VERSION ""

NS_ :

BS_:

BU_: FR_CMR FD_E CLU DATC RR_C_RDR CGW

BO_ 298 ADAS_CMD_30_10ms: 16 FR_CMR
 SG_ LKA_OptUsmSta : 24|3@1+ (1,0) [0|0] ""  CLU,CGW
 SG_ LKA_RcgSta : 27|3@1+ (1,0) [0|0] ""  CLU,CGW
 SG_ LKA_LHLnWrnSta : 30|2@1+ (1,0) [0|0] ""  CLU,CGW
 SG_ LKA_RHLnWrnSta : 32|2@1+ (1,0) [0|0] ""  CLU,CGW
 SG_ LKA_HndsoffSnd : 34|2@1+ (1,0) [0|0] ""  CLU,CGW
 SG_ LKA_StrSnd : 36|2@1+ (1,0) [0|0] ""  CLU,CGW
 SG_ LKA_SysIndReq : 38|3@1+ (1,0) [0|0] ""  CLU,RR_C_RDR,CGW
 SG_ ADAS_ActToiSta : 52|2@1+ (1,0) [0|0] ""  CLU,CGW
 SG_ LKA_SysWrn : 60|4@1+ (1,0) [0|0] ""  CLU,CGW
 SG_ LKA_UsmMod : 80|2@1+ (1,0) [0|0] ""  CLU,CGW

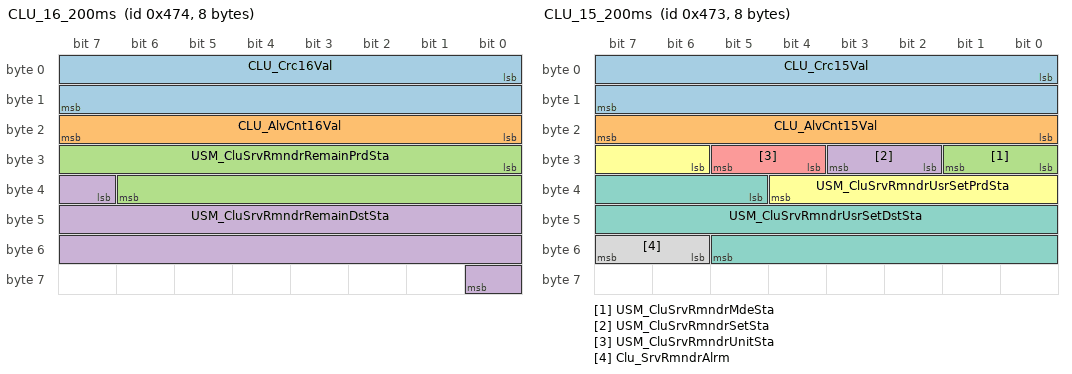
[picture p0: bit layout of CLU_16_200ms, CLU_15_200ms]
BO_ 1140 CLU_16_200ms: 8 CLU
 SG_ CLU_Crc16Val : 0|16@1+ (1,0) [0|0] ""  Vector__XXX
 SG_ CLU_AlvCnt16Val : 16|8@1+ (1,0) [0|0] ""  Vector__XXX
 SG_ USM_CluSrvRmndrRemainPrdSta : 24|15@1+ (1,0) [0|0] ""  CGW
 SG_ USM_CluSrvRmndrRemainDstSta : 39|18@1+ (1,0) [0|0] ""  CGW

BO_ 421 AWD_01_20ms: 32 CGW
 SG_ AWD_FrTqDistRto : 224|8@1+ (1,0) [0|0] "%"  CLU
 SG_ AWD_RrTqDistRto : 232|8@1+ (1,0) [0|0] "%"  CLU
 SG_ AWD_ErrCodeVal : 32|8@1+ (1,0) [0|0] ""  CLU
 SG_ AWD_OpModLkSta : 72|2@1+ (1,0) [0|0] ""  CLU

BO_ 1139 CLU_15_200ms: 8 CLU
 SG_ CLU_Crc15Val : 0|16@1+ (1,0) [0|0] ""  Vector__XXX
 SG_ CLU_AlvCnt15Val : 16|8@1+ (1,0) [0|0] ""  Vector__XXX
 SG_ USM_CluSrvRmndrMdeSta : 24|2@1+ (1,0) [0|0] ""  CGW
 SG_ USM_CluSrvRmndrSetSta : 26|2@1+ (1,0) [0|0] ""  CGW
 SG_ USM_CluSrvRmndrUnitSta : 28|2@1+ (1,0) [0|0] ""  CGW
 SG_ USM_CluSrvRmndrUsrSetPrdSta : 30|7@1+ (1,0) [0|0] ""  CGW
 SG_ USM_CluSrvRmndrUsrSetDstSta : 37|17@1+ (1,0) [0|0] ""  CGW
 SG_ Clu_SrvRmndrAlrm : 54|2@1+ (1,0) [0|0] ""  CGW

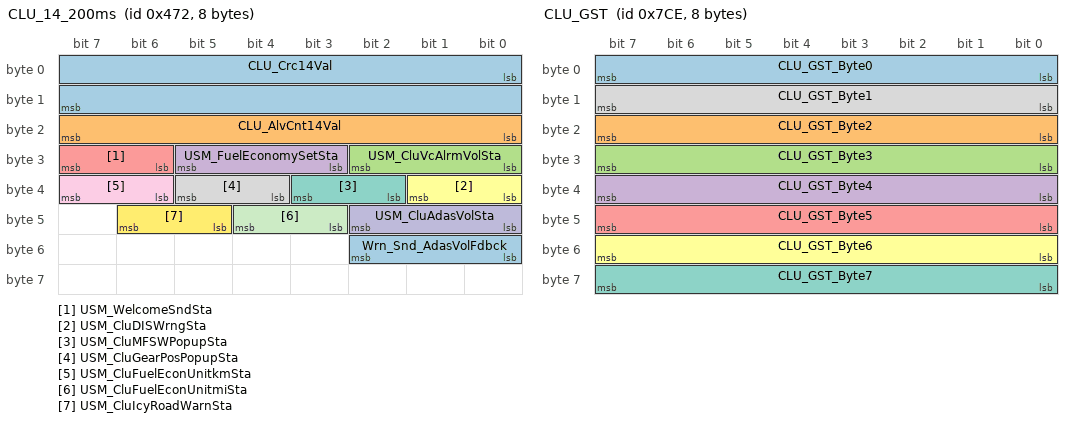
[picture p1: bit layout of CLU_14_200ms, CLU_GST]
BO_ 1138 CLU_14_200ms: 8 CLU
 SG_ CLU_Crc14Val : 0|16@1+ (1,0) [0|0] ""  Vector__XXX
 SG_ CLU_AlvCnt14Val : 16|8@1+ (1,0) [0|0] ""  Vector__XXX
 SG_ USM_CluVcAlrmVolSta : 24|3@1+ (1,0) [0|0] ""  CGW
 SG_ USM_FuelEconomySetSta : 27|3@1+ (1,0) [0|0] ""  CGW
 SG_ USM_WelcomeSndSta : 30|2@1+ (1,0) [0|0] ""  CGW
 SG_ USM_CluDISWrngSta : 32|2@1+ (1,0) [0|0] ""  CGW
 SG_ USM_CluMFSWPopupSta : 34|2@1+ (1,0) [0|0] ""  CGW
 SG_ USM_CluGearPosPopupSta : 36|2@1+ (1,0) [0|0] ""  CGW
 SG_ USM_CluFuelEconUnitkmSta : 38|2@1+ (1,0) [0|0] ""  CGW
 SG_ USM_CluAdasVolSta : 40|3@1+ (1,0) [0|0] ""  CGW
 SG_ USM_CluFuelEconUnitmiSta : 43|2@1+ (1,0) [0|0] ""  CGW
 SG_ USM_CluIcyRoadWarnSta : 45|2@1+ (1,0) [0|0] ""  CGW
 SG_ Wrn_Snd_AdasVolFdbck : 48|3@1+ (1,0) [0|0] ""  CGW

BO_ 1998 CLU_GST: 8 CLU
 SG_ CLU_GST_Byte0 : 0|8@1+ (1,0) [0|0] ""  CGW
 SG_ CLU_GST_Byte2 : 16|8@1+ (1,0) [0|0] ""  CGW
 SG_ CLU_GST_Byte3 : 24|8@1+ (1,0) [0|0] ""  CGW
 SG_ CLU_GST_Byte4 : 32|8@1+ (1,0) [0|0] ""  CGW
 SG_ CLU_GST_Byte5 : 40|8@1+ (1,0) [0|0] ""  CGW
 SG_ CLU_GST_Byte6 : 48|8@1+ (1,0) [0|0] ""  CGW
 SG_ CLU_GST_Byte7 : 56|8@1+ (1,0) [0|0] ""  CGW
 SG_ CLU_GST_Byte1 : 8|8@1+ (1,0) [0|0] ""  CGW

BO_ 898 DATC_05_200ms: 8 DATC
 SG_ DATC_TempDispUnitSta : 40|2@1+ (1,0) [0|0] ""  CLU,CGW

BO_ 181 EMS_01_10ms: 32 CGW
 SG_ ENG_IsgSta : 123|3@1+ (1,0) [0|0] ""  CLU,FR_CMR,DATC
 SG_ ENG_GearShftUpDis : 136|2@1+ (1,0) [0|0] ""  CLU
 SG_ ENG_GearShftDnDis : 138|2@1+ (1,0) [0|0] ""  CLU
 SG_ ENG_DsrGearPosDis : 140|4@1+ (1,0) [0|0] ""  CLU
 SG_ ENG_IsgBzrReq : 150|2@1+ (1,0) [0|0] ""  CLU
 SG_ ENG_Isg2Sta : 160|2@1+ (2,0) [0|0] ""  CLU
 SG_ ENG_EngSpdVal : 176|16@1+ (0.25,0) [0|0] "rpm"  CLU,FR_CMR
 SG_ ENG_FuelCnsmptVal : 200|16@1+ (0.128,0) [0|0] "ul"  CLU
 SG_ ENG_VehSpdLimVal : 247|9@1+ (1,0) [0|0] "km/h"  CLU
 SG_ ENG_EngSpdErrSta : 96|2@1+ (1,0) [0|0] ""  CLU,FR_CMR

BO_ 608 EMS_05_100ms: 32 CGW
 SG_ ENG_KNK_Warning : 228|1@1+ (1,0) [0|0] ""  CLU
 SG_ ENG_ImmoLmpSta : 24|2@1+ (1,0) [0|0] ""  CLU
 SG_ ENG_MilSta : 26|2@1+ (1,0) [0|0] ""  CLU

BO_ 64 TCU_01_10ms: 32 CGW
 SG_ TCU_EngRpmDisSta : 120|2@1+ (1,0) [0|0] ""  CLU
 SG_ TCU_EngRpmDis : 128|16@1+ (0.25,0) [0|0] "rpm"  CLU
 SG_ TCU_SprtyIndxSta : 155|5@1+ (1,0) [0|0] ""  CLU
 SG_ TCU_DrvngModDis : 160|3@1+ (1,0) [0|0] ""  CLU
 SG_ TCU_SmrtShftSta : 166|2@1+ (1,0) [0|0] ""  CLU
 SG_ TCU_ShftPtrnSta : 194|4@1+ (1,0) [0|0] ""  CLU
 SG_ TCU_GearSlctDis : 32|4@1+ (1,0) [0|0] ""  CLU,FR_CMR,RR_C_RDR
 SG_ TCU_Typ : 36|4@1+ (1,0) [0|0] ""  CLU
 SG_ TCU_TqRdctnVal : 40|12@1- (1,0) [0|0] "Nm"  CLU
 SG_ TCU_GearStepTyp : 56|4@1+ (1,0) [0|0] ""  CLU
 SG_ TCU_GearShftSta : 60|2@1+ (1,0) [0|0] ""  CLU
 SG_ TCU_CurrGearSta : 64|4@1+ (1,0) [0|0] ""  CLU
 SG_ TCU_TrgtGearSta : 68|4@1+ (1,0) [0|0] ""  CLU
 SG_ TCU_CluTrgtGearSta : 72|4@1+ (1,0) [0|0] ""  CLU
 SG_ TCU_CluTrgtGearConfg : 92|2@1+ (1,0) [0|0] ""  CLU

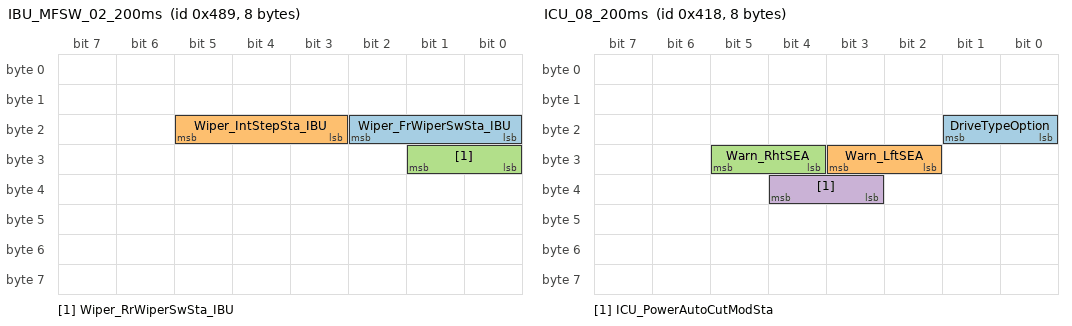
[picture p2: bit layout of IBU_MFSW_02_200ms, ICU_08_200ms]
BO_ 1161 IBU_MFSW_02_200ms: 8 CGW
 SG_ Wiper_FrWiperSwSta_IBU : 16|3@1+ (1,0) [0|0] ""  CLU
 SG_ Wiper_IntStepSta_IBU : 19|3@1+ (1,0) [0|0] ""  CLU
 SG_ Wiper_RrWiperSwSta_IBU : 24|2@1+ (1,0) [0|0] ""  CLU

BO_ 1160 IBU_MFSW_01_200ms: 8 CGW
 SG_ Lamp_LtSwSta_IBU : 20|2@1+ (1,0) [0|0] ""  CLU

BO_ 346 SCU_FF_01_10ms: 8 CGW
 SG_ SCU_FF_PosActSta : 24|4@1+ (1,0) [0|0] ""  CLU

BO_ 1167 ICU_11_1000ms: 8 CGW
 SG_ Bat_dischrg : 10|2@1+ (1,0) [0|0] ""  CLU

BO_ 1048 ICU_08_200ms: 8 CGW
 SG_ DriveTypeOption : 16|2@1+ (1,0) [0|0] ""  CLU
 SG_ Warn_LftSEA : 26|2@1+ (1,0) [0|0] ""  CLU
 SG_ Warn_RhtSEA : 28|2@1+ (1,0) [0|0] ""  CLU
 SG_ ICU_PowerAutoCutModSta : 35|2@1+ (1,0) [0|0] ""  CLU

BO_ 1050 BCM_07_200ms: 8 CGW
 SG_ Lamp_ExtrnlTailLmpOnReq : 38|2@1+ (1,0) [0|0] ""  CLU
 SG_ Lamp_AvTailLmpSta : 46|2@1+ (1,0) [0|0] ""  CLU

BO_ 325 DATC_01_20ms: 32 DATC
 SG_ DATC_OutTempSnsrVal : 168|8@1+ (0.5,-40) [0|0] "℃"  CLU,CGW

BO_ 1052 BCM_09_200ms: 8 CGW
 SG_ Lamp_AutoLtSnsrNightSta : 19|2@1+ (1,0) [0|0] ""  CLU,RR_C_RDR

BO_ 993 BCM_03_200ms: 8 CGW
 SG_ SBR_StBltWrngBzrSta : 16|3@1+ (1,0) [0|0] ""  CLU
 SG_ SBR_DrvStBltIndSta : 20|2@1+ (1,0) [0|0] ""  CLU

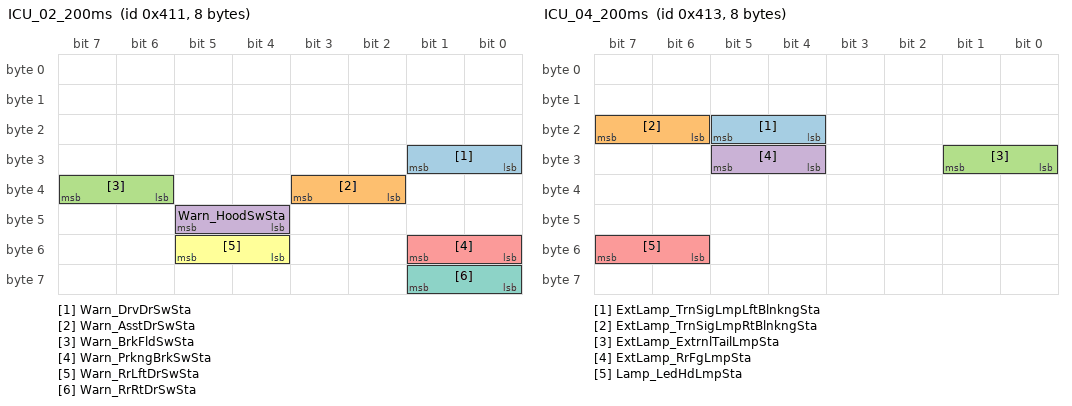
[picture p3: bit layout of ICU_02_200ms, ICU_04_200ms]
BO_ 1041 ICU_02_200ms: 8 CGW
 SG_ Warn_DrvDrSwSta : 24|2@1+ (1,0) [0|0] ""  CLU,FR_CMR
 SG_ Warn_AsstDrSwSta : 34|2@1+ (1,0) [0|0] ""  CLU,FR_CMR
 SG_ Warn_BrkFldSwSta : 38|2@1+ (1,0) [0|0] ""  CLU
 SG_ Warn_HoodSwSta : 44|2@1+ (1,0) [0|0] ""  CLU
 SG_ Warn_PrkngBrkSwSta : 48|2@1+ (1,0) [0|0] ""  CLU
 SG_ Warn_RrLftDrSwSta : 52|2@1+ (1,0) [0|0] ""  CLU,FR_CMR
 SG_ Warn_RrRtDrSwSta : 56|2@1+ (1,0) [0|0] ""  CLU,FR_CMR

BO_ 1040 ICU_10_200ms: 8 CGW
 SG_ ICU_BS2SoC : 16|8@1+ (1,0) [0|0] ""  CLU

BO_ 1043 ICU_04_200ms: 8 CGW
 SG_ ExtLamp_TrnSigLmpLftBlnkngSta : 20|2@1+ (1,0) [0|0] ""  CLU,FR_CMR,RR_C_RDR
 SG_ ExtLamp_TrnSigLmpRtBlnkngSta : 22|2@1+ (1,0) [0|0] ""  CLU,FR_CMR,RR_C_RDR
 SG_ ExtLamp_ExtrnlTailLmpSta : 24|2@1+ (1,0) [0|0] ""  CLU
 SG_ ExtLamp_RrFgLmpSta : 28|2@1+ (1,0) [0|0] ""  CLU
 SG_ Lamp_LedHdLmpSta : 54|2@1+ (1,0) [0|0] ""  CLU

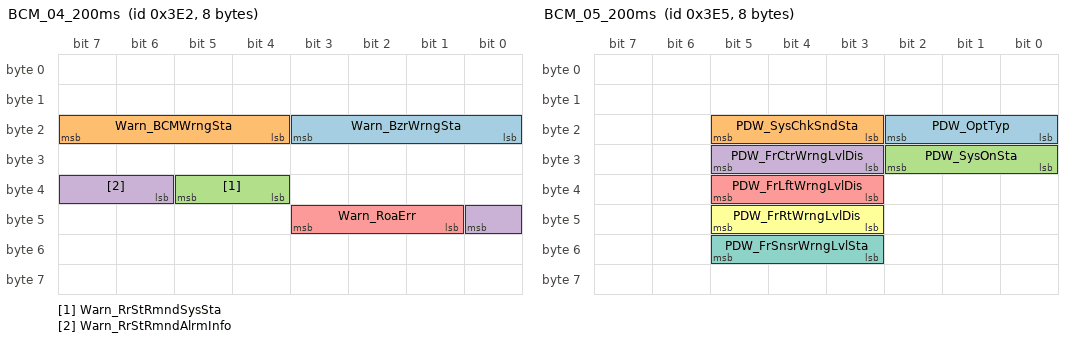
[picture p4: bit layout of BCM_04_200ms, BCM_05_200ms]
BO_ 994 BCM_04_200ms: 8 CGW
 SG_ Warn_BzrWrngSta : 16|4@1+ (1,0) [0|0] ""  CLU
 SG_ Warn_BCMWrngSta : 20|4@1+ (1,0) [0|0] ""  CLU
 SG_ Warn_RrStRmndSysSta : 36|2@1+ (1,0) [0|0] ""  CLU
 SG_ Warn_RrStRmndAlrmInfo : 38|3@1+ (1,0) [0|0] ""  CLU
 SG_ Warn_RoaErr : 41|3@1+ (1,0) [0|0] ""  CLU

BO_ 1042 ICU_03_200ms: 8 CGW
 SG_ ExtLamp_StpLmpLftOpnSta : 40|2@1+ (1,0) [0|0] ""  CLU
 SG_ ExtLamp_StpLmpRtOpnSta : 42|2@1+ (1,0) [0|0] ""  CLU

BO_ 997 BCM_05_200ms: 8 CGW
 SG_ PDW_OptTyp : 16|3@1+ (1,0) [0|0] ""  CLU
 SG_ PDW_SysChkSndSta : 19|3@1+ (1,0) [0|0] ""  CLU
 SG_ PDW_SysOnSta : 24|3@1+ (1,0) [0|0] ""  CLU
 SG_ PDW_FrCtrWrngLvlDis : 27|3@1+ (1,0) [0|0] ""  CLU
 SG_ PDW_FrLftWrngLvlDis : 35|3@1+ (1,0) [0|0] ""  CLU
 SG_ PDW_FrRtWrngLvlDis : 43|3@1+ (1,0) [0|0] ""  CLU
 SG_ PDW_FrSnsrWrngLvlSta : 51|3@1+ (1,0) [0|0] ""  CLU

BO_ 1044 ICU_05_200ms: 8 CGW
 SG_ Trunk_TrnkTlgtSwSta : 20|2@1+ (1,0) [0|0] ""  CLU
 SG_ USM_OneTouchTrnSigFuncSta : 34|3@1+ (1,0) [0|0] ""  CLU

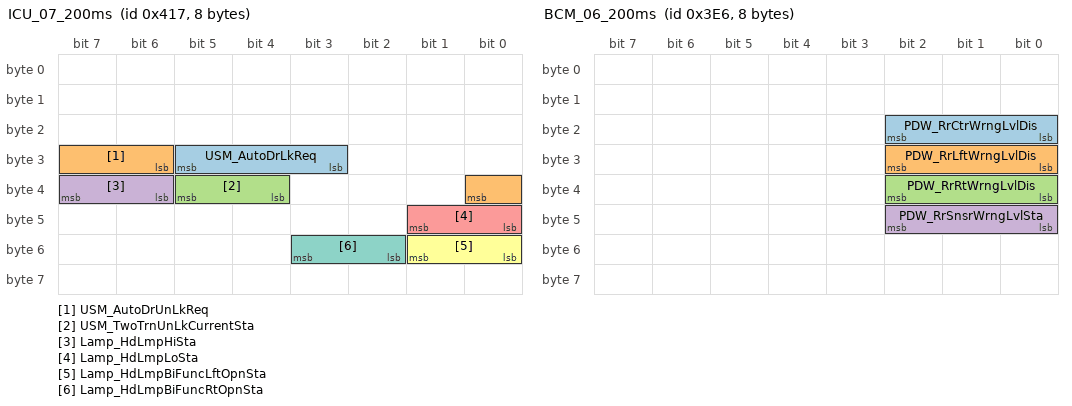
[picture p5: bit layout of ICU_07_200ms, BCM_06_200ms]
BO_ 1047 ICU_07_200ms: 8 CGW
 SG_ USM_AutoDrLkReq : 27|3@1+ (1,0) [0|0] ""  CLU
 SG_ USM_AutoDrUnLkReq : 30|3@1+ (1,0) [0|0] ""  CLU
 SG_ USM_TwoTrnUnLkCurrentSta : 36|2@1+ (1,0) [0|0] ""  CLU
 SG_ Lamp_HdLmpHiSta : 38|2@1+ (1,0) [0|0] ""  CLU,FR_CMR
 SG_ Lamp_HdLmpLoSta : 40|2@1+ (1,0) [0|0] ""  CLU
 SG_ Lamp_HdLmpBiFuncLftOpnSta : 48|2@1+ (1,0) [0|0] ""  CLU
 SG_ Lamp_HdLmpBiFuncRtOpnSta : 50|2@1+ (1,0) [0|0] ""  CLU

BO_ 998 BCM_06_200ms: 8 CGW
 SG_ PDW_RrCtrWrngLvlDis : 16|3@1+ (1,0) [0|0] ""  CLU
 SG_ PDW_RrLftWrngLvlDis : 24|3@1+ (1,0) [0|0] ""  CLU
 SG_ PDW_RrRtWrngLvlDis : 32|3@1+ (1,0) [0|0] ""  CLU
 SG_ PDW_RrSnsrWrngLvlSta : 40|3@1+ (1,0) [0|0] ""  CLU

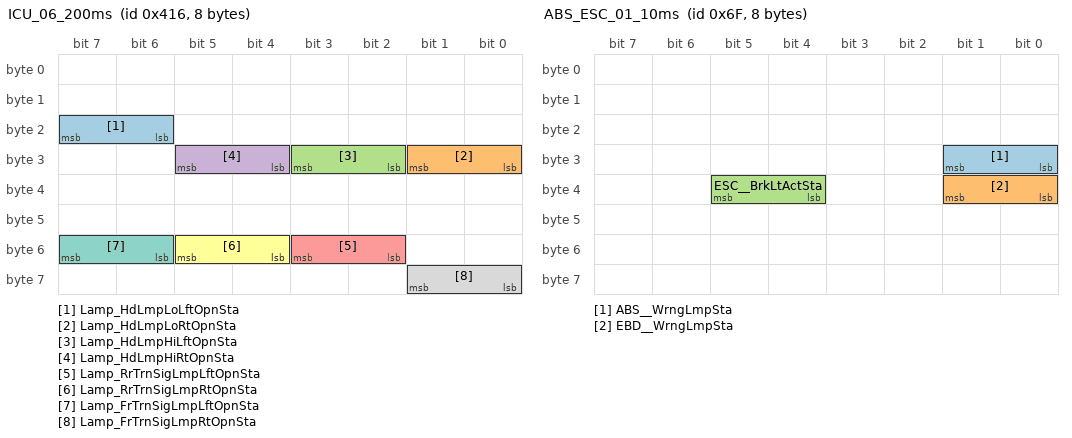
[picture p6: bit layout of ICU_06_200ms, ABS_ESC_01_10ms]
BO_ 1046 ICU_06_200ms: 8 CGW
 SG_ Lamp_HdLmpLoLftOpnSta : 22|2@1+ (1,0) [0|0] ""  CLU
 SG_ Lamp_HdLmpLoRtOpnSta : 24|2@1+ (1,0) [0|0] ""  CLU
 SG_ Lamp_HdLmpHiLftOpnSta : 26|2@1+ (1,0) [0|0] ""  CLU
 SG_ Lamp_HdLmpHiRtOpnSta : 28|2@1+ (1,0) [0|0] ""  CLU
 SG_ Lamp_RrTrnSigLmpLftOpnSta : 50|2@1+ (1,0) [0|0] ""  CLU
 SG_ Lamp_RrTrnSigLmpRtOpnSta : 52|2@1+ (1,0) [0|0] ""  CLU
 SG_ Lamp_FrTrnSigLmpLftOpnSta : 54|2@1+ (1,0) [0|0] ""  CLU
 SG_ Lamp_FrTrnSigLmpRtOpnSta : 56|2@1+ (1,0) [0|0] ""  CLU

BO_ 234 MDPS_01_10ms: 24 CGW
 SG_ MDPS_LoamModSta : 112|2@1+ (1,0) [0|0] ""  CLU
 SG_ MDPS_WrngLmpSta : 24|3@1+ (1,0) [0|0] ""  CLU

BO_ 96 ESC_01_10ms: 32 CGW
 SG_ AVH_CluDis : 208|8@1+ (1,0) [0|0] ""  CLU
 SG_ AVH_AlrmReq : 216|2@1+ (1,0) [0|0] ""  CLU
 SG_ AVH_LmpDis : 220|3@1+ (1,0) [0|0] ""  CLU
 SG_ TCS_LmpSta : 40|2@1+ (1,0) [0|0] ""  CLU
 SG_ TCS_OffLmpSta : 42|2@1+ (1,0) [0|0] ""  CLU
 SG_ ESC_OffTempSta : 44|2@1+ (1,0) [0|0] ""  CLU
 SG_ DBC_WrngLmpSta : 48|2@1+ (1,0) [0|0] ""  CLU
 SG_ DBC_FuncLmpSta : 50|2@1+ (1,0) [0|0] ""  CLU
 SG_ DBC_ClusterDis : 52|2@1+ (1,0) [0|0] ""  CLU
 SG_ DBC_Sta : 80|4@1+ (1,0) [0|0] ""  CLU

BO_ 1058 BCM_10_200ms: 8 CGW
 SG_ BCM_SunRoofOpnSta : 52|2@1+ (1,0) [0|0] ""  CLU,DATC

BO_ 111 ABS_ESC_01_10ms: 8 CGW
 SG_ ABS__WrngLmpSta : 24|2@1+ (1,0) [0|0] ""  CLU
 SG_ EBD__WrngLmpSta : 32|2@1+ (1,0) [0|0] ""  CLU
 SG_ ESC__BrkLtActSta : 36|2@1+ (1,0) [0|0] ""  CLU

BO_ 106 TCU_02_10ms: 32 CGW
 SG_ TCU_ActvEcoRdySta : 68|2@1+ (1,0) [0|0] ""  CLU

BO_ 496 EPB_01_50ms: 16 CGW
 SG_ EPB_LmpStaDis : 24|4@1+ (1,0) [0|0] ""  CLU
 SG_ EPB_FlrLmpStaDis : 28|4@1+ (1,0) [0|0] ""  CLU
 SG_ EPB_OutDataDis : 32|8@1+ (1,0) [0|0] ""  CLU
 SG_ EPB_AlrmReq : 40|2@1+ (1,0) [0|0] ""  CLU

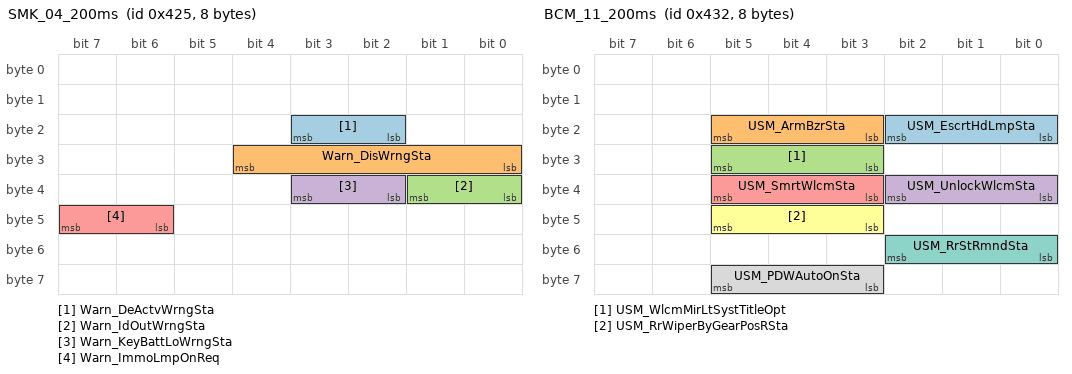
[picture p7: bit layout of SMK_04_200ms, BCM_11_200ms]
BO_ 1061 SMK_04_200ms: 8 CGW
 SG_ Warn_DeActvWrngSta : 18|2@1+ (1,0) [0|0] ""  CLU
 SG_ Warn_DisWrngSta : 24|5@1+ (1,0) [0|0] ""  CLU
 SG_ Warn_IdOutWrngSta : 32|2@1+ (1,0) [0|0] ""  CLU
 SG_ Warn_KeyBattLoWrngSta : 34|2@1+ (1,0) [0|0] ""  CLU
 SG_ Warn_ImmoLmpOnReq : 46|2@1+ (1,0) [0|0] ""  CLU

BO_ 352 ADAS_CMD_10_20ms: 16 FR_CMR
 SG_ FCA_OnOffEquipSta : 24|3@1+ (1,0) [0|0] ""  CLU,CGW
 SG_ FCA_SysFlrSta : 27|3@1+ (1,0) [0|0] ""  CLU,CGW
 SG_ FCA_WrngLvlSta : 30|2@1+ (1,0) [0|0] ""  CLU,CGW
 SG_ FCA_VehStpReq : 32|2@1+ (1,0) [0|0] ""  CLU,CGW
 SG_ FCA_SnstvtyModRetVal : 56|3@1+ (1,0) [0|0] ""  CLU,CGW
 SG_ FCA_WrngTrgtDis : 88|5@1+ (1,0) [0|0] ""  CLU,CGW

BO_ 720 TCU_03_100ms: 32 CGW
 SG_ TCU_WrngMsgSta : 24|8@1+ (1,0) [0|0] ""  CLU
 SG_ TCU_VehStpTimeDis : 32|5@1+ (1,0) [0|0] ""  CLU
 SG_ TCU_CurCltTemp : 64|2@1+ (1,0) [0|0] ""  CLU
 SG_ TCU_AvgCltTemp : 66|4@1+ (1,0) [0|0] ""  CLU
 SG_ DCT_HillHldWrng : 80|2@1+ (1,0) [0|0] ""  CLU
 SG_ DCT_CltchBrstWrng : 82|2@1+ (1,0) [0|0] ""  CLU
 SG_ DCT_WrngSndSta : 84|4@1+ (1,0) [0|0] ""  CLU

BO_ 485 RR_C_RDR_01_50ms: 16 RR_C_RDR
 SG_ RCCW_Sta : 24|4@1+ (1,0) [0|0] ""  CLU,CGW
 SG_ RCCW_OnOffEquipSt : 28|2@1+ (1,0) [0|0] ""  CLU,CGW
 SG_ RCCW_LftIndSta : 30|2@1+ (1,0) [0|0] ""  CLU,CGW
 SG_ RCCW_RtIndSta : 32|2@1+ (1,0) [0|0] ""  CLU,CGW
 SG_ RCCW_LftSndWrngSta : 34|2@1+ (1,0) [0|0] ""  CLU,CGW
 SG_ RCCW_RtSndWrngSta : 36|2@1+ (1,0) [0|0] ""  CLU,CGW
 SG_ RCCW_LftWrngIndBriLvlVal : 40|8@1+ (1,0) [0|0] ""  CLU,CGW
 SG_ RCCW_RtWrngIndBriLvlVal : 48|8@1+ (1,0) [0|0] ""  CLU,CGW
 SG_ RCCA_LftWrngSta : 70|2@1+ (1,0) [0|0] ""  CLU,CGW
 SG_ RCCA_RtWrngSta : 72|2@1+ (1,0) [0|0] ""  CLU,CGW
 SG_ RCCA_FuncStat : 77|2@1+ (1,0) [0|0] ""  CLU,CGW
 SG_ RCCA_Sta : 80|4@1+ (1,0) [0|0] ""  CLU,CGW
 SG_ RCCA_OnOffEquipSt : 84|2@1+ (1,0) [0|0] ""  CLU,CGW
 SG_ SEA_Sta : 88|4@1+ (1,0) [0|0] ""  CLU,CGW
 SG_ SEA_OnOffEquipSta : 92|2@1+ (1,0) [0|0] ""  CLU,CGW
 SG_ SEA_LftWrngSta : 94|2@1+ (1,0) [0|0] ""  CLU,CGW
 SG_ SEA_RtWrngSta : 96|2@1+ (1,0) [0|0] ""  CLU,CGW

BO_ 1074 BCM_11_200ms: 8 CGW
 SG_ USM_EscrtHdLmpSta : 16|3@1+ (1,0) [0|0] ""  CLU
 SG_ USM_ArmBzrSta : 19|3@1+ (1,0) [0|0] ""  CLU
 SG_ USM_WlcmMirLtSystTitleOpt : 27|3@1+ (1,0) [0|0] ""  CLU
 SG_ USM_UnlockWlcmSta : 32|3@1+ (1,0) [0|0] ""  CLU
 SG_ USM_SmrtWlcmSta : 35|3@1+ (1,0) [0|0] ""  CLU
 SG_ USM_RrWiperByGearPosRSta : 43|3@1+ (1,0) [0|0] ""  CLU
 SG_ USM_RrStRmndSta : 48|3@1+ (1,0) [0|0] ""  CLU
 SG_ USM_PDWAutoOnSta : 59|3@1+ (1,0) [0|0] ""  CLU

BO_ 480 ADAS_CMD_31_50ms: 16 FR_CMR
 SG_ HDA_OptUsmSta : 24|3@1+ (1,0) [0|0] ""  CLU,CGW
 SG_ HDA_CntrlModSta : 30|2@1+ (1,0) [0|0] ""  CLU,CGW
 SG_ HDA_InfoPUDis : 32|3@1+ (1,0) [0|0] ""  CLU,CGW
 SG_ HDA_LFA_SymSta : 47|2@1+ (1,0) [0|0] ""  CLU,CGW
 SG_ HDA_LFA_WrnSnd : 49|2@1+ (1,0) [0|0] ""  CLU,CGW
 SG_ HDA_InfoPUDis1 : 51|3@1+ (1,0) [0|0] ""  CLU,CGW

CM_ BO_ 111 "[P] Periodic";
CM_ SG_ 111 ABS__WrngLmpSta "ABS_WarningLampStatus ##2G##ESC - TCS15 - ABS_W_LAMP";
CM_ SG_ 111 EBD__WrngLmpSta "EBD_WarningLampStatus ##2G##ESC - TCS15 - EBD_W_LAMP";
CM_ SG_ 111 ESC__BrkLtActSta "ESC_BrakeLightActiveStatus ##2G##ESC - TCS11 - BLA_CTL";
CM_ BO_ 352 "[P] Periodic";
CM_ SG_ 352 FCA_OnOffEquipSta "FCA_OnOffEquipmentStatus ##2G##FCA - FCA12 - FCA_USM";
CM_ SG_ 352 FCA_SysFlrSta "FCA_SystemFailureStatus ##2G##FCA - FCA11 - FCA_Failinfo";
CM_ SG_ 352 FCA_WrngLvlSta "FCA_WarningLevelStatus ##2G##FCA - FCA11 - CF_VSM_Warn";
CM_ SG_ 352 FCA_VehStpReq "FCA_VehicleStopRequest ##2G##FCA - FCA11 - FCA_StopReq";
CM_ SG_ 352 FCA_SnstvtyModRetVal "FCA_SensitivityModeReturnValue ##2G##FCA - FCA12 - FCA_DrvSetState";
CM_ SG_ 352 FCA_WrngTrgtDis "FCA_WarningTargetDisplay";
CM_ BO_ 298 "[P] Periodic";
CM_ SG_ 298 LKA_OptUsmSta "LKA_OptionUsmStatus ##2G##LDW_LKA - LKA11 - CF_LKA_Opt_USM";
CM_ SG_ 298 LKA_RcgSta "LKA_RecognitionStatus ##2G##LDW_LKA - LKA11 - CF_LKA_LaneRecogState";
CM_ SG_ 298 LKA_LHLnWrnSta "LKA_LHLaneWarningStatus ##2G##LDW_LKA - LKA11 - CF_LKA_LHWarning";
CM_ SG_ 298 LKA_RHLnWrnSta "LKA_RHLaneWarningStatus ##2G##LDW_LKA - LKA11 - CF_LKA_RHWarning";
CM_ SG_ 298 LKA_HndsoffSnd "LKA_HandsoffSound ##2G##LDW_LKA - LKA11 - CF_LKA_HandsOff_Snd";
CM_ SG_ 298 LKA_StrSnd "LKA_SteeringSound ##2G##LDW_LKA - LKA11 - CF_LKA_Steer_Snd";
CM_ SG_ 298 LKA_SysIndReq "LKA_SystemIndicatorRequest ##2G##LDW_LKA - LKA11 - CF_LKA_SymbolState";
CM_ SG_ 298 ADAS_ActToiSta "ADAS_ActiveTorqueOverlayInterfaceStatus ##2G##LDW_LKA - LKA11 - CF_LKA_ActToi";
CM_ SG_ 298 LKA_SysWrn "LKA_Additional_Info";
CM_ SG_ 298 LKA_UsmMod "LKA_USM Mode ##2G##LDW_LKA-LKA11-CF_LKA_USM_Mode";
CM_ BO_ 480 "[P] Periodic";
CM_ SG_ 480 HDA_OptUsmSta "HDA_OptionUSMStatus ##2G##LDW_LKA - HDA11 - CF_HDA_Opt_USM";
CM_ SG_ 480 HDA_CntrlModSta "HDA_ControlModeStatus ##2G##LDW_LKA - HDA11 - CF_HDA_Mode";
CM_ SG_ 480 HDA_InfoPUDis "HDA_InformationPopUpDisplay ##2G##LDW_LKA - HDA11 - CF_HDA_InfoDisplay";
CM_ SG_ 480 HDA_LFA_SymSta "HDA_LFA_SymbolStatus ##2G##LDW_LKA - HDA11 - CF_HDA_LFA_SymbolState";
CM_ SG_ 480 HDA_LFA_WrnSnd "HDA/LFA Additional Warning Sound";
CM_ SG_ 480 HDA_InfoPUDis1 "HDA_InfomationPopupDisplay";
CM_ BO_ 421 "[P] Periodic";
CM_ SG_ 421 AWD_FrTqDistRto "Torque Distribution ratio to Front Wheel";
CM_ SG_ 421 AWD_RrTqDistRto "Torque Distribution ratio to Rear Wheel";
CM_ SG_ 421 AWD_ErrCodeVal "AWD_ErrorCodeValue";
CM_ SG_ 421 AWD_OpModLkSta "AWD_OperationModeLockStatus";
CM_ BO_ 993 "[PE] Periodic and On Event";
CM_ SG_ 993 SBR_StBltWrngBzrSta "SBR_SeatBeltWarningBuzzerStatus ##2G##BCM - BCMmsg32 - C_SeatBeltWngBuz";
CM_ SG_ 993 SBR_DrvStBltIndSta "SBR_DriverSeatBeltIndicatorStatus ##2G##BCM - BCMmsg32 - C_DrvSeatBeltInd";
CM_ BO_ 994 "[PE] Periodic and On Event";
CM_ SG_ 994 Warn_BzrWrngSta "Warn_BuzzerWarningStatus ##2G##BCM - BCMmsg18 - C_WngBuz";
CM_ SG_ 994 Warn_BCMWrngSta "Warn_BCMWarningStatus ##2G##BCM - BCMmsg19 - C_BCMWarning";
CM_ SG_ 994 Warn_RrStRmndSysSta "Warn_RearSeatReminderSystemStatus ##2G##BCM - BCMmsg22 - C_RrSeatRemindState";
CM_ SG_ 994 Warn_RrStRmndAlrmInfo "Warn_RearSeatReminderAlarmInformaion ##2G##BCM - BCMmsg22 - C_RrSeatRemindInfo";
CM_ SG_ 994 Warn_RoaErr "Warn_RoaError##2G##BCM - BCMmsg22 - C_RoaError";
CM_ BO_ 997 "[PE] Periodic and On Event";
CM_ SG_ 997 PDW_OptTyp "PDW_OptionType ##2G##BCM - BCMmsg18 - C_PASOption";
CM_ SG_ 997 PDW_SysChkSndSta "PDW_SystemCheckSoundStatus ##2G##BCM - BCMmsg18 - C_PASCheckSound";
CM_ SG_ 997 PDW_SysOnSta "PDW_SystemOnStatus ##2G##BCM - BCMmsg18 - C_PASSystemOn";
CM_ SG_ 997 PDW_FrCtrWrngLvlDis "PDW_FrontCenterWarningLevelDisplay ##2G##BCM - BCMmsg18 - C_PASDisplayFCTR";
CM_ SG_ 997 PDW_FrLftWrngLvlDis "PDW_FrontLeftWarningLevelDisplay ##2G##BCM - BCMmsg18 - C_PASDisplayFLH";
CM_ SG_ 997 PDW_FrRtWrngLvlDis "PDW_FrontRightWarningLevelDisplay ##2G##BCM - BCMmsg18 - C_PASDisplayFRH";
CM_ SG_ 997 PDW_FrSnsrWrngLvlSta "PDW_FrontSensorWarningLevelStatus ##2G##BCM - BCMmsg18 - C_PASFsound";
CM_ BO_ 998 "[PE] Periodic and On Event";
CM_ SG_ 998 PDW_RrCtrWrngLvlDis "PDW_RearCenterWarningLevelDisplay ##2G##BCM - BCMmsg18 - C_PASDisplayRCTR";
CM_ SG_ 998 PDW_RrLftWrngLvlDis "PDW_RearLeftWarningLevelDisplay ##2G##BCM - BCMmsg18 - C_PASDisplayRLH";
CM_ SG_ 998 PDW_RrRtWrngLvlDis "PDW_RearRightWarningLevelDisplay ##2G##BCM - BCMmsg18 - C_PASDisplayRRH";
CM_ SG_ 998 PDW_RrSnsrWrngLvlSta "PDW_RearSensorWarningLevelStatus ##2G##BCM - BCMmsg18 - C_PASRsound";
CM_ BO_ 1050 "[PE] Periodic and On Event";
CM_ SG_ 1050 Lamp_ExtrnlTailLmpOnReq "Lamp_ExternalTailLampOnRequest ##2G##BCM - BCMmsg19 - C_ExtTailOn";
CM_ SG_ 1050 Lamp_AvTailLmpSta "Lamp_AvTailLampStatus ##2G##BCM - BCMmsg18 - C_AvTail";
CM_ BO_ 1052 "[PE] Periodic and On Event";
CM_ SG_ 1052 Lamp_AutoLtSnsrNightSta "Lamp_AutoLightSensorNightStatus ##2G##BCM - BCMmsg24 - C_AutolightValue";
CM_ BO_ 1058 "[PE] Periodic and On Event";
CM_ SG_ 1058 BCM_SunRoofOpnSta "BCM_SunRoofOpenStatus ##2G##BCM - BCMmsg20 - C_SunRoofOpenState";
CM_ BO_ 1074 "[PE] Periodic and On Event";
CM_ SG_ 1074 USM_EscrtHdLmpSta "USM_EscortHeadLampStatus ##2G##BCM - BCMmsg21 - C_EscortHLRValue";
CM_ SG_ 1074 USM_ArmBzrSta "USM_ArmBuzzerStatus ##2G##BCM - BCMmsg21 - C_HAnBRValue";
CM_ SG_ 1074 USM_WlcmMirLtSystTitleOpt "USM_WelcomeMirrLightSystemTitleOption ##2G##BCM - BCMmsg21 - C_WelcomeSysTitleOption";
CM_ SG_ 1074 USM_UnlockWlcmSta "USM_UnlockWelcomeStatus ##2G##BCM - BCMmsg21 - C_UnlockWelcomeRValue";
CM_ SG_ 1074 USM_SmrtWlcmSta "USM_SmartWelcomeStatus ##2G##BCM - BCMmsg21 - C_SmartWelcomeRValue";
CM_ SG_ 1074 USM_RrWiperByGearPosRSta "USM_RearWiperByGearPositionReverseStatus ##2G##BCM - BCMmsg21 - C_RearWiperRValue";
CM_ SG_ 1074 USM_RrStRmndSta "USM_RearSeatReminderStatus ##2G##BCM - BCMmsg21 - C_RrSeatRemindRValue";
CM_ SG_ 1074 USM_PDWAutoOnSta "USM_PDW system automatically setteing ##2G##BCM - BCMmsg21 - C_PDWAutoOnRValue";
CM_ BO_ 1138 "[PE] Periodic and On Event";
CM_ SG_ 1138 CLU_Crc14Val "CLU_CyclicRedundancyCheck14Value";
CM_ SG_ 1138 CLU_AlvCnt14Val "CLU_AliveCounter14Value";
CM_ SG_ 1138 USM_CluVcAlrmVolSta "USM_ClusterVoiceAlarmVolumeStatus";
CM_ SG_ 1138 USM_FuelEconomySetSta "USM_FuelEconomySetStatus";
CM_ SG_ 1138 USM_WelcomeSndSta "USM_WelcomeSoundStatus";
CM_ SG_ 1138 USM_CluDISWrngSta "USM_CLUDISWarningStatus";
CM_ SG_ 1138 USM_CluMFSWPopupSta "USM_ClusterMFSWPopupStatus";
CM_ SG_ 1138 USM_CluGearPosPopupSta "USM_CluGearPositionPopupStatus";
CM_ SG_ 1138 USM_CluFuelEconUnitkmSta "USM_CluFuelEconomyUnitkmStatus";
CM_ SG_ 1138 USM_CluAdasVolSta "USM_CluAdasVolumeStatus";
CM_ SG_ 1138 USM_CluFuelEconUnitmiSta "USM_CluFuelEconomyUnitmileStatus";
CM_ SG_ 1138 USM_CluIcyRoadWarnSta "USM_CluIcyRoadWarningStatus";
CM_ SG_ 1138 Wrn_Snd_AdasVolFdbck "2nd general signal : Warn_AdasVolumeFeedback";
CM_ BO_ 1139 "[PE] Periodic and On Event";
CM_ SG_ 1139 CLU_Crc15Val "CLU_CyclicRedundancyCheck15Value";
CM_ SG_ 1139 CLU_AlvCnt15Val "CLU_AliveCounter15Value";
CM_ SG_ 1139 USM_CluSrvRmndrMdeSta "USM_CluServiceReminderModeStatus";
CM_ SG_ 1139 USM_CluSrvRmndrSetSta "USM_CluServiceReminderSetStatus";
CM_ SG_ 1139 USM_CluSrvRmndrUnitSta "USM_CluServiceReminderUnitStatus";
CM_ SG_ 1139 USM_CluSrvRmndrUsrSetPrdSta "USM_CluServiceReminderUserSetPeriodStatus";
CM_ SG_ 1139 USM_CluSrvRmndrUsrSetDstSta "USM_CluServiceReminderUserSetDistanceStatus";
CM_ SG_ 1139 Clu_SrvRmndrAlrm "Service Reminder Alarm Display for AVN";
CM_ BO_ 1140 "[PE] Periodic and On Event";
CM_ SG_ 1140 CLU_Crc16Val "CLU_CyclicRedundancyCheck16Value";
CM_ SG_ 1140 CLU_AlvCnt16Val "CLU_AliveCounter16Value";
CM_ SG_ 1140 USM_CluSrvRmndrRemainPrdSta "USM_CluServiceReminderRemainPeriodStatus";
CM_ SG_ 1140 USM_CluSrvRmndrRemainDstSta "USM_CluServiceReminderRemainDistanceStatus";
CM_ BO_ 1998 "[EW] On Event and On Write";
CM_ BO_ 325 "[P] Periodic";
CM_ SG_ 325 DATC_OutTempSnsrVal "DATC_OutsideTemperatureSensorValue";
CM_ BO_ 898 "[PE] Periodic and On Event";
CM_ SG_ 898 DATC_TempDispUnitSta "DATC_TemperatureDiplayUnitStatus";
CM_ BO_ 181 "[P] Periodic";
CM_ SG_ 181 ENG_IsgSta "ENG_IsgStatus ##2G##EMS - EMS_H12 - CF_Ems_IsgStat";
CM_ SG_ 181 ENG_GearShftUpDis "ENG_GearShiftUpDisplay ##2G##EMS - EMS_H12 - CF_Ems_UpTarGr";
CM_ SG_ 181 ENG_GearShftDnDis "ENG_GearShiftDownDisplay ##2G##EMS - EMS_H12 - CF_Ems_DownTarGr";
CM_ SG_ 181 ENG_DsrGearPosDis "ENG_DesirableGearPositionDisplay ##2G##EMS - EMS_H12 - CF_Ems_DesCurGr";
CM_ SG_ 181 ENG_IsgBzrReq "ENG_IsgBuzzerRequest ##2G##EMS - EMS_H12 - CF_Ems_IsgBuz";
CM_ SG_ 181 ENG_Isg2Sta "ENG_Isg2Status ##2G##EMS - EMS_H12 - CF_Ems_IsgStat2";
CM_ SG_ 181 ENG_EngSpdVal "ENG_EngineSpeedValue ##2G##EMS - EMS11 - N";
CM_ SG_ 181 ENG_FuelCnsmptVal "ENG_FuelConsumptionValue ##2G##EMS - EMS20 - FCO";
CM_ SG_ 181 ENG_VehSpdLimVal "ENG_VehicleSpeedLimitValue ##2G##EMS - EMS_H12 - SLD_VS, EMS20-SLD_VS_EXT";
CM_ SG_ 181 ENG_EngSpdErrSta "ENG_EngineSpeedErrorStatus ##2G##EMS - EMS11 - F_N_ENG";
CM_ BO_ 608 "[P] Periodic";
CM_ SG_ 608 ENG_KNK_Warning "This signal indicates the result of KNK diagnosis. (KSDS)";
CM_ SG_ 608 ENG_ImmoLmpSta "ENG_ImmobilizerLampStatus ##2G##EMS - EMS14 - IMMO_LAMP_STAT";
CM_ SG_ 608 ENG_MilSta "ENG_MalfunctionIndicationLampStatus ##2G##EMS - EMS14 - L_MIL";
CM_ BO_ 496 "[P] Periodic";
CM_ SG_ 496 EPB_LmpStaDis "EPB_LampStateDisplay ##2G##EPB - EPB11 - EPB_I_LAMP";
CM_ SG_ 496 EPB_FlrLmpStaDis "EPB_FailureLampStateDisplay ##2G##EPB - EPB11 - EPB_F_LAMP";
CM_ SG_ 496 EPB_OutDataDis "EPB_OutputDataDisplay ##2G##EPB - EPB11 - EPB_CLU";
CM_ SG_ 496 EPB_AlrmReq "EPB_AlarmRequest ##2G##EPB - EPB11 - EPB_ALARM";
CM_ BO_ 96 "[P] Periodic";
CM_ SG_ 96 AVH_CluDis "AVH_ClusterDisplay ##2G##ESC - TCS15 - AVH_CLU";
CM_ SG_ 96 AVH_AlrmReq "AVH_AlarmRequest ##2G##ESC - TCS15 - AVH_ALARM";
CM_ SG_ 96 AVH_LmpDis "AVH_LampDisplay ##2G##ESC - TCS15 - AVH_LAMP";
CM_ SG_ 96 TCS_LmpSta "TCS_LampStatus ##2G##ESC - TCS15 - TCS_LAMP";
CM_ SG_ 96 TCS_OffLmpSta "TCS_OffLampStatus ##2G##ESC - TCS15 - TCS_OFF_LAMP";
CM_ SG_ 96 ESC_OffTempSta "ESC_OffStepStatus ##2G##ESC - TCS15 - ESC_Off_Step";
CM_ SG_ 96 DBC_WrngLmpSta "DBC_WarningLampStatus ##2G##ESC - TCS15 - DBC_W_LAMP";
CM_ SG_ 96 DBC_FuncLmpSta "DBC_FuncitonLampStatus ##2G##ESC - TCS15 - DBC_F_LAMP";
CM_ SG_ 96 DBC_ClusterDis "DBC Pop-up Signal for Deactivation";
CM_ SG_ 96 DBC_Sta "Status of DBC Function";
CM_ BO_ 1160 "[PE] Periodic and On Event";
CM_ SG_ 1160 Lamp_LtSwSta_IBU "Lamp_LightSwitchStatus";
CM_ BO_ 1161 "[PE] Periodic and On Event";
CM_ SG_ 1161 Wiper_FrWiperSwSta_IBU "Wiper_FrontWiperSwitchStatus";
CM_ SG_ 1161 Wiper_IntStepSta_IBU "Wiper_IntermittentStepStatus";
CM_ SG_ 1161 Wiper_RrWiperSwSta_IBU "Wiper_RearWiperSwitchStatus";
CM_ BO_ 1041 "[PE] Periodic and On Event";
CM_ SG_ 1041 Warn_DrvDrSwSta "DoorLock_DriverDoorSwitchStatus ##2G## -  - C_DrvDrSw,CF_Gway_DrvDrSw,Warn_DrvDrSwSta";
CM_ SG_ 1041 Warn_AsstDrSwSta "Warn_AssistDoorSwitchStatus ##2G## -  - C_AstDrSw,CF_Gway_AstDrSw,Warn_AsstDrSwSta";
CM_ SG_ 1041 Warn_BrkFldSwSta "Warn_BrakeFluidSwitchStatus ##2G## -  - C_BrakeFluidSw,CF_Gway_BrakeFluidSw";
CM_ SG_ 1041 Warn_HoodSwSta "Warn_HoodSwitchStatus ##2G## -  - C_HoodSw,CF_Gway_HoodSw";
CM_ SG_ 1041 Warn_PrkngBrkSwSta "Warn_ParkingBrakeSwitchStatus ##2G## -  - C_ParkBrakeSw";
CM_ SG_ 1041 Warn_RrLftDrSwSta "Warn_RearLeftDoorSwitchStatus ##2G## -  - C_RLDrSw,CF_Gway_RLDrSw,Warn_RrLftDrSwSta";
CM_ SG_ 1041 Warn_RrRtDrSwSta "Warn_RearRightDoorSwitchStatus ##2G## -  - C_RRDrSw,CF_Gway_RRDrSw,Warn_RrRtDrSwSta";
CM_ BO_ 1042 "[PE] Periodic and On Event";
CM_ SG_ 1042 ExtLamp_StpLmpLftOpnSta "ExtLamp_StopLampLeftOpenStatus ##2G## -  - C_StopLampLhOpenState";
CM_ SG_ 1042 ExtLamp_StpLmpRtOpnSta "ExtLamp_StopLampRightOpenStatus ##2G## -  - C_StopLampRhOpenState";
CM_ BO_ 1043 "[PE] Periodic and On Event";
CM_ SG_ 1043 ExtLamp_TrnSigLmpLftBlnkngSta "ExtLamp_TurnSignalLampLeftBlinkingStatus ##2G## -  - CF_Gway_TurnSigLh,C_TSigLhAct";
CM_ SG_ 1043 ExtLamp_TrnSigLmpRtBlnkngSta "ExtLamp_TurnSignalLampRightBlinkingStatus ##2G## -  - CF_Gway_TurnSigRh,C_TSigRhAct";
CM_ SG_ 1043 ExtLamp_ExtrnlTailLmpSta "ExtLamp_ExternalTailLampStatus ##2G## -  - C_ExtTailAct,CF_Gway_ExtTailAct";
CM_ SG_ 1043 ExtLamp_RrFgLmpSta "ExtLamp_RearFogLampStatus ##2G## -  - C_RearFogAct,CF_Gway_RearFogAct";
CM_ SG_ 1043 Lamp_LedHdLmpSta "Lamp_LedHeadLampStatus ##2G## -  - CF_Afs_LedHLStat";
CM_ BO_ 1044 "[PE] Periodic and On Event";
CM_ SG_ 1044 Trunk_TrnkTlgtSwSta "Trunk_TrunkTailgateSwitchStatus ##2G## -  - C_TrunkTgSw,CF_Gway_TrunkTgSw,Trunk_TrnkTlgtSwSta";
CM_ SG_ 1044 USM_OneTouchTrnSigFuncSta "USM_OneTouchTurnSignalFunctionStatus ##2G## -  - CF_Gway_OTTurnRValue,C_OTTurnRValue";
CM_ BO_ 1046 "[PE] Periodic and On Event";
CM_ SG_ 1046 Lamp_HdLmpLoLftOpnSta "Lamp_HeadLampLowLeftOpenStatus ##2G## -  - C_HLampLowLhOpenSts";
CM_ SG_ 1046 Lamp_HdLmpLoRtOpnSta "Lamp_HeadLampLowRightOpenStatus ##2G## -  - C_HLampLowRhOpenSts";
CM_ SG_ 1046 Lamp_HdLmpHiLftOpnSta "Lamp_HeadLampHighLeftOpenStatus ##2G## -  - C_HLampHighLhOpenSts";
CM_ SG_ 1046 Lamp_HdLmpHiRtOpnSta "Lamp_HeadLampHighRightOpenStatus ##2G## -  - C_HLampHighRhOpenSts";
CM_ SG_ 1046 Lamp_RrTrnSigLmpLftOpnSta "Lamp_RearTurnSignalLampLeftOpenStatus ##2G## -  - C_RearTSIGLhOpenSts";
CM_ SG_ 1046 Lamp_RrTrnSigLmpRtOpnSta "Lamp_RearTurnSignalLampRightOpenStatus ##2G## -  - C_RearTSIGRhOpenSts";
CM_ SG_ 1046 Lamp_FrTrnSigLmpLftOpnSta "Lamp_FrontTurnSignalLampLeftOpenStatus ##2G## -  - C_FrontTSIGLhOpenSts";
CM_ SG_ 1046 Lamp_FrTrnSigLmpRtOpnSta "Lamp_FrontTurnSignalLampRightOpenStatus ##2G## -  - C_FrontTSIGRhOpenSts";
CM_ BO_ 1047 "[PE] Periodic and On Event";
CM_ SG_ 1047 USM_AutoDrLkReq "USM_AutoDoorLockRequest ##2G## -  - CF_Gway_ADrLRValue";
CM_ SG_ 1047 USM_AutoDrUnLkReq "USM_AutoDoorUnLockRequest ##2G## -  - CF_Gway_ADrURValue";
CM_ SG_ 1047 USM_TwoTrnUnLkCurrentSta "USM_TwoTurnUnlockCurrentStatus ##2G## -  - CF_Gway_TTUnlockRValue";
CM_ SG_ 1047 Lamp_HdLmpHiSta "Lamp_HeadLampHighStatus ##2G##BCM - BCMmsg20 - C_HLpHighAct";
CM_ SG_ 1047 Lamp_HdLmpLoSta "Lamp_HeadLampLowStatus ##2G##BCM - BCMmsg20 - C_HLpLowAct";
CM_ SG_ 1047 Lamp_HdLmpBiFuncLftOpnSta "Lamp_HeadLampBiFunctionLeftOpenStatus ##2G## -  - C_HLampBifuncLhOpenSts";
CM_ SG_ 1047 Lamp_HdLmpBiFuncRtOpnSta "Lamp_HeadLampBiFunctionRightOpenStatus ##2G## -  - C_HLampBifuncRhOpenSts";
CM_ BO_ 1048 "[PE] Periodic and On Event";
CM_ SG_ 1048 DriveTypeOption "##2G## -  - C_DriveTypeOption,CF_Gway_DriveTypeOption";
CM_ SG_ 1048 Warn_LftSEA "##2G## -  - CF_ICU_SeaWarn_Lh";
CM_ SG_ 1048 Warn_RhtSEA "##2G## -  - CF_ICU_SeaWarn_Rh";
CM_ SG_ 1048 ICU_PowerAutoCutModSta "##2G## -  - CF_Gway_ICUPowerAutoCutMode";
CM_ BO_ 1040 "[PE] Periodic and On Event";
CM_ SG_ 1040 ICU_BS2SoC "This signal is battery State of Charge as calculated by battery sensor. ##2G## -  - BS2_SOC,Batt_SoC";
CM_ BO_ 1167 "[PE] Periodic and On Event";
CM_ SG_ 1167 Bat_dischrg "Battery discharge notification flag #2G# Bat_dischrg";
CM_ BO_ 234 "[P] Periodic";
CM_ SG_ 234 MDPS_LoamModSta "MDPS_LoamModeStatus ##2G##MDPS - MDPS11 - CF_Mdps_Loam_Flag";
CM_ SG_ 234 MDPS_WrngLmpSta "MDPS_WarningLampStatus ##2G##MDPS - MDPS11 - CF_Mdps_WLmp";
CM_ BO_ 485 "[P] Periodic";
CM_ SG_ 485 RCCW_Sta "RCCW_Status ##2G##BCW - BCW11 - CF_RCCW_Stat";
CM_ SG_ 485 RCCW_OnOffEquipSt "RCCW_OnOffEquipmentStatus ##2G##BCW - BCW12 - CF_RCCW_USM";
CM_ SG_ 485 RCCW_LftIndSta "RCCW_LeftIndicatorStatus ##2G##BCW - BCW11 - CF_RCCW_IndLeft";
CM_ SG_ 485 RCCW_RtIndSta "RCCW_RightIndicatorStatus ##2G##BCW - BCW11 - CF_RCCW_IndRight";
CM_ SG_ 485 RCCW_LftSndWrngSta "RCCW_LeftSoundWarningStatus ##2G##BCW - BCW11 - CF_RL_SndWan";
CM_ SG_ 485 RCCW_RtSndWrngSta "RCCW_RightSoundWarningStatus ##2G##BCW - BCW11 - CF_RR_SndWan";
CM_ SG_ 485 RCCW_LftWrngIndBriLvlVal "RCCW_LeftWarningIndicatorBrightnessLevelValue ##2G##BCW - BCW11 - CF_RCCW_IndBriLeft";
CM_ SG_ 485 RCCW_RtWrngIndBriLvlVal "RCCW_RightWarningIndicatorBrightnessLevelValue ##2G##BCW - BCW11 - CF_RCCW_IndBriRight";
CM_ SG_ 485 RCCA_LftWrngSta "RCCA_LeftWarningStatus ##2G##BCW - BCA11 - CF_RCCA_WarnLh";
CM_ SG_ 485 RCCA_RtWrngSta "RCCA_RightWarningStatus ##2G##BCW - BCA11 - CF_RCCA_WarnRh";
CM_ SG_ 485 RCCA_FuncStat "RCCA_FunctionStatus ##2G##BCW - BCA11 - CF_RCCA_FuncState";
CM_ SG_ 485 RCCA_Sta "RCCA_Status";
CM_ SG_ 485 RCCA_OnOffEquipSt "RCCA_OnOffEquipmentStatus ##2G##BCW - BCW12 - CF_RCCA_USM";
CM_ SG_ 485 SEA_Sta "SEA_Status";
CM_ SG_ 485 SEA_OnOffEquipSta "SEA_OnOffEquipmentStatus ##2G##BCW - BCW12 - CF_SEA_USM";
CM_ SG_ 485 SEA_LftWrngSta "SEA_LeftWarningStatus ##2G##BCW - BCA11 - CF_SEA_Warn_Lh";
CM_ SG_ 485 SEA_RtWrngSta "SEA_RightWarningStatus ##2G##BCW - BCA11 - CF_SEA_Warn_Rh";
CM_ BO_ 346 "[P] Periodic";
CM_ SG_ 346 SCU_FF_PosActSta "SCU_FF_PositionActualState";
CM_ BO_ 1061 "[PE] Periodic and On Event";
CM_ SG_ 1061 Warn_DeActvWrngSta "Warn_DeActivationWarningStatus ##2G##SMK - SMKmsg17 - C_DeactivationWarn";
CM_ SG_ 1061 Warn_DisWrngSta "Warn_DisplayWarningStatus ##2G##SMK - SMKmsg17 - C_SMKDispWarn";
CM_ SG_ 1061 Warn_IdOutWrngSta "Warn_IdOutWarningStatus ##2G##SMK - SMKmsg17 - C_IDoutWarn";
CM_ SG_ 1061 Warn_KeyBattLoWrngSta "Warn_KeyBatteryLowWarningStatus ##2G##SMK - SMKmsg17 - C_KeyBATDischargeWarn";
CM_ SG_ 1061 Warn_ImmoLmpOnReq "Warn_ImmobilizerLampOnRequest ##2G##SMK - SMKmsg17 - C_ImmoLp";
CM_ BO_ 64 "[P] Periodic";
CM_ SG_ 64 TCU_EngRpmDisSta "TCU_EngineRpmDisplayStatus";
CM_ SG_ 64 TCU_EngRpmDis "TCU_EngineRpmDisplay";
CM_ SG_ 64 TCU_SprtyIndxSta "TCU_SportyIndexStatus";
CM_ SG_ 64 TCU_DrvngModDis "TCU_DrivingModeDisplay";
CM_ SG_ 64 TCU_SmrtShftSta "TCU_SmartShiftStatus";
CM_ SG_ 64 TCU_ShftPtrnSta "TCU_ShiftPatternStatus";
CM_ SG_ 64 TCU_GearSlctDis "TCU_GearSelectDisplay";
CM_ SG_ 64 TCU_Typ "TCU_Type";
CM_ SG_ 64 TCU_TqRdctnVal "TCU_TorqueReductionValue";
CM_ SG_ 64 TCU_GearStepTyp "TCU_GearStepType";
CM_ SG_ 64 TCU_GearShftSta "TCU_GearShiftStatus";
CM_ SG_ 64 TCU_CurrGearSta "TCU_CurrentGearStatus";
CM_ SG_ 64 TCU_TrgtGearSta "TCU_TargetGearStatus";
CM_ SG_ 64 TCU_CluTrgtGearSta "TCU_ClusterTargetGear";
CM_ SG_ 64 TCU_CluTrgtGearConfg "Signal source Configuration of  Target gear for CLU";
CM_ BO_ 106 "[P] Periodic";
CM_ SG_ 106 TCU_ActvEcoRdySta "TCU_ActiveEcoReadyStatus";
CM_ BO_ 720 "[P] Periodic";
CM_ SG_ 720 TCU_WrngMsgSta "TCU_WarningMessageStatus";
CM_ SG_ 720 TCU_VehStpTimeDis "TCU_VehicleStopTimeDisplay";
CM_ SG_ 720 TCU_CurCltTemp "TCU_CurrentClutchTemperature";
CM_ SG_ 720 TCU_AvgCltTemp "TCU_AverageClutchTemperature";
CM_ SG_ 720 DCT_HillHldWrng "DCT_HillHoldWarning";
CM_ SG_ 720 DCT_CltchBrstWrng "DCT_ClutchBurstWarning";
CM_ SG_ 720 DCT_WrngSndSta "DCT_WarningSoundStatus";
BA_DEF_ BO_ "TpMessage" ENUM "No","Yes" ;
BA_DEF_ BO_ "UsrMsgIDSforwardDeviation" INT 0 100 ;
BA_DEF_ BO_ "UsrMsgIDSbackwardDeviation" INT 50 1000 ;
BA_DEF_ BO_ "GenMsgCycleTime" INT 0 2000 ;
BA_DEF_ BO_ "GenMsgStartDelayTime" INT 0 2000 ;
BA_DEF_ BO_ "GenMsgSendType" ENUM "Cyclic","NoMsgSendType" ;
BA_DEF_ BO_ "GenMsgCycleTimeFast" INT 0 500 ;
BA_DEF_ BO_ "GenMsgDelayTime" INT 0 20 ;
BA_DEF_ BO_ "GenMsgILSupport" ENUM "No","Yes" ;
BA_DEF_ BO_ "GenMsgNrOfRepetition" INT 0 3 ;
BA_DEF_ BO_ "VFrameFormat" ENUM "StandardCAN","ExtendedCAN","reserved","reserved","reserved","reserved","reserved","reserved","reserved","reserved","reserved","reserved","reserved","reserved","StandardCAN_FD","ExtendedCAN_FD" ;
BA_DEF_ SG_ "UserSigValidity" ENUM "B+","ACC","IG","IG1","IG2","IG3","IG1 or IG2","IG1 or IG3","Undef" ;
BA_DEF_ SG_ "GenSigTimeoutTime" INT 0 7000 ;
BA_DEF_ SG_ "UsrSigTimeoutValue" STRING ;
BA_DEF_ SG_ "UsrSigPurpose" ENUM "Undef","FN","DIAG","DEV","NM" ;
BA_DEF_ SG_ "GenSigStartValue" INT 0 0 ;
BA_DEF_ SG_ "NetworkRequest" ENUM "Yes","No" ;
BA_DEF_ SG_ "NetworkRequestHoldingTime" INT 0 65535 ;
BA_DEF_ SG_ "Description" STRING ;
BA_DEF_ SG_ "Version" STRING ;
BA_DEF_ SG_ "GenSigEnvVarType" ENUM "Int","Float","Undef" ;
BA_DEF_ SG_ "GenSigSendType" ENUM "Cyclic","OnWrite","OnWriteWithRepetition","OnChange","OnChangeWithRepetition","IfActive","IfActiveWithRepetition","NoSigSendType","OnChangeAndIfActive","OnChangeAndIfActiveWithRepetition" ;
BA_DEF_ SG_ "GwSigLatencyTime" INT 0 65536 ;
BA_DEF_ SG_ "GwSigMissingSourceType" ENUM "Undef","OldValue","DefaultValue","InitialValue" ;
BA_DEF_ SG_ "NWM-WakeupAllowed" ENUM "<n.a.>" ;
BA_DEF_ SG_ "RoutingFactor" INT 1 1215752192 ;
BA_DEF_DEF_ "TpMessage" "No" ;
BA_DEF_DEF_ "UsrMsgIDSforwardDeviation" 10 ;
BA_DEF_DEF_ "UsrMsgIDSbackwardDeviation" 100 ;
BA_DEF_DEF_ "GenMsgCycleTime" 200 ;
BA_DEF_DEF_ "GenMsgStartDelayTime" 0 ;
BA_DEF_DEF_ "GenMsgSendType" "NoMsgSendType" ;
BA_DEF_DEF_ "GenMsgCycleTimeFast" 40 ;
BA_DEF_DEF_ "GenMsgDelayTime" 20 ;
BA_DEF_DEF_ "GenMsgILSupport" "Yes" ;
BA_DEF_DEF_ "GenMsgNrOfRepetition" 3 ;
BA_DEF_DEF_ "VFrameFormat" "StandardCAN" ;
BA_DEF_DEF_ "UserSigValidity" "IG" ;
BA_DEF_DEF_ "GenSigTimeoutTime" 500 ;
BA_DEF_DEF_ "UsrSigTimeoutValue" "Undef" ;
BA_DEF_DEF_ "UsrSigPurpose" "FN" ;
BA_DEF_DEF_ "GenSigStartValue" 0 ;
BA_DEF_DEF_ "NetworkRequest" "No" ;
BA_DEF_DEF_ "NetworkRequestHoldingTime" 0 ;
BA_DEF_DEF_ "Description" "" ;
BA_DEF_DEF_ "Version" "" ;
BA_DEF_DEF_ "GenSigEnvVarType" "Undef" ;
BA_DEF_DEF_ "GenSigSendType" "NoSigSendType" ;
BA_DEF_DEF_ "GwSigLatencyTime" 40 ;
BA_DEF_DEF_ "GwSigMissingSourceType" "Undef" ;
BA_DEF_DEF_ "NWM-WakeupAllowed" "<n.a.>" ;
BA_DEF_DEF_ "RoutingFactor" 1 ;
BA_ "GenMsgSendType" BO_ 111 0;
BA_ "GenMsgCycleTime" BO_ 111 10;
BA_ "GenMsgCycleTimeFast" BO_ 111 0;
BA_ "GenMsgNrOfRepetition" BO_ 111 0;
BA_ "GenMsgDelayTime" BO_ 111 0;
BA_ "VFrameFormat" BO_ 111 14;
BA_ "Description" SG_ 111 ABS__WrngLmpSta "The signal indicates the status of the “ABS Warning lamp”";
BA_ "UserSigValidity" SG_ 111 ABS__WrngLmpSta 3;
BA_ "RoutingFactor" SG_ 111 ABS__WrngLmpSta 5;
BA_ "Version" SG_ 111 ABS__WrngLmpSta "18.12.05";
BA_ "Description" SG_ 111 EBD__WrngLmpSta "The signal indicates the status of the “EBD Warning lamp”";
BA_ "UserSigValidity" SG_ 111 EBD__WrngLmpSta 3;
BA_ "RoutingFactor" SG_ 111 EBD__WrngLmpSta 5;
BA_ "Version" SG_ 111 EBD__WrngLmpSta "18.12.05";
BA_ "Description" SG_ 111 ESC__BrkLtActSta "Flag from TCS which activates the illumination of the brake lights during automatic braking";
BA_ "UserSigValidity" SG_ 111 ESC__BrkLtActSta 0;
BA_ "RoutingFactor" SG_ 111 ESC__BrkLtActSta 5;
BA_ "Version" SG_ 111 ESC__BrkLtActSta "18.12.05";
BA_ "GenMsgSendType" BO_ 352 0;
BA_ "GenMsgCycleTime" BO_ 352 20;
BA_ "GenMsgCycleTimeFast" BO_ 352 0;
BA_ "GenMsgNrOfRepetition" BO_ 352 0;
BA_ "GenMsgDelayTime" BO_ 352 0;
BA_ "VFrameFormat" BO_ 352 14;
BA_ "Description" SG_ 352 FCA_OnOffEquipSta "This signal describes the FCA Function.
- 시스템 장착 여부 및 시스템 on/off 정보";
BA_ "UserSigValidity" SG_ 352 FCA_OnOffEquipSta 3;
BA_ "RoutingFactor" SG_ 352 FCA_OnOffEquipSta 5;
BA_ "Version" SG_ 352 FCA_OnOffEquipSta "17.12.00";
BA_ "Description" SG_ 352 FCA_SysFlrSta "This signal describes the failure information of FCA Function.

- 시스템 정상 또는 카메라/레이더/시스템 고장상태 정보";
BA_ "UserSigValidity" SG_ 352 FCA_SysFlrSta 3;
BA_ "RoutingFactor" SG_ 352 FCA_SysFlrSta 5;
BA_ "Version" SG_ 352 FCA_SysFlrSta "17.12.00";
BA_ "Description" SG_ 352 FCA_WrngLvlSta "Request CLU to activate the corresponding warning device(s) according to the FCA warning level.
- FCA 1차/2차/3차 작동 상태 표시용 정보신호";
BA_ "UserSigValidity" SG_ 352 FCA_WrngLvlSta 3;
BA_ "RoutingFactor" SG_ 352 FCA_WrngLvlSta 5;
BA_ "Version" SG_ 352 FCA_WrngLvlSta "17.12.00";
BA_ "Description" SG_ 352 FCA_VehStpReq "A control request flag for vehicle stop. FCA expects vehicle to be controlled to a complete stop and hold its state by ESC.

- FCA 제동상황 종료후 정차 상태 유지를 위한 신호";
BA_ "UserSigValidity" SG_ 352 FCA_VehStpReq 3;
BA_ "RoutingFactor" SG_ 352 FCA_VehStpReq 5;
BA_ "Version" SG_ 352 FCA_VehStpReq "17.12.00";
BA_ "Description" SG_ 352 FCA_SnstvtyModRetVal "This signal is FCA sensitive set mode switch(USM) info return value to cluster.
- FCA 민감도 설정 관련 USM 설정 스위치 정보의 리턴 값";
BA_ "UserSigValidity" SG_ 352 FCA_SnstvtyModRetVal 3;
BA_ "RoutingFactor" SG_ 352 FCA_SnstvtyModRetVal 5;
BA_ "Version" SG_ 352 FCA_SnstvtyModRetVal "17.12.00";
BA_ "Description" SG_ 352 FCA_WrngTrgtDis "Request CLU to activate the corresponding warning device(s) according to the type of FCA warning target.
- FCA 경고 대상 종류별 표시 정보신호";
BA_ "UserSigValidity" SG_ 352 FCA_WrngTrgtDis 3;
BA_ "RoutingFactor" SG_ 352 FCA_WrngTrgtDis 5;
BA_ "Version" SG_ 352 FCA_WrngTrgtDis "17.12.03";
BA_ "GenMsgSendType" BO_ 298 0;
BA_ "GenMsgCycleTime" BO_ 298 10;
BA_ "GenMsgCycleTimeFast" BO_ 298 0;
BA_ "GenMsgNrOfRepetition" BO_ 298 0;
BA_ "GenMsgDelayTime" BO_ 298 0;
BA_ "VFrameFormat" BO_ 298 14;
BA_ "UserSigValidity" SG_ 298 LKA_OptUsmSta 3;
BA_ "RoutingFactor" SG_ 298 LKA_OptUsmSta 5;
BA_ "Version" SG_ 298 LKA_OptUsmSta "17.12.02";
BA_ "UserSigValidity" SG_ 298 LKA_RcgSta 3;
BA_ "RoutingFactor" SG_ 298 LKA_RcgSta 5;
BA_ "Version" SG_ 298 LKA_RcgSta "18.10.12";
BA_ "UserSigValidity" SG_ 298 LKA_LHLnWrnSta 3;
BA_ "RoutingFactor" SG_ 298 LKA_LHLnWrnSta 5;
BA_ "Version" SG_ 298 LKA_LHLnWrnSta "18.11.02";
BA_ "UserSigValidity" SG_ 298 LKA_RHLnWrnSta 3;
BA_ "RoutingFactor" SG_ 298 LKA_RHLnWrnSta 5;
BA_ "Version" SG_ 298 LKA_RHLnWrnSta "18.11.02";
BA_ "UserSigValidity" SG_ 298 LKA_HndsoffSnd 3;
BA_ "RoutingFactor" SG_ 298 LKA_HndsoffSnd 5;
BA_ "Version" SG_ 298 LKA_HndsoffSnd "17.12.02";
BA_ "UserSigValidity" SG_ 298 LKA_StrSnd 3;
BA_ "RoutingFactor" SG_ 298 LKA_StrSnd 5;
BA_ "Version" SG_ 298 LKA_StrSnd "17.12.02";
BA_ "UserSigValidity" SG_ 298 LKA_SysIndReq 3;
BA_ "RoutingFactor" SG_ 298 LKA_SysIndReq 5;
BA_ "Version" SG_ 298 LKA_SysIndReq "17.12.02";
BA_ "Description" SG_ 298 ADAS_ActToiSta "This is a flag that is set to 1 when requesting the steering to activate the torque overlay interface (TOI).  This must be done before an attempt is made to request non-zero steering torque overlay.";
BA_ "UserSigValidity" SG_ 298 ADAS_ActToiSta 3;
BA_ "RoutingFactor" SG_ 298 ADAS_ActToiSta 5;
BA_ "Version" SG_ 298 ADAS_ActToiSta "18.12.07";
BA_ "Description" SG_ 298 LKA_SysWrn "A signal that provides additional information on the operation of the LKA system for the HMI to display to the driver. This includes additional fault information, reasons for unavailability of the system and additional warnings like the hands-off warning. Some of the information may be displayed for short periods, whilst others like the hands-off warning may be displayed for longer periods.";
BA_ "UserSigValidity" SG_ 298 LKA_SysWrn 3;
BA_ "RoutingFactor" SG_ 298 LKA_SysWrn 5;
BA_ "Version" SG_ 298 LKA_SysWrn "18.10.09";
BA_ "Description" SG_ 298 LKA_UsmMod "This signal indicates LKA USM Mode";
BA_ "UserSigValidity" SG_ 298 LKA_UsmMod 3;
BA_ "RoutingFactor" SG_ 298 LKA_UsmMod 5;
BA_ "Version" SG_ 298 LKA_UsmMod "18.01.08";
BA_ "GenMsgSendType" BO_ 480 0;
BA_ "GenMsgCycleTime" BO_ 480 50;
BA_ "GenMsgCycleTimeFast" BO_ 480 0;
BA_ "GenMsgNrOfRepetition" BO_ 480 0;
BA_ "VFrameFormat" BO_ 480 14;
BA_ "Description" SG_ 480 HDA_OptUsmSta "This is HDA system status needed for the cluster USM display.";
BA_ "UserSigValidity" SG_ 480 HDA_OptUsmSta 3;
BA_ "RoutingFactor" SG_ 480 HDA_OptUsmSta 3;
BA_ "Version" SG_ 480 HDA_OptUsmSta "17.12.02";
BA_ "Description" SG_ 480 HDA_CntrlModSta "This is HDA Control Mode needed for longitudinal/lateral control and cluster display.";
BA_ "UserSigValidity" SG_ 480 HDA_CntrlModSta 3;
BA_ "RoutingFactor" SG_ 480 HDA_CntrlModSta 3;
BA_ "Version" SG_ 480 HDA_CntrlModSta "17.12.02";
BA_ "Description" SG_ 480 HDA_InfoPUDis "This is HDA information display needed for the cluster pop-up display.";
BA_ "UserSigValidity" SG_ 480 HDA_InfoPUDis 3;
BA_ "RoutingFactor" SG_ 480 HDA_InfoPUDis 3;
BA_ "Version" SG_ 480 HDA_InfoPUDis "18.10.09";
BA_ "Description" SG_ 480 HDA_LFA_SymSta "This signal shows the state of steering assist.";
BA_ "UserSigValidity" SG_ 480 HDA_LFA_SymSta 3;
BA_ "RoutingFactor" SG_ 480 HDA_LFA_SymSta 3;
BA_ "Version" SG_ 480 HDA_LFA_SymSta "17.12.02";
BA_ "Description" SG_ 480 HDA_LFA_WrnSnd "HDA/LFA Additional Warning Sound";
BA_ "UserSigValidity" SG_ 480 HDA_LFA_WrnSnd 3;
BA_ "RoutingFactor" SG_ 480 HDA_LFA_WrnSnd 3;
BA_ "Version" SG_ 480 HDA_LFA_WrnSnd "18.02.03";
BA_ "Description" SG_ 480 HDA_InfoPUDis1 "This is HDA/LFA information display needed for the cluster pop-up display.";
BA_ "UserSigValidity" SG_ 480 HDA_InfoPUDis1 3;
BA_ "RoutingFactor" SG_ 480 HDA_InfoPUDis1 3;
BA_ "Version" SG_ 480 HDA_InfoPUDis1 "18.10.00";
BA_ "GenMsgSendType" BO_ 421 0;
BA_ "GenMsgCycleTime" BO_ 421 20;
BA_ "GenMsgCycleTimeFast" BO_ 421 0;
BA_ "GenMsgNrOfRepetition" BO_ 421 0;
BA_ "GenMsgDelayTime" BO_ 421 0;
BA_ "VFrameFormat" BO_ 421 14;
BA_ "Description" SG_ 421 AWD_FrTqDistRto "Signal for display on cluster.(Torque Distribution ratio to Front Wheel)";
BA_ "UserSigValidity" SG_ 421 AWD_FrTqDistRto 3;
BA_ "RoutingFactor" SG_ 421 AWD_FrTqDistRto 5;
BA_ "Version" SG_ 421 AWD_FrTqDistRto "18.08.02";
BA_ "Description" SG_ 421 AWD_RrTqDistRto "Signal for display on cluster (Torque Distribution ratio to Rear Wheel)";
BA_ "UserSigValidity" SG_ 421 AWD_RrTqDistRto 3;
BA_ "RoutingFactor" SG_ 421 AWD_RrTqDistRto 5;
BA_ "Version" SG_ 421 AWD_RrTqDistRto "18.08.02";
BA_ "Description" SG_ 421 AWD_ErrCodeVal "This is for the “AWD ECU, MAGNA & WIA JV社” system applied vehicles only.";
BA_ "UserSigValidity" SG_ 421 AWD_ErrCodeVal 3;
BA_ "RoutingFactor" SG_ 421 AWD_ErrCodeVal 5;
BA_ "Version" SG_ 421 AWD_ErrCodeVal "17.11.00";
BA_ "UserSigValidity" SG_ 421 AWD_OpModLkSta 3;
BA_ "RoutingFactor" SG_ 421 AWD_OpModLkSta 5;
BA_ "Version" SG_ 421 AWD_OpModLkSta "17.11.00";
BA_ "GenMsgSendType" BO_ 993 0;
BA_ "VFrameFormat" BO_ 993 14;
BA_ "Description" SG_ 993 SBR_StBltWrngBzrSta "-Seat belt Warning (Reminder) buzzer";
BA_ "GenSigSendType" SG_ 993 SBR_StBltWrngBzrSta 4;
BA_ "UserSigValidity" SG_ 993 SBR_StBltWrngBzrSta 0;
BA_ "GenSigTimeoutTime" SG_ 993 SBR_StBltWrngBzrSta 1500;
BA_ "NetworkRequest" SG_ 993 SBR_StBltWrngBzrSta 0;
BA_ "NetworkRequestHoldingTime" SG_ 993 SBR_StBltWrngBzrSta 5000;
BA_ "Version" SG_ 993 SBR_StBltWrngBzrSta "17.12.00";
BA_ "GenSigSendType" SG_ 993 SBR_DrvStBltIndSta 4;
BA_ "UserSigValidity" SG_ 993 SBR_DrvStBltIndSta 0;
BA_ "GenSigTimeoutTime" SG_ 993 SBR_DrvStBltIndSta 1500;
BA_ "NetworkRequest" SG_ 993 SBR_DrvStBltIndSta 0;
BA_ "NetworkRequestHoldingTime" SG_ 993 SBR_DrvStBltIndSta 5000;
BA_ "Version" SG_ 993 SBR_DrvStBltIndSta "17.12.00";
BA_ "GenMsgSendType" BO_ 994 0;
BA_ "VFrameFormat" BO_ 994 14;
BA_ "Description" SG_ 994 Warn_BzrWrngSta "-(Old)C_WngBuzzer";
BA_ "GenSigSendType" SG_ 994 Warn_BzrWrngSta 4;
BA_ "UserSigValidity" SG_ 994 Warn_BzrWrngSta 0;
BA_ "GenSigTimeoutTime" SG_ 994 Warn_BzrWrngSta 1500;
BA_ "NetworkRequest" SG_ 994 Warn_BzrWrngSta 0;
BA_ "NetworkRequestHoldingTime" SG_ 994 Warn_BzrWrngSta 5000;
BA_ "Version" SG_ 994 Warn_BzrWrngSta "17.12.00";
BA_ "Description" SG_ 994 Warn_BCMWrngSta "Warning command og BCM";
BA_ "GenSigSendType" SG_ 994 Warn_BCMWrngSta 4;
BA_ "UserSigValidity" SG_ 994 Warn_BCMWrngSta 0;
BA_ "GenSigTimeoutTime" SG_ 994 Warn_BCMWrngSta 1500;
BA_ "NetworkRequest" SG_ 994 Warn_BCMWrngSta 0;
BA_ "NetworkRequestHoldingTime" SG_ 994 Warn_BCMWrngSta 5000;
BA_ "Version" SG_ 994 Warn_BCMWrngSta "17.12.00";
BA_ "Description" SG_ 994 Warn_RrStRmndSysSta "Rear Seat Reminder Alarm System Enable(On)/Disable(Off) state";
BA_ "GenSigSendType" SG_ 994 Warn_RrStRmndSysSta 4;
BA_ "UserSigValidity" SG_ 994 Warn_RrStRmndSysSta 0;
BA_ "GenSigTimeoutTime" SG_ 994 Warn_RrStRmndSysSta 1500;
BA_ "NetworkRequest" SG_ 994 Warn_RrStRmndSysSta 0;
BA_ "NetworkRequestHoldingTime" SG_ 994 Warn_RrStRmndSysSta 5000;
BA_ "Version" SG_ 994 Warn_RrStRmndSysSta "17.12.00";
BA_ "Description" SG_ 994 Warn_RrStRmndAlrmInfo "Rear Seat Reminder Warning request signal";
BA_ "GenSigSendType" SG_ 994 Warn_RrStRmndAlrmInfo 4;
BA_ "UserSigValidity" SG_ 994 Warn_RrStRmndAlrmInfo 0;
BA_ "GenSigTimeoutTime" SG_ 994 Warn_RrStRmndAlrmInfo 1500;
BA_ "NetworkRequest" SG_ 994 Warn_RrStRmndAlrmInfo 0;
BA_ "NetworkRequestHoldingTime" SG_ 994 Warn_RrStRmndAlrmInfo 5000;
BA_ "Version" SG_ 994 Warn_RrStRmndAlrmInfo "18.11.02";
BA_ "Description" SG_ 994 Warn_RoaErr "ROA SENSOR Error(Malfunction)  signal";
BA_ "GenSigSendType" SG_ 994 Warn_RoaErr 4;
BA_ "UserSigValidity" SG_ 994 Warn_RoaErr 0;
BA_ "GenSigTimeoutTime" SG_ 994 Warn_RoaErr 1500;
BA_ "NetworkRequest" SG_ 994 Warn_RoaErr 0;
BA_ "NetworkRequestHoldingTime" SG_ 994 Warn_RoaErr 5000;
BA_ "Version" SG_ 994 Warn_RoaErr "18.07.01";
BA_ "GenMsgSendType" BO_ 997 0;
BA_ "VFrameFormat" BO_ 997 14;
BA_ "Description" SG_ 997 PDW_OptTyp "this signal means PDW Option (Non, PDW-R, PDW-FR)";
BA_ "GenSigSendType" SG_ 997 PDW_OptTyp 4;
BA_ "UserSigValidity" SG_ 997 PDW_OptTyp 3;
BA_ "GenSigTimeoutTime" SG_ 997 PDW_OptTyp 1500;
BA_ "NetworkRequest" SG_ 997 PDW_OptTyp 0;
BA_ "NetworkRequestHoldingTime" SG_ 997 PDW_OptTyp 5000;
BA_ "Version" SG_ 997 PDW_OptTyp "17.12.00";
BA_ "Description" SG_ 997 PDW_SysChkSndSta "-PDW System state check sound";
BA_ "GenSigSendType" SG_ 997 PDW_SysChkSndSta 4;
BA_ "UserSigValidity" SG_ 997 PDW_SysChkSndSta 0;
BA_ "GenSigTimeoutTime" SG_ 997 PDW_SysChkSndSta 1500;
BA_ "NetworkRequest" SG_ 997 PDW_SysChkSndSta 0;
BA_ "NetworkRequestHoldingTime" SG_ 997 PDW_SysChkSndSta 5000;
BA_ "Version" SG_ 997 PDW_SysChkSndSta "17.12.00";
BA_ "Description" SG_ 997 PDW_SysOnSta "-PDW System operating status";
BA_ "GenSigSendType" SG_ 997 PDW_SysOnSta 4;
BA_ "UserSigValidity" SG_ 997 PDW_SysOnSta 0;
BA_ "GenSigTimeoutTime" SG_ 997 PDW_SysOnSta 1500;
BA_ "NetworkRequest" SG_ 997 PDW_SysOnSta 0;
BA_ "NetworkRequestHoldingTime" SG_ 997 PDW_SysOnSta 5000;
BA_ "Version" SG_ 997 PDW_SysOnSta "17.12.00";
BA_ "Description" SG_ 997 PDW_FrCtrWrngLvlDis "-Front center display";
BA_ "GenSigSendType" SG_ 997 PDW_FrCtrWrngLvlDis 4;
BA_ "UserSigValidity" SG_ 997 PDW_FrCtrWrngLvlDis 0;
BA_ "GenSigTimeoutTime" SG_ 997 PDW_FrCtrWrngLvlDis 1500;
BA_ "NetworkRequest" SG_ 997 PDW_FrCtrWrngLvlDis 0;
BA_ "NetworkRequestHoldingTime" SG_ 997 PDW_FrCtrWrngLvlDis 5000;
BA_ "Version" SG_ 997 PDW_FrCtrWrngLvlDis "17.12.00";
BA_ "Description" SG_ 997 PDW_FrLftWrngLvlDis "-Front Left display";
BA_ "GenSigSendType" SG_ 997 PDW_FrLftWrngLvlDis 4;
BA_ "UserSigValidity" SG_ 997 PDW_FrLftWrngLvlDis 0;
BA_ "GenSigTimeoutTime" SG_ 997 PDW_FrLftWrngLvlDis 1500;
BA_ "NetworkRequest" SG_ 997 PDW_FrLftWrngLvlDis 0;
BA_ "NetworkRequestHoldingTime" SG_ 997 PDW_FrLftWrngLvlDis 5000;
BA_ "Version" SG_ 997 PDW_FrLftWrngLvlDis "17.12.00";
BA_ "Description" SG_ 997 PDW_FrRtWrngLvlDis "-Front Right display";
BA_ "GenSigSendType" SG_ 997 PDW_FrRtWrngLvlDis 4;
BA_ "UserSigValidity" SG_ 997 PDW_FrRtWrngLvlDis 0;
BA_ "GenSigTimeoutTime" SG_ 997 PDW_FrRtWrngLvlDis 1500;
BA_ "NetworkRequest" SG_ 997 PDW_FrRtWrngLvlDis 0;
BA_ "NetworkRequestHoldingTime" SG_ 997 PDW_FrRtWrngLvlDis 5000;
BA_ "Version" SG_ 997 PDW_FrRtWrngLvlDis "17.12.00";
BA_ "Description" SG_ 997 PDW_FrSnsrWrngLvlSta "-Front Sensor warning";
BA_ "GenSigSendType" SG_ 997 PDW_FrSnsrWrngLvlSta 4;
BA_ "UserSigValidity" SG_ 997 PDW_FrSnsrWrngLvlSta 0;
BA_ "GenSigTimeoutTime" SG_ 997 PDW_FrSnsrWrngLvlSta 1500;
BA_ "NetworkRequest" SG_ 997 PDW_FrSnsrWrngLvlSta 0;
BA_ "NetworkRequestHoldingTime" SG_ 997 PDW_FrSnsrWrngLvlSta 5000;
BA_ "Version" SG_ 997 PDW_FrSnsrWrngLvlSta "17.12.00";
BA_ "GenMsgSendType" BO_ 998 0;
BA_ "VFrameFormat" BO_ 998 14;
BA_ "Description" SG_ 998 PDW_RrCtrWrngLvlDis "-Rear center display";
BA_ "GenSigSendType" SG_ 998 PDW_RrCtrWrngLvlDis 4;
BA_ "UserSigValidity" SG_ 998 PDW_RrCtrWrngLvlDis 0;
BA_ "GenSigTimeoutTime" SG_ 998 PDW_RrCtrWrngLvlDis 1500;
BA_ "NetworkRequest" SG_ 998 PDW_RrCtrWrngLvlDis 0;
BA_ "NetworkRequestHoldingTime" SG_ 998 PDW_RrCtrWrngLvlDis 5000;
BA_ "Version" SG_ 998 PDW_RrCtrWrngLvlDis "17.12.00";
BA_ "Description" SG_ 998 PDW_RrLftWrngLvlDis "-Rear Left display";
BA_ "GenSigSendType" SG_ 998 PDW_RrLftWrngLvlDis 4;
BA_ "UserSigValidity" SG_ 998 PDW_RrLftWrngLvlDis 0;
BA_ "GenSigTimeoutTime" SG_ 998 PDW_RrLftWrngLvlDis 1500;
BA_ "NetworkRequest" SG_ 998 PDW_RrLftWrngLvlDis 0;
BA_ "NetworkRequestHoldingTime" SG_ 998 PDW_RrLftWrngLvlDis 5000;
BA_ "Version" SG_ 998 PDW_RrLftWrngLvlDis "17.12.00";
BA_ "Description" SG_ 998 PDW_RrRtWrngLvlDis "-Rear Right display";
BA_ "GenSigSendType" SG_ 998 PDW_RrRtWrngLvlDis 4;
BA_ "UserSigValidity" SG_ 998 PDW_RrRtWrngLvlDis 0;
BA_ "GenSigTimeoutTime" SG_ 998 PDW_RrRtWrngLvlDis 1500;
BA_ "NetworkRequest" SG_ 998 PDW_RrRtWrngLvlDis 0;
BA_ "NetworkRequestHoldingTime" SG_ 998 PDW_RrRtWrngLvlDis 5000;
BA_ "Version" SG_ 998 PDW_RrRtWrngLvlDis "17.12.00";
BA_ "Description" SG_ 998 PDW_RrSnsrWrngLvlSta "-Rear Sensor warning";
BA_ "GenSigSendType" SG_ 998 PDW_RrSnsrWrngLvlSta 4;
BA_ "UserSigValidity" SG_ 998 PDW_RrSnsrWrngLvlSta 0;
BA_ "GenSigTimeoutTime" SG_ 998 PDW_RrSnsrWrngLvlSta 1500;
BA_ "NetworkRequest" SG_ 998 PDW_RrSnsrWrngLvlSta 0;
BA_ "NetworkRequestHoldingTime" SG_ 998 PDW_RrSnsrWrngLvlSta 5000;
BA_ "Version" SG_ 998 PDW_RrSnsrWrngLvlSta "17.12.00";
BA_ "GenMsgSendType" BO_ 1050 0;
BA_ "VFrameFormat" BO_ 1050 14;
BA_ "Description" SG_ 1050 Lamp_ExtrnlTailLmpOnReq "-(Old)C_EXTTailOn";
BA_ "GenSigSendType" SG_ 1050 Lamp_ExtrnlTailLmpOnReq 4;
BA_ "UserSigValidity" SG_ 1050 Lamp_ExtrnlTailLmpOnReq 0;
BA_ "GenSigTimeoutTime" SG_ 1050 Lamp_ExtrnlTailLmpOnReq 1500;
BA_ "NetworkRequest" SG_ 1050 Lamp_ExtrnlTailLmpOnReq 0;
BA_ "NetworkRequestHoldingTime" SG_ 1050 Lamp_ExtrnlTailLmpOnReq 5000;
BA_ "Version" SG_ 1050 Lamp_ExtrnlTailLmpOnReq "17.12.00";
BA_ "Description" SG_ 1050 Lamp_AvTailLmpSta "-Send with at the same time with C_IntTailOn
-Initiail Value: 1";
BA_ "GenSigSendType" SG_ 1050 Lamp_AvTailLmpSta 4;
BA_ "GenSigStartValue" SG_ 1050 Lamp_AvTailLmpSta 1;
BA_ "UserSigValidity" SG_ 1050 Lamp_AvTailLmpSta 0;
BA_ "GenSigTimeoutTime" SG_ 1050 Lamp_AvTailLmpSta 1500;
BA_ "NetworkRequest" SG_ 1050 Lamp_AvTailLmpSta 0;
BA_ "NetworkRequestHoldingTime" SG_ 1050 Lamp_AvTailLmpSta 5000;
BA_ "Version" SG_ 1050 Lamp_AvTailLmpSta "17.12.00";
BA_ "GenMsgSendType" BO_ 1052 0;
BA_ "VFrameFormat" BO_ 1052 14;
BA_ "Description" SG_ 1052 Lamp_AutoLtSnsrNightSta "This signal indicates autolight sensor output";
BA_ "GenSigSendType" SG_ 1052 Lamp_AutoLtSnsrNightSta 4;
BA_ "UserSigValidity" SG_ 1052 Lamp_AutoLtSnsrNightSta 0;
BA_ "GenSigTimeoutTime" SG_ 1052 Lamp_AutoLtSnsrNightSta 1500;
BA_ "NetworkRequest" SG_ 1052 Lamp_AutoLtSnsrNightSta 0;
BA_ "NetworkRequestHoldingTime" SG_ 1052 Lamp_AutoLtSnsrNightSta 5000;
BA_ "Version" SG_ 1052 Lamp_AutoLtSnsrNightSta "17.12.00";
BA_ "GenMsgSendType" BO_ 1058 0;
BA_ "VFrameFormat" BO_ 1058 14;
BA_ "Description" SG_ 1058 BCM_SunRoofOpnSta "-Sunroof open/close state";
BA_ "GenSigSendType" SG_ 1058 BCM_SunRoofOpnSta 4;
BA_ "UserSigValidity" SG_ 1058 BCM_SunRoofOpnSta 0;
BA_ "GenSigTimeoutTime" SG_ 1058 BCM_SunRoofOpnSta 1500;
BA_ "NetworkRequest" SG_ 1058 BCM_SunRoofOpnSta 0;
BA_ "NetworkRequestHoldingTime" SG_ 1058 BCM_SunRoofOpnSta 5000;
BA_ "Version" SG_ 1058 BCM_SunRoofOpnSta "17.12.00";
BA_ "GenMsgSendType" BO_ 1074 0;
BA_ "VFrameFormat" BO_ 1074 14;
BA_ "GenSigSendType" SG_ 1074 USM_EscrtHdLmpSta 4;
BA_ "UserSigValidity" SG_ 1074 USM_EscrtHdLmpSta 0;
BA_ "GenSigTimeoutTime" SG_ 1074 USM_EscrtHdLmpSta 1500;
BA_ "NetworkRequest" SG_ 1074 USM_EscrtHdLmpSta 0;
BA_ "NetworkRequestHoldingTime" SG_ 1074 USM_EscrtHdLmpSta 5000;
BA_ "Version" SG_ 1074 USM_EscrtHdLmpSta "17.12.00";
BA_ "GenSigSendType" SG_ 1074 USM_ArmBzrSta 4;
BA_ "UserSigValidity" SG_ 1074 USM_ArmBzrSta 0;
BA_ "GenSigTimeoutTime" SG_ 1074 USM_ArmBzrSta 1500;
BA_ "NetworkRequest" SG_ 1074 USM_ArmBzrSta 0;
BA_ "NetworkRequestHoldingTime" SG_ 1074 USM_ArmBzrSta 5000;
BA_ "Version" SG_ 1074 USM_ArmBzrSta "17.12.00";
BA_ "Description" SG_ 1074 USM_WlcmMirLtSystTitleOpt "USM Welcome System Title Option";
BA_ "GenSigSendType" SG_ 1074 USM_WlcmMirLtSystTitleOpt 4;
BA_ "UserSigValidity" SG_ 1074 USM_WlcmMirLtSystTitleOpt 0;
BA_ "GenSigTimeoutTime" SG_ 1074 USM_WlcmMirLtSystTitleOpt 1500;
BA_ "NetworkRequest" SG_ 1074 USM_WlcmMirLtSystTitleOpt 0;
BA_ "NetworkRequestHoldingTime" SG_ 1074 USM_WlcmMirLtSystTitleOpt 5000;
BA_ "Version" SG_ 1074 USM_WlcmMirLtSystTitleOpt "17.12.00";
BA_ "Description" SG_ 1074 USM_UnlockWlcmSta "Current setting value for Door Unlock Welcome Setting Option";
BA_ "GenSigSendType" SG_ 1074 USM_UnlockWlcmSta 4;
BA_ "UserSigValidity" SG_ 1074 USM_UnlockWlcmSta 0;
BA_ "GenSigTimeoutTime" SG_ 1074 USM_UnlockWlcmSta 1500;
BA_ "NetworkRequest" SG_ 1074 USM_UnlockWlcmSta 0;
BA_ "NetworkRequestHoldingTime" SG_ 1074 USM_UnlockWlcmSta 5000;
BA_ "Version" SG_ 1074 USM_UnlockWlcmSta "17.12.00";
BA_ "Description" SG_ 1074 USM_SmrtWlcmSta "Current setting value for Smart Key Welcome Setting Option";
BA_ "GenSigSendType" SG_ 1074 USM_SmrtWlcmSta 4;
BA_ "UserSigValidity" SG_ 1074 USM_SmrtWlcmSta 0;
BA_ "GenSigTimeoutTime" SG_ 1074 USM_SmrtWlcmSta 1500;
BA_ "NetworkRequest" SG_ 1074 USM_SmrtWlcmSta 0;
BA_ "NetworkRequestHoldingTime" SG_ 1074 USM_SmrtWlcmSta 5000;
BA_ "Version" SG_ 1074 USM_SmrtWlcmSta "17.12.00";
BA_ "Description" SG_ 1074 USM_RrWiperByGearPosRSta "USM Request value of Rear wiper reverse mode";
BA_ "GenSigSendType" SG_ 1074 USM_RrWiperByGearPosRSta 4;
BA_ "UserSigValidity" SG_ 1074 USM_RrWiperByGearPosRSta 0;
BA_ "GenSigTimeoutTime" SG_ 1074 USM_RrWiperByGearPosRSta 1500;
BA_ "NetworkRequest" SG_ 1074 USM_RrWiperByGearPosRSta 0;
BA_ "NetworkRequestHoldingTime" SG_ 1074 USM_RrWiperByGearPosRSta 5000;
BA_ "Version" SG_ 1074 USM_RrWiperByGearPosRSta "17.12.00";
BA_ "Description" SG_ 1074 USM_RrStRmndSta "Rear seat reminder USM function signal";
BA_ "GenSigSendType" SG_ 1074 USM_RrStRmndSta 4;
BA_ "UserSigValidity" SG_ 1074 USM_RrStRmndSta 0;
BA_ "GenSigTimeoutTime" SG_ 1074 USM_RrStRmndSta 1500;
BA_ "NetworkRequest" SG_ 1074 USM_RrStRmndSta 0;
BA_ "NetworkRequestHoldingTime" SG_ 1074 USM_RrStRmndSta 5000;
BA_ "Version" SG_ 1074 USM_RrStRmndSta "17.12.00";
BA_ "Description" SG_ 1074 USM_PDWAutoOnSta "PDW system automatically on/off setting USM function signal";
BA_ "GenSigSendType" SG_ 1074 USM_PDWAutoOnSta 4;
BA_ "UserSigValidity" SG_ 1074 USM_PDWAutoOnSta 0;
BA_ "GenSigTimeoutTime" SG_ 1074 USM_PDWAutoOnSta 1500;
BA_ "NetworkRequest" SG_ 1074 USM_PDWAutoOnSta 0;
BA_ "NetworkRequestHoldingTime" SG_ 1074 USM_PDWAutoOnSta 5000;
BA_ "Version" SG_ 1074 USM_PDWAutoOnSta "18.04.00";
BA_ "GenMsgSendType" BO_ 1138 0;
BA_ "VFrameFormat" BO_ 1138 14;
BA_ "Description" SG_ 1138 CLU_Crc14Val "The data area for CRC calculation is based on the data length (DLC) of the message DB.
The CRC shall be calculated over the entire data block (excluding the CRC bytes) including the user data, alive counter and Data ID
 
- CRC Polynomial (0x1021) , Initial Value : 0xFFFF, XOR value : 0x0000, Data ID : Message ID + 0xF800 
- The initial value is for CRC calculation and the message should be sent with the calculated result value. 
- The mathematical expression to 16 bit CRC polynomial is given here. G(x) = x16 + x12 + x5 + 1";
BA_ "GenSigSendType" SG_ 1138 CLU_Crc14Val 4;
BA_ "GenSigStartValue" SG_ 1138 CLU_Crc14Val 65535;
BA_ "UserSigValidity" SG_ 1138 CLU_Crc14Val 3;
BA_ "GenSigTimeoutTime" SG_ 1138 CLU_Crc14Val 1500;
BA_ "Version" SG_ 1138 CLU_Crc14Val "18.11.08";
BA_ "Description" SG_ 1138 CLU_AlvCnt14Val "For the first transmission request for a data element the counter shall be initialized with 0 and shall be incremented by 1 for every subsequent send request. 
When the counter reaches the maximum value(0xFF), then it shall restart with 0 for the next send request";
BA_ "GenSigSendType" SG_ 1138 CLU_AlvCnt14Val 4;
BA_ "UserSigValidity" SG_ 1138 CLU_AlvCnt14Val 3;
BA_ "GenSigTimeoutTime" SG_ 1138 CLU_AlvCnt14Val 1500;
BA_ "Version" SG_ 1138 CLU_AlvCnt14Val "18.11.08";
BA_ "Description" SG_ 1138 USM_CluVcAlrmVolSta "Cluster Voice alarm volume status.";
BA_ "GenSigSendType" SG_ 1138 USM_CluVcAlrmVolSta 4;
BA_ "UserSigValidity" SG_ 1138 USM_CluVcAlrmVolSta 3;
BA_ "GenSigTimeoutTime" SG_ 1138 USM_CluVcAlrmVolSta 1500;
BA_ "Version" SG_ 1138 USM_CluVcAlrmVolSta "17.12.03";
BA_ "Description" SG_ 1138 USM_FuelEconomySetSta "Cluster FuelEconomy Setting status.";
BA_ "GenSigSendType" SG_ 1138 USM_FuelEconomySetSta 4;
BA_ "UserSigValidity" SG_ 1138 USM_FuelEconomySetSta 3;
BA_ "GenSigTimeoutTime" SG_ 1138 USM_FuelEconomySetSta 1500;
BA_ "Version" SG_ 1138 USM_FuelEconomySetSta "17.12.03";
BA_ "Description" SG_ 1138 USM_WelcomeSndSta "Cluster Welcome sound status.";
BA_ "GenSigSendType" SG_ 1138 USM_WelcomeSndSta 4;
BA_ "UserSigValidity" SG_ 1138 USM_WelcomeSndSta 3;
BA_ "GenSigTimeoutTime" SG_ 1138 USM_WelcomeSndSta 1500;
BA_ "Version" SG_ 1138 USM_WelcomeSndSta "17.12.03";
BA_ "Description" SG_ 1138 USM_CluDISWrngSta "Cluster DIS Warning status.";
BA_ "GenSigSendType" SG_ 1138 USM_CluDISWrngSta 4;
BA_ "UserSigValidity" SG_ 1138 USM_CluDISWrngSta 3;
BA_ "GenSigTimeoutTime" SG_ 1138 USM_CluDISWrngSta 1500;
BA_ "Version" SG_ 1138 USM_CluDISWrngSta "17.12.03";
BA_ "Description" SG_ 1138 USM_CluMFSWPopupSta "Cluster MFSWPopupStatus.";
BA_ "GenSigSendType" SG_ 1138 USM_CluMFSWPopupSta 4;
BA_ "UserSigValidity" SG_ 1138 USM_CluMFSWPopupSta 3;
BA_ "GenSigTimeoutTime" SG_ 1138 USM_CluMFSWPopupSta 1500;
BA_ "Version" SG_ 1138 USM_CluMFSWPopupSta "17.12.03";
BA_ "Description" SG_ 1138 USM_CluGearPosPopupSta "Cluster GearpositionPopupStatus.";
BA_ "GenSigSendType" SG_ 1138 USM_CluGearPosPopupSta 4;
BA_ "UserSigValidity" SG_ 1138 USM_CluGearPosPopupSta 3;
BA_ "GenSigTimeoutTime" SG_ 1138 USM_CluGearPosPopupSta 1500;
BA_ "Version" SG_ 1138 USM_CluGearPosPopupSta "17.12.03";
BA_ "Description" SG_ 1138 USM_CluFuelEconUnitkmSta "Cluster FuelEconomyUnitkmStatus.";
BA_ "GenSigSendType" SG_ 1138 USM_CluFuelEconUnitkmSta 4;
BA_ "UserSigValidity" SG_ 1138 USM_CluFuelEconUnitkmSta 3;
BA_ "GenSigTimeoutTime" SG_ 1138 USM_CluFuelEconUnitkmSta 1500;
BA_ "Version" SG_ 1138 USM_CluFuelEconUnitkmSta "17.12.03";
BA_ "Description" SG_ 1138 USM_CluAdasVolSta "Cluster AdasVolumeStatus.";
BA_ "GenSigSendType" SG_ 1138 USM_CluAdasVolSta 4;
BA_ "UserSigValidity" SG_ 1138 USM_CluAdasVolSta 3;
BA_ "GenSigTimeoutTime" SG_ 1138 USM_CluAdasVolSta 1500;
BA_ "Version" SG_ 1138 USM_CluAdasVolSta "17.12.03";
BA_ "Description" SG_ 1138 USM_CluFuelEconUnitmiSta "Cluster FuelEconomyUnitmileStatus.";
BA_ "GenSigSendType" SG_ 1138 USM_CluFuelEconUnitmiSta 4;
BA_ "UserSigValidity" SG_ 1138 USM_CluFuelEconUnitmiSta 3;
BA_ "GenSigTimeoutTime" SG_ 1138 USM_CluFuelEconUnitmiSta 1500;
BA_ "Version" SG_ 1138 USM_CluFuelEconUnitmiSta "17.12.03";
BA_ "Description" SG_ 1138 USM_CluIcyRoadWarnSta "Cluster IcyRoadWarningStatus.";
BA_ "GenSigSendType" SG_ 1138 USM_CluIcyRoadWarnSta 4;
BA_ "UserSigValidity" SG_ 1138 USM_CluIcyRoadWarnSta 3;
BA_ "GenSigTimeoutTime" SG_ 1138 USM_CluIcyRoadWarnSta 1500;
BA_ "Version" SG_ 1138 USM_CluIcyRoadWarnSta "17.12.03";
BA_ "Description" SG_ 1138 Wrn_Snd_AdasVolFdbck "Signal for Amp AdasVolume feedback Sound";
BA_ "GenSigSendType" SG_ 1138 Wrn_Snd_AdasVolFdbck 4;
BA_ "UserSigValidity" SG_ 1138 Wrn_Snd_AdasVolFdbck 3;
BA_ "GenSigTimeoutTime" SG_ 1138 Wrn_Snd_AdasVolFdbck 1500;
BA_ "Version" SG_ 1138 Wrn_Snd_AdasVolFdbck "18.08.10";
BA_ "GenMsgSendType" BO_ 1139 0;
BA_ "VFrameFormat" BO_ 1139 14;
BA_ "Description" SG_ 1139 CLU_Crc15Val "The data area for CRC calculation is based on the data length (DLC) of the message DB.
The CRC shall be calculated over the entire data block (excluding the CRC bytes) including the user data, alive counter and Data ID
 
- CRC Polynomial (0x1021) , Initial Value : 0xFFFF, XOR value : 0x0000, Data ID : Message ID + 0xF800 
- The initial value is for CRC calculation and the message should be sent with the calculated result value. 
- The mathematical expression to 16 bit CRC polynomial is given here. G(x) = x16 + x12 + x5 + 1";
BA_ "GenSigSendType" SG_ 1139 CLU_Crc15Val 4;
BA_ "GenSigStartValue" SG_ 1139 CLU_Crc15Val 65535;
BA_ "UserSigValidity" SG_ 1139 CLU_Crc15Val 3;
BA_ "GenSigTimeoutTime" SG_ 1139 CLU_Crc15Val 1500;
BA_ "Version" SG_ 1139 CLU_Crc15Val "18.11.08";
BA_ "Description" SG_ 1139 CLU_AlvCnt15Val "For the first transmission request for a data element the counter shall be initialized with 0 and shall be incremented by 1 for every subsequent send request. 
When the counter reaches the maximum value(0xFF), then it shall restart with 0 for the next send request";
BA_ "GenSigSendType" SG_ 1139 CLU_AlvCnt15Val 4;
BA_ "UserSigValidity" SG_ 1139 CLU_AlvCnt15Val 3;
BA_ "GenSigTimeoutTime" SG_ 1139 CLU_AlvCnt15Val 1500;
BA_ "Version" SG_ 1139 CLU_AlvCnt15Val "18.11.08";
BA_ "Description" SG_ 1139 USM_CluSrvRmndrMdeSta "Cluster ServiceReminderModeStatus";
BA_ "GenSigSendType" SG_ 1139 USM_CluSrvRmndrMdeSta 4;
BA_ "UserSigValidity" SG_ 1139 USM_CluSrvRmndrMdeSta 3;
BA_ "GenSigTimeoutTime" SG_ 1139 USM_CluSrvRmndrMdeSta 1500;
BA_ "Version" SG_ 1139 USM_CluSrvRmndrMdeSta "17.12.03";
BA_ "Description" SG_ 1139 USM_CluSrvRmndrSetSta "Cluster ServiceReminderSetStatus";
BA_ "GenSigSendType" SG_ 1139 USM_CluSrvRmndrSetSta 4;
BA_ "UserSigValidity" SG_ 1139 USM_CluSrvRmndrSetSta 3;
BA_ "GenSigTimeoutTime" SG_ 1139 USM_CluSrvRmndrSetSta 1500;
BA_ "Version" SG_ 1139 USM_CluSrvRmndrSetSta "17.12.03";
BA_ "Description" SG_ 1139 USM_CluSrvRmndrUnitSta "Cluster ServiceReminderUnitStatus";
BA_ "GenSigSendType" SG_ 1139 USM_CluSrvRmndrUnitSta 4;
BA_ "UserSigValidity" SG_ 1139 USM_CluSrvRmndrUnitSta 3;
BA_ "GenSigTimeoutTime" SG_ 1139 USM_CluSrvRmndrUnitSta 1500;
BA_ "Version" SG_ 1139 USM_CluSrvRmndrUnitSta "17.12.03";
BA_ "Description" SG_ 1139 USM_CluSrvRmndrUsrSetPrdSta "Cluster ServiceReminderUserSetPeriodStatus";
BA_ "GenSigSendType" SG_ 1139 USM_CluSrvRmndrUsrSetPrdSta 4;
BA_ "UserSigValidity" SG_ 1139 USM_CluSrvRmndrUsrSetPrdSta 3;
BA_ "GenSigTimeoutTime" SG_ 1139 USM_CluSrvRmndrUsrSetPrdSta 1500;
BA_ "Version" SG_ 1139 USM_CluSrvRmndrUsrSetPrdSta "17.12.03";
BA_ "Description" SG_ 1139 USM_CluSrvRmndrUsrSetDstSta "Cluster ServiceReminderUserSetDistanceStatus";
BA_ "GenSigSendType" SG_ 1139 USM_CluSrvRmndrUsrSetDstSta 4;
BA_ "UserSigValidity" SG_ 1139 USM_CluSrvRmndrUsrSetDstSta 3;
BA_ "GenSigTimeoutTime" SG_ 1139 USM_CluSrvRmndrUsrSetDstSta 1500;
BA_ "Version" SG_ 1139 USM_CluSrvRmndrUsrSetDstSta "17.12.03";
BA_ "Description" SG_ 1139 Clu_SrvRmndrAlrm "Service Reminder Alarm Display for AVN";
BA_ "GenSigSendType" SG_ 1139 Clu_SrvRmndrAlrm 4;
BA_ "UserSigValidity" SG_ 1139 Clu_SrvRmndrAlrm 3;
BA_ "GenSigTimeoutTime" SG_ 1139 Clu_SrvRmndrAlrm 1500;
BA_ "Version" SG_ 1139 Clu_SrvRmndrAlrm "18.10.06";
BA_ "GenMsgSendType" BO_ 1140 0;
BA_ "VFrameFormat" BO_ 1140 14;
BA_ "Description" SG_ 1140 CLU_Crc16Val "The data area for CRC calculation is based on the data length (DLC) of the message DB.
The CRC shall be calculated over the entire data block (excluding the CRC bytes) including the user data, alive counter and Data ID
 
- CRC Polynomial (0x1021) , Initial Value : 0xFFFF, XOR value : 0x0000, Data ID : Message ID + 0xF800 
- The initial value is for CRC calculation and the message should be sent with the calculated result value. 
- The mathematical expression to 16 bit CRC polynomial is given here. G(x) = x16 + x12 + x5 + 1";
BA_ "GenSigSendType" SG_ 1140 CLU_Crc16Val 4;
BA_ "GenSigStartValue" SG_ 1140 CLU_Crc16Val 65535;
BA_ "UserSigValidity" SG_ 1140 CLU_Crc16Val 3;
BA_ "GenSigTimeoutTime" SG_ 1140 CLU_Crc16Val 1500;
BA_ "Version" SG_ 1140 CLU_Crc16Val "18.11.08";
BA_ "Description" SG_ 1140 CLU_AlvCnt16Val "For the first transmission request for a data element the counter shall be initialized with 0 and shall be incremented by 1 for every subsequent send request. 
When the counter reaches the maximum value(0xFF), then it shall restart with 0 for the next send request";
BA_ "GenSigSendType" SG_ 1140 CLU_AlvCnt16Val 4;
BA_ "UserSigValidity" SG_ 1140 CLU_AlvCnt16Val 3;
BA_ "GenSigTimeoutTime" SG_ 1140 CLU_AlvCnt16Val 1500;
BA_ "Version" SG_ 1140 CLU_AlvCnt16Val "18.11.08";
BA_ "Description" SG_ 1140 USM_CluSrvRmndrRemainPrdSta "Cluster ServiceReminderRemainPeriod.  
- BIT 14 : 0(+), 1(-) , BIT 0~13 : 0~9999 days";
BA_ "GenSigSendType" SG_ 1140 USM_CluSrvRmndrRemainPrdSta 4;
BA_ "UserSigValidity" SG_ 1140 USM_CluSrvRmndrRemainPrdSta 3;
BA_ "GenSigTimeoutTime" SG_ 1140 USM_CluSrvRmndrRemainPrdSta 1500;
BA_ "Version" SG_ 1140 USM_CluSrvRmndrRemainPrdSta "17.12.03";
BA_ "Description" SG_ 1140 USM_CluSrvRmndrRemainDstSta "Cluster ServiceReminderRemainDistance.  
- BIT 17 : 0(+), 1(-), BIT 0~16 : 0~99999";
BA_ "GenSigSendType" SG_ 1140 USM_CluSrvRmndrRemainDstSta 4;
BA_ "UserSigValidity" SG_ 1140 USM_CluSrvRmndrRemainDstSta 3;
BA_ "GenSigTimeoutTime" SG_ 1140 USM_CluSrvRmndrRemainDstSta 1500;
BA_ "Version" SG_ 1140 USM_CluSrvRmndrRemainDstSta "17.12.03";
BA_ "GenMsgCycleTime" BO_ 1998 0;
BA_ "GenMsgILSupport" BO_ 1998 0;
BA_ "TpMessage" BO_ 1998 1;
BA_ "GenMsgDelayTime" BO_ 1998 0;
BA_ "VFrameFormat" BO_ 1998 14;
BA_ "UsrSigPurpose" SG_ 1998 CLU_GST_Byte0 2;
BA_ "GenSigSendType" SG_ 1998 CLU_GST_Byte0 2;
BA_ "UserSigValidity" SG_ 1998 CLU_GST_Byte0 0;
BA_ "GenSigTimeoutTime" SG_ 1998 CLU_GST_Byte0 0;
BA_ "NetworkRequest" SG_ 1998 CLU_GST_Byte0 0;
BA_ "NetworkRequestHoldingTime" SG_ 1998 CLU_GST_Byte0 5000;
BA_ "Version" SG_ 1998 CLU_GST_Byte0 "18.01.08";
BA_ "UsrSigPurpose" SG_ 1998 CLU_GST_Byte2 2;
BA_ "GenSigSendType" SG_ 1998 CLU_GST_Byte2 2;
BA_ "UserSigValidity" SG_ 1998 CLU_GST_Byte2 0;
BA_ "GenSigTimeoutTime" SG_ 1998 CLU_GST_Byte2 0;
BA_ "NetworkRequest" SG_ 1998 CLU_GST_Byte2 0;
BA_ "NetworkRequestHoldingTime" SG_ 1998 CLU_GST_Byte2 5000;
BA_ "Version" SG_ 1998 CLU_GST_Byte2 "18.01.08";
BA_ "UsrSigPurpose" SG_ 1998 CLU_GST_Byte3 2;
BA_ "GenSigSendType" SG_ 1998 CLU_GST_Byte3 2;
BA_ "UserSigValidity" SG_ 1998 CLU_GST_Byte3 0;
BA_ "GenSigTimeoutTime" SG_ 1998 CLU_GST_Byte3 0;
BA_ "NetworkRequest" SG_ 1998 CLU_GST_Byte3 0;
BA_ "NetworkRequestHoldingTime" SG_ 1998 CLU_GST_Byte3 5000;
BA_ "Version" SG_ 1998 CLU_GST_Byte3 "18.01.08";
BA_ "UsrSigPurpose" SG_ 1998 CLU_GST_Byte4 2;
BA_ "GenSigSendType" SG_ 1998 CLU_GST_Byte4 2;
BA_ "UserSigValidity" SG_ 1998 CLU_GST_Byte4 0;
BA_ "GenSigTimeoutTime" SG_ 1998 CLU_GST_Byte4 0;
BA_ "NetworkRequest" SG_ 1998 CLU_GST_Byte4 0;
BA_ "NetworkRequestHoldingTime" SG_ 1998 CLU_GST_Byte4 5000;
BA_ "Version" SG_ 1998 CLU_GST_Byte4 "18.01.08";
BA_ "UsrSigPurpose" SG_ 1998 CLU_GST_Byte5 2;
BA_ "GenSigSendType" SG_ 1998 CLU_GST_Byte5 2;
BA_ "UserSigValidity" SG_ 1998 CLU_GST_Byte5 0;
BA_ "GenSigTimeoutTime" SG_ 1998 CLU_GST_Byte5 0;
BA_ "NetworkRequest" SG_ 1998 CLU_GST_Byte5 0;
BA_ "NetworkRequestHoldingTime" SG_ 1998 CLU_GST_Byte5 5000;
BA_ "Version" SG_ 1998 CLU_GST_Byte5 "18.01.08";
BA_ "UsrSigPurpose" SG_ 1998 CLU_GST_Byte6 2;
BA_ "GenSigSendType" SG_ 1998 CLU_GST_Byte6 2;
BA_ "UserSigValidity" SG_ 1998 CLU_GST_Byte6 0;
BA_ "GenSigTimeoutTime" SG_ 1998 CLU_GST_Byte6 0;
BA_ "NetworkRequest" SG_ 1998 CLU_GST_Byte6 0;
BA_ "NetworkRequestHoldingTime" SG_ 1998 CLU_GST_Byte6 5000;
BA_ "Version" SG_ 1998 CLU_GST_Byte6 "18.01.08";
BA_ "UsrSigPurpose" SG_ 1998 CLU_GST_Byte7 2;
BA_ "GenSigSendType" SG_ 1998 CLU_GST_Byte7 2;
BA_ "UserSigValidity" SG_ 1998 CLU_GST_Byte7 0;
BA_ "GenSigTimeoutTime" SG_ 1998 CLU_GST_Byte7 0;
BA_ "NetworkRequest" SG_ 1998 CLU_GST_Byte7 0;
BA_ "NetworkRequestHoldingTime" SG_ 1998 CLU_GST_Byte7 5000;
BA_ "Version" SG_ 1998 CLU_GST_Byte7 "18.01.08";
BA_ "UsrSigPurpose" SG_ 1998 CLU_GST_Byte1 2;
BA_ "GenSigSendType" SG_ 1998 CLU_GST_Byte1 2;
BA_ "UserSigValidity" SG_ 1998 CLU_GST_Byte1 0;
BA_ "GenSigTimeoutTime" SG_ 1998 CLU_GST_Byte1 0;
BA_ "NetworkRequest" SG_ 1998 CLU_GST_Byte1 0;
BA_ "NetworkRequestHoldingTime" SG_ 1998 CLU_GST_Byte1 5000;
BA_ "Version" SG_ 1998 CLU_GST_Byte1 "18.01.08";
BA_ "GenMsgSendType" BO_ 325 0;
BA_ "GenMsgCycleTime" BO_ 325 20;
BA_ "GenMsgCycleTimeFast" BO_ 325 0;
BA_ "GenMsgNrOfRepetition" BO_ 325 0;
BA_ "GenMsgDelayTime" BO_ 325 0;
BA_ "VFrameFormat" BO_ 325 14;
BA_ "Description" SG_ 325 DATC_OutTempSnsrVal "Actual temperature of Ambient Sensor via an A/D converter; converted into degrees
centigrade (℃).
This is raw data of ambient sensor; just transferred from Ambient Sensor Voltage.";
BA_ "UserSigValidity" SG_ 325 DATC_OutTempSnsrVal 7;
BA_ "RoutingFactor" SG_ 325 DATC_OutTempSnsrVal 5;
BA_ "Version" SG_ 325 DATC_OutTempSnsrVal "17.11.00";
BA_ "GenMsgSendType" BO_ 898 0;
BA_ "VFrameFormat" BO_ 898 14;
BA_ "Description" SG_ 898 DATC_TempDispUnitSta "This signal indicates Temp unit of HTR Control (℃, ℉).";
BA_ "GenSigSendType" SG_ 898 DATC_TempDispUnitSta 4;
BA_ "UserSigValidity" SG_ 898 DATC_TempDispUnitSta 6;
BA_ "GenSigTimeoutTime" SG_ 898 DATC_TempDispUnitSta 1500;
BA_ "Version" SG_ 898 DATC_TempDispUnitSta "17.11.00";
BA_ "GenMsgSendType" BO_ 181 0;
BA_ "GenMsgCycleTime" BO_ 181 10;
BA_ "GenMsgCycleTimeFast" BO_ 181 0;
BA_ "GenMsgNrOfRepetition" BO_ 181 0;
BA_ "GenMsgDelayTime" BO_ 181 0;
BA_ "VFrameFormat" BO_ 181 14;
BA_ "Description" SG_ 181 ENG_IsgSta "1. ISG Status expressing CAN message divided by CF_EMS_IsgStat and CF_EMS_IsgStat2 
2. In EMS , CF_EMS_IsgStat and CF_EMS_IsgStat2 do not duplicate the output condition
(EX: If CF_EMS_IsgStat is 01h~07h, CF_EMS_IsgStat2 is 00h)

0x0:ISG is not operating Normal engine operating without ISG/0x1:Idle stop is activated Idle is stopped by ECU during driving/0x2:Automatically started by ECU Engine is automatically started by ECU regardless driver’s volition during idle stop because the condition that ISG function to be prohibited is satisfied, for example SOC is too low./0x3:ISG is prohibited Driver prohibits to activate ISG in order to avoid start lag when he met traffic jam for example./0x4:Fault is existing in ISG There is fault, which is related with ISG. So, idle stop is prohibited and engine started automatically if it is idle stop condition. But for the vehicles that use CF_EMS_ISGStat2, the condition for not-activated battery sensor can be ignored./0x5:Idle stop is inhibited by system automatically for safety and  convenient condition related with battery SOC, brake vacuum pressure etc. ISG function check for EOL./0x6:Auto start is deactivated system automatically to keep safety, Such as door open, hood open and seat belt unlock./0x7:If driver shift gear N to D range without braking to make auto starting. (Economy ISG Only)";
BA_ "UserSigValidity" SG_ 181 ENG_IsgSta 3;
BA_ "RoutingFactor" SG_ 181 ENG_IsgSta 5;
BA_ "Version" SG_ 181 ENG_IsgSta "17.12.02";
BA_ "Description" SG_ 181 ENG_GearShftUpDis "This signal represents gear shift up display status. EMS transmits gear shift up status to the cluster.";
BA_ "UserSigValidity" SG_ 181 ENG_GearShftUpDis 3;
BA_ "RoutingFactor" SG_ 181 ENG_GearShftUpDis 5;
BA_ "Version" SG_ 181 ENG_GearShftUpDis "17.12.00";
BA_ "Description" SG_ 181 ENG_GearShftDnDis "This signal represents gear shift down display status. EMS transmits gear shift down status to the cluster.";
BA_ "UserSigValidity" SG_ 181 ENG_GearShftDnDis 3;
BA_ "RoutingFactor" SG_ 181 ENG_GearShftDnDis 5;
BA_ "Version" SG_ 181 ENG_GearShftDnDis "17.12.00";
BA_ "Description" SG_ 181 ENG_DsrGearPosDis "This signal represents desirable gear position of current driving condition.
EMS transmits desirable gear position to the cluster.";
BA_ "UserSigValidity" SG_ 181 ENG_DsrGearPosDis 3;
BA_ "RoutingFactor" SG_ 181 ENG_DsrGearPosDis 5;
BA_ "Version" SG_ 181 ENG_DsrGearPosDis "17.12.00";
BA_ "Description" SG_ 181 ENG_IsgBzrReq "This signal is for Economy Type ISG. This signal is reminding for preventing sudden starting immediately just after engine restarted or driver shift gear N to D range without braking to make auto starting.
 It transfer first 3 times why if valid one is missing.

In the case of 0x1,
Cluster Action : Buzzer on";
BA_ "UserSigValidity" SG_ 181 ENG_IsgBzrReq 3;
BA_ "RoutingFactor" SG_ 181 ENG_IsgBzrReq 5;
BA_ "Version" SG_ 181 ENG_IsgBzrReq "17.12.00";
BA_ "Description" SG_ 181 ENG_Isg2Sta "1. ISG Status CAN message is divided by CF_EMS_IsgStat and CF_EMS_IsgStat2 
2. CF_EMS_IsgStat and CF_EMS_IsgStat2 do not duplicate the output condition
(EX: If CF_EMS_IsgStat2 is 01h~03h, CF_EMS_IsgStat is 00h)";
BA_ "UserSigValidity" SG_ 181 ENG_Isg2Sta 3;
BA_ "RoutingFactor" SG_ 181 ENG_Isg2Sta 5;
BA_ "Version" SG_ 181 ENG_Isg2Sta "17.12.00";
BA_ "Description" SG_ 181 ENG_EngSpdVal "This signal is generated by crankshaft segment period measurement (in case of an six-cylinder engine, this corresponds to a crankshaft angle of 120°) and measured with a resolution of 4 us.
This signal is represented as a 16 bit value.

The signal is no";
BA_ "UserSigValidity" SG_ 181 ENG_EngSpdVal 3;
BA_ "RoutingFactor" SG_ 181 ENG_EngSpdVal 5;
BA_ "Version" SG_ 181 ENG_EngSpdVal "17.12.00";
BA_ "Description" SG_ 181 ENG_FuelCnsmptVal "The EMS uses the signal 'FCO' (FUEL CONSUMPTION) to inform other ECUs about the current consumption.";
BA_ "UserSigValidity" SG_ 181 ENG_FuelCnsmptVal 3;
BA_ "RoutingFactor" SG_ 181 ENG_FuelCnsmptVal 5;
BA_ "Version" SG_ 181 ENG_FuelCnsmptVal "17.12.00";
BA_ "Description" SG_ 181 ENG_VehSpdLimVal "The vehicle speed which is measured by the EMS has to be sent to CLUSTER. This value is used for limiting speed of EMS. 
EMS limite vehicle speed as this value.";
BA_ "UserSigValidity" SG_ 181 ENG_VehSpdLimVal 3;
BA_ "RoutingFactor" SG_ 181 ENG_VehSpdLimVal 5;
BA_ "Version" SG_ 181 ENG_VehSpdLimVal "18.01.01";
BA_ "Description" SG_ 181 ENG_EngSpdErrSta "This signal identifies an error on searching for a long tooth or on engine speed sensing.
Note : in some cases a limp-home function can be activated in the ECU (the engine speed signal is then based on the camshaft signal), and the engine may run even if an error is present on the crankshaft signal.

There is a specific phase relationship between the signals EngSpdVal and EngSpdErrSta.";
BA_ "UserSigValidity" SG_ 181 ENG_EngSpdErrSta 3;
BA_ "RoutingFactor" SG_ 181 ENG_EngSpdErrSta 5;
BA_ "Version" SG_ 181 ENG_EngSpdErrSta "17.12.00";
BA_ "GenMsgSendType" BO_ 608 0;
BA_ "GenMsgCycleTime" BO_ 608 100;
BA_ "GenMsgCycleTimeFast" BO_ 608 0;
BA_ "GenMsgNrOfRepetition" BO_ 608 0;
BA_ "VFrameFormat" BO_ 608 14;
BA_ "Description" SG_ 608 ENG_KNK_Warning "This signal indicates the result of KNK diagnosis. (KSDS)";
BA_ "UserSigValidity" SG_ 608 ENG_KNK_Warning 4;
BA_ "GenSigTimeoutTime" SG_ 608 ENG_KNK_Warning 1500;
BA_ "RoutingFactor" SG_ 608 ENG_KNK_Warning 2;
BA_ "Version" SG_ 608 ENG_KNK_Warning "18.11.04";
BA_ "Description" SG_ 608 ENG_ImmoLmpSta "This signals indicates that a status of Immobilizer lamp.";
BA_ "UserSigValidity" SG_ 608 ENG_ImmoLmpSta 3;
BA_ "GenSigTimeoutTime" SG_ 608 ENG_ImmoLmpSta 1500;
BA_ "RoutingFactor" SG_ 608 ENG_ImmoLmpSta 2;
BA_ "Version" SG_ 608 ENG_ImmoLmpSta "17.12.00";
BA_ "Description" SG_ 608 ENG_MilSta "The signal indicates the status of the 'Check Engine' light. Lamp activation is either effected statically or clocked (500 ms cycle, code sequence).
An evaluation within 10 ms is required to map the activation process as precisely as possible.
In case of a bus timeout, the value 1 has to be assumed.";
BA_ "UserSigValidity" SG_ 608 ENG_MilSta 3;
BA_ "GenSigTimeoutTime" SG_ 608 ENG_MilSta 1500;
BA_ "RoutingFactor" SG_ 608 ENG_MilSta 2;
BA_ "Version" SG_ 608 ENG_MilSta "17.12.00";
BA_ "GenMsgSendType" BO_ 496 0;
BA_ "GenMsgCycleTime" BO_ 496 50;
BA_ "GenMsgCycleTimeFast" BO_ 496 0;
BA_ "GenMsgNrOfRepetition" BO_ 496 0;
BA_ "VFrameFormat" BO_ 496 14;
BA_ "Description" SG_ 496 EPB_LmpStaDis "This signal indicates status lamp request from EPB to lamp control unit.
- The lamp shall be turned on during initialization. The initialization lasts for 3 seconds after IG-key on.
- If a lamp control unit can not get this signal via CAN due to any errors, the last lamp state before the error should be maintained.
- When EPB apply switch is pressed in the IG-key off sate, the parking brake lamp should be on for 15 seconds and off. In this case, the cluster shall have CAN wake-up capability.

EPB_LmpStaDis(0H) - Parking brake lamp status (Off)
EPB_LmpStaDis(1H) - Parking brake lamp status (On)
EPB_LmpStaDis(2H) - Parking brake lamp status (Blinking at 1Hz)";
BA_ "UserSigValidity" SG_ 496 EPB_LmpStaDis 3;
BA_ "RoutingFactor" SG_ 496 EPB_LmpStaDis 3;
BA_ "Version" SG_ 496 EPB_LmpStaDis "17.12.00";
BA_ "Description" SG_ 496 EPB_FlrLmpStaDis "Information about the failure lamp request from EPB to lamp control unit.

EPB_F_LAMP(0H) - Yellow failure lamp status(Off)
EPB_F_LAMP(1H) - Yellow failure lamp status(On)
EPB_F_LAMP(2H) - Yellow failure lamp status(Blinking at 1 Hz)";
BA_ "UserSigValidity" SG_ 496 EPB_FlrLmpStaDis 3;
BA_ "RoutingFactor" SG_ 496 EPB_FlrLmpStaDis 3;
BA_ "Version" SG_ 496 EPB_FlrLmpStaDis "17.12.00";
BA_ "Description" SG_ 496 EPB_OutDataDis "An EPB can show its information message to driver on a cluster or a display module with this signal. ※ 0x4 is for China";
BA_ "UserSigValidity" SG_ 496 EPB_OutDataDis 3;
BA_ "RoutingFactor" SG_ 496 EPB_OutDataDis 3;
BA_ "Version" SG_ 496 EPB_OutDataDis "17.12.00";
BA_ "Description" SG_ 496 EPB_AlrmReq "This signal indicates that an EPB requests cluster or tone controller to ring the alarm according to the status of an EPB.

Conversion [Condition]
0H : Normal operation
1H : EPB_CLU = 2 or 3
(send signals three time in a row & 1st signal should be sent at the same time as corresponding EPB_CLU 1st Signal)
2H : Dynamic braking[ECD, RWU] (send signal continuously)
3H : Reserved";
BA_ "UserSigValidity" SG_ 496 EPB_AlrmReq 3;
BA_ "RoutingFactor" SG_ 496 EPB_AlrmReq 3;
BA_ "Version" SG_ 496 EPB_AlrmReq "17.12.00";
BA_ "GenMsgSendType" BO_ 96 0;
BA_ "GenMsgCycleTime" BO_ 96 10;
BA_ "GenMsgCycleTimeFast" BO_ 96 0;
BA_ "GenMsgNrOfRepetition" BO_ 96 0;
BA_ "GenMsgDelayTime" BO_ 96 0;
BA_ "VFrameFormat" BO_ 96 14;
BA_ "Description" SG_ 96 AVH_CluDis "An ESC can show its information message to driver on a cluster or a display module with this signal.";
BA_ "UserSigValidity" SG_ 96 AVH_CluDis 3;
BA_ "RoutingFactor" SG_ 96 AVH_CluDis 5;
BA_ "Version" SG_ 96 AVH_CluDis "17.12.00";
BA_ "Description" SG_ 96 AVH_AlrmReq "This signal indicates that an ESC requests cluster or tone controller to ring the alarm according to the status of an ESC";
BA_ "UserSigValidity" SG_ 96 AVH_AlrmReq 3;
BA_ "RoutingFactor" SG_ 96 AVH_AlrmReq 5;
BA_ "Version" SG_ 96 AVH_AlrmReq "17.12.00";
BA_ "Description" SG_ 96 AVH_LmpDis "Information about the status lamp request from ESC (AVH) to cluster.";
BA_ "UserSigValidity" SG_ 96 AVH_LmpDis 3;
BA_ "RoutingFactor" SG_ 96 AVH_LmpDis 5;
BA_ "Version" SG_ 96 AVH_LmpDis "17.12.00";
BA_ "Description" SG_ 96 TCS_LmpSta "The signal indicates the status of the “TCS/ESC Function/Warning Lamp”";
BA_ "UserSigValidity" SG_ 96 TCS_LmpSta 3;
BA_ "RoutingFactor" SG_ 96 TCS_LmpSta 5;
BA_ "Version" SG_ 96 TCS_LmpSta "17.12.00";
BA_ "Description" SG_ 96 TCS_OffLmpSta "The signal indicates the status of the “TCS/ESC OFF SW Lamp”";
BA_ "UserSigValidity" SG_ 96 TCS_OffLmpSta 3;
BA_ "RoutingFactor" SG_ 96 TCS_OffLmpSta 5;
BA_ "Version" SG_ 96 TCS_OffLmpSta "17.12.00";
BA_ "Description" SG_ 96 ESC_OffTempSta "Information regarding the ESC OFF step by switch input of driver.";
BA_ "UserSigValidity" SG_ 96 ESC_OffTempSta 3;
BA_ "RoutingFactor" SG_ 96 ESC_OffTempSta 5;
BA_ "Version" SG_ 96 ESC_OffTempSta "17.12.00";
BA_ "Description" SG_ 96 DBC_WrngLmpSta "The signal indicates the status of the “DBC Warning lamp”";
BA_ "UserSigValidity" SG_ 96 DBC_WrngLmpSta 3;
BA_ "RoutingFactor" SG_ 96 DBC_WrngLmpSta 5;
BA_ "Version" SG_ 96 DBC_WrngLmpSta "17.12.00";
BA_ "Description" SG_ 96 DBC_FuncLmpSta "The signal indicates the status of the “DBC Function lamp”";
BA_ "UserSigValidity" SG_ 96 DBC_FuncLmpSta 3;
BA_ "RoutingFactor" SG_ 96 DBC_FuncLmpSta 5;
BA_ "Version" SG_ 96 DBC_FuncLmpSta "17.12.00";
BA_ "Description" SG_ 96 DBC_ClusterDis "DBC Pop-up Signal for Deactivation";
BA_ "UserSigValidity" SG_ 96 DBC_ClusterDis 3;
BA_ "RoutingFactor" SG_ 96 DBC_ClusterDis 5;
BA_ "Version" SG_ 96 DBC_ClusterDis "18.07.03";
BA_ "Description" SG_ 96 DBC_Sta "Information regarding the status of DBC function.

If the function has not been coded(fixed) yet, this signal will be transmitted as 0xE.";
BA_ "UserSigValidity" SG_ 96 DBC_Sta 3;
BA_ "RoutingFactor" SG_ 96 DBC_Sta 5;
BA_ "Version" SG_ 96 DBC_Sta "18.12.01";
BA_ "GenMsgSendType" BO_ 1160 0;
BA_ "VFrameFormat" BO_ 1160 14;
BA_ "GenSigSendType" SG_ 1160 Lamp_LtSwSta_IBU 4;
BA_ "UserSigValidity" SG_ 1160 Lamp_LtSwSta_IBU 0;
BA_ "GenSigTimeoutTime" SG_ 1160 Lamp_LtSwSta_IBU 1500;
BA_ "NetworkRequest" SG_ 1160 Lamp_LtSwSta_IBU 0;
BA_ "NetworkRequestHoldingTime" SG_ 1160 Lamp_LtSwSta_IBU 5000;
BA_ "Version" SG_ 1160 Lamp_LtSwSta_IBU "18.11.06";
BA_ "GenMsgSendType" BO_ 1161 0;
BA_ "VFrameFormat" BO_ 1161 14;
BA_ "Description" SG_ 1161 Wiper_FrWiperSwSta_IBU "Multifuction Front Wiper Switch Status

The value '0x1' means 'Int Sw On' or 'Auto Sw on' and its status determined by 'C_RainSnsOption' signal

0x1 : Wiper Int Sw on (C_RainSnsOption = 0x0)

0x1 : Wiper Auto Sw on (C_RainSnsOption = 0x1)";
BA_ "GenSigSendType" SG_ 1161 Wiper_FrWiperSwSta_IBU 4;
BA_ "UserSigValidity" SG_ 1161 Wiper_FrWiperSwSta_IBU 0;
BA_ "GenSigTimeoutTime" SG_ 1161 Wiper_FrWiperSwSta_IBU 1500;
BA_ "NetworkRequest" SG_ 1161 Wiper_FrWiperSwSta_IBU 0;
BA_ "NetworkRequestHoldingTime" SG_ 1161 Wiper_FrWiperSwSta_IBU 5000;
BA_ "Version" SG_ 1161 Wiper_FrWiperSwSta_IBU "18.11.06";
BA_ "GenSigSendType" SG_ 1161 Wiper_IntStepSta_IBU 4;
BA_ "UserSigValidity" SG_ 1161 Wiper_IntStepSta_IBU 0;
BA_ "GenSigTimeoutTime" SG_ 1161 Wiper_IntStepSta_IBU 1500;
BA_ "NetworkRequest" SG_ 1161 Wiper_IntStepSta_IBU 0;
BA_ "NetworkRequestHoldingTime" SG_ 1161 Wiper_IntStepSta_IBU 5000;
BA_ "Version" SG_ 1161 Wiper_IntStepSta_IBU "18.11.06";
BA_ "Description" SG_ 1161 Wiper_RrWiperSwSta_IBU "Multifunction Rear Wiper Switch Status";
BA_ "GenSigSendType" SG_ 1161 Wiper_RrWiperSwSta_IBU 4;
BA_ "UserSigValidity" SG_ 1161 Wiper_RrWiperSwSta_IBU 0;
BA_ "GenSigTimeoutTime" SG_ 1161 Wiper_RrWiperSwSta_IBU 1500;
BA_ "NetworkRequest" SG_ 1161 Wiper_RrWiperSwSta_IBU 0;
BA_ "NetworkRequestHoldingTime" SG_ 1161 Wiper_RrWiperSwSta_IBU 5000;
BA_ "Version" SG_ 1161 Wiper_RrWiperSwSta_IBU "18.11.06";
BA_ "GenMsgSendType" BO_ 1041 0;
BA_ "VFrameFormat" BO_ 1041 14;
BA_ "GenSigSendType" SG_ 1041 Warn_DrvDrSwSta 4;
BA_ "UserSigValidity" SG_ 1041 Warn_DrvDrSwSta 0;
BA_ "GenSigTimeoutTime" SG_ 1041 Warn_DrvDrSwSta 1500;
BA_ "NetworkRequest" SG_ 1041 Warn_DrvDrSwSta 0;
BA_ "NetworkRequestHoldingTime" SG_ 1041 Warn_DrvDrSwSta 5000;
BA_ "Version" SG_ 1041 Warn_DrvDrSwSta "17.12.00";
BA_ "GenSigSendType" SG_ 1041 Warn_AsstDrSwSta 4;
BA_ "UserSigValidity" SG_ 1041 Warn_AsstDrSwSta 0;
BA_ "GenSigTimeoutTime" SG_ 1041 Warn_AsstDrSwSta 1500;
BA_ "NetworkRequest" SG_ 1041 Warn_AsstDrSwSta 0;
BA_ "NetworkRequestHoldingTime" SG_ 1041 Warn_AsstDrSwSta 5000;
BA_ "Version" SG_ 1041 Warn_AsstDrSwSta "17.12.00";
BA_ "GenSigSendType" SG_ 1041 Warn_BrkFldSwSta 4;
BA_ "UserSigValidity" SG_ 1041 Warn_BrkFldSwSta 0;
BA_ "GenSigTimeoutTime" SG_ 1041 Warn_BrkFldSwSta 1500;
BA_ "NetworkRequest" SG_ 1041 Warn_BrkFldSwSta 0;
BA_ "NetworkRequestHoldingTime" SG_ 1041 Warn_BrkFldSwSta 5000;
BA_ "Version" SG_ 1041 Warn_BrkFldSwSta "17.12.00";
BA_ "GenSigSendType" SG_ 1041 Warn_HoodSwSta 4;
BA_ "UserSigValidity" SG_ 1041 Warn_HoodSwSta 0;
BA_ "GenSigTimeoutTime" SG_ 1041 Warn_HoodSwSta 1500;
BA_ "NetworkRequest" SG_ 1041 Warn_HoodSwSta 0;
BA_ "NetworkRequestHoldingTime" SG_ 1041 Warn_HoodSwSta 5000;
BA_ "Version" SG_ 1041 Warn_HoodSwSta "17.12.00";
BA_ "GenSigSendType" SG_ 1041 Warn_PrkngBrkSwSta 4;
BA_ "UserSigValidity" SG_ 1041 Warn_PrkngBrkSwSta 0;
BA_ "GenSigTimeoutTime" SG_ 1041 Warn_PrkngBrkSwSta 1500;
BA_ "NetworkRequest" SG_ 1041 Warn_PrkngBrkSwSta 0;
BA_ "NetworkRequestHoldingTime" SG_ 1041 Warn_PrkngBrkSwSta 5000;
BA_ "Version" SG_ 1041 Warn_PrkngBrkSwSta "17.12.00";
BA_ "GenSigSendType" SG_ 1041 Warn_RrLftDrSwSta 4;
BA_ "UserSigValidity" SG_ 1041 Warn_RrLftDrSwSta 0;
BA_ "GenSigTimeoutTime" SG_ 1041 Warn_RrLftDrSwSta 1500;
BA_ "NetworkRequest" SG_ 1041 Warn_RrLftDrSwSta 0;
BA_ "NetworkRequestHoldingTime" SG_ 1041 Warn_RrLftDrSwSta 5000;
BA_ "Version" SG_ 1041 Warn_RrLftDrSwSta "17.12.00";
BA_ "GenSigSendType" SG_ 1041 Warn_RrRtDrSwSta 4;
BA_ "UserSigValidity" SG_ 1041 Warn_RrRtDrSwSta 0;
BA_ "GenSigTimeoutTime" SG_ 1041 Warn_RrRtDrSwSta 1500;
BA_ "NetworkRequest" SG_ 1041 Warn_RrRtDrSwSta 0;
BA_ "NetworkRequestHoldingTime" SG_ 1041 Warn_RrRtDrSwSta 5000;
BA_ "Version" SG_ 1041 Warn_RrRtDrSwSta "17.12.00";
BA_ "GenMsgSendType" BO_ 1042 0;
BA_ "VFrameFormat" BO_ 1042 14;
BA_ "Description" SG_ 1042 ExtLamp_StpLmpLftOpnSta "Stop Lamp Left Open State";
BA_ "GenSigSendType" SG_ 1042 ExtLamp_StpLmpLftOpnSta 4;
BA_ "UserSigValidity" SG_ 1042 ExtLamp_StpLmpLftOpnSta 0;
BA_ "GenSigTimeoutTime" SG_ 1042 ExtLamp_StpLmpLftOpnSta 1500;
BA_ "NetworkRequest" SG_ 1042 ExtLamp_StpLmpLftOpnSta 0;
BA_ "NetworkRequestHoldingTime" SG_ 1042 ExtLamp_StpLmpLftOpnSta 5000;
BA_ "Version" SG_ 1042 ExtLamp_StpLmpLftOpnSta "17.12.00";
BA_ "Description" SG_ 1042 ExtLamp_StpLmpRtOpnSta "Stop Lamp Right Open State";
BA_ "GenSigSendType" SG_ 1042 ExtLamp_StpLmpRtOpnSta 4;
BA_ "UserSigValidity" SG_ 1042 ExtLamp_StpLmpRtOpnSta 0;
BA_ "GenSigTimeoutTime" SG_ 1042 ExtLamp_StpLmpRtOpnSta 1500;
BA_ "NetworkRequest" SG_ 1042 ExtLamp_StpLmpRtOpnSta 0;
BA_ "NetworkRequestHoldingTime" SG_ 1042 ExtLamp_StpLmpRtOpnSta 5000;
BA_ "Version" SG_ 1042 ExtLamp_StpLmpRtOpnSta "17.12.00";
BA_ "GenMsgSendType" BO_ 1043 0;
BA_ "VFrameFormat" BO_ 1043 14;
BA_ "GenSigSendType" SG_ 1043 ExtLamp_TrnSigLmpLftBlnkngSta 4;
BA_ "UserSigValidity" SG_ 1043 ExtLamp_TrnSigLmpLftBlnkngSta 0;
BA_ "GenSigTimeoutTime" SG_ 1043 ExtLamp_TrnSigLmpLftBlnkngSta 1500;
BA_ "NetworkRequest" SG_ 1043 ExtLamp_TrnSigLmpLftBlnkngSta 0;
BA_ "NetworkRequestHoldingTime" SG_ 1043 ExtLamp_TrnSigLmpLftBlnkngSta 5000;
BA_ "Version" SG_ 1043 ExtLamp_TrnSigLmpLftBlnkngSta "17.12.00";
BA_ "GenSigSendType" SG_ 1043 ExtLamp_TrnSigLmpRtBlnkngSta 4;
BA_ "UserSigValidity" SG_ 1043 ExtLamp_TrnSigLmpRtBlnkngSta 0;
BA_ "GenSigTimeoutTime" SG_ 1043 ExtLamp_TrnSigLmpRtBlnkngSta 1500;
BA_ "NetworkRequest" SG_ 1043 ExtLamp_TrnSigLmpRtBlnkngSta 0;
BA_ "NetworkRequestHoldingTime" SG_ 1043 ExtLamp_TrnSigLmpRtBlnkngSta 5000;
BA_ "Version" SG_ 1043 ExtLamp_TrnSigLmpRtBlnkngSta "17.12.00";
BA_ "Description" SG_ 1043 ExtLamp_ExtrnlTailLmpSta "-(Old)C_EXTTail_Act";
BA_ "GenSigSendType" SG_ 1043 ExtLamp_ExtrnlTailLmpSta 4;
BA_ "UserSigValidity" SG_ 1043 ExtLamp_ExtrnlTailLmpSta 0;
BA_ "GenSigTimeoutTime" SG_ 1043 ExtLamp_ExtrnlTailLmpSta 1500;
BA_ "NetworkRequest" SG_ 1043 ExtLamp_ExtrnlTailLmpSta 0;
BA_ "NetworkRequestHoldingTime" SG_ 1043 ExtLamp_ExtrnlTailLmpSta 5000;
BA_ "Version" SG_ 1043 ExtLamp_ExtrnlTailLmpSta "17.12.00";
BA_ "Description" SG_ 1043 ExtLamp_RrFgLmpSta "-(Old)C_RearFog_Act";
BA_ "GenSigSendType" SG_ 1043 ExtLamp_RrFgLmpSta 4;
BA_ "UserSigValidity" SG_ 1043 ExtLamp_RrFgLmpSta 0;
BA_ "GenSigTimeoutTime" SG_ 1043 ExtLamp_RrFgLmpSta 1500;
BA_ "NetworkRequest" SG_ 1043 ExtLamp_RrFgLmpSta 0;
BA_ "NetworkRequestHoldingTime" SG_ 1043 ExtLamp_RrFgLmpSta 5000;
BA_ "Version" SG_ 1043 ExtLamp_RrFgLmpSta "17.12.00";
BA_ "Description" SG_ 1043 Lamp_LedHdLmpSta "This signal is LED headlamp status inform whether LED fail or not which is regulation of ECE, Domestic.

If LED H/Lamp detects LED failure then a cluster shall be turn on to 'LED' indicator in the display panel and It should be to display the words 'Check LED Head Lamp!' on the LCD panel in the cluster module.
 
If LED H/Lamp detects FAN failure then a cluster shall be turn on 'LED' indicator in the display panel and It should be to display the words 'Check LED Head Lamp’s FAN!' on the LCD panel in the cluster module.('LED' Indicator not blink)

1) Priority is higher LED failure than FAN failure.
2) 'LED' indicator off when Normal Conditions.";
BA_ "GenSigSendType" SG_ 1043 Lamp_LedHdLmpSta 4;
BA_ "UserSigValidity" SG_ 1043 Lamp_LedHdLmpSta 3;
BA_ "GenSigTimeoutTime" SG_ 1043 Lamp_LedHdLmpSta 1500;
BA_ "NetworkRequest" SG_ 1043 Lamp_LedHdLmpSta 0;
BA_ "NetworkRequestHoldingTime" SG_ 1043 Lamp_LedHdLmpSta 5000;
BA_ "Version" SG_ 1043 Lamp_LedHdLmpSta "17.12.00";
BA_ "GenMsgSendType" BO_ 1044 0;
BA_ "VFrameFormat" BO_ 1044 14;
BA_ "Description" SG_ 1044 Trunk_TrnkTlgtSwSta "Full Lock SW Status Signal

(TailGate/TrunkLid Tpye all)

1. Luggage or Trunkroom Lamp On/Off

2. TailGate/TrunkLid Open Ind in cluster

3. Normal Open SW

  - SW Off: Full Lock(Full Close state)

  - SW On: ^Full Lock";
BA_ "GenSigSendType" SG_ 1044 Trunk_TrnkTlgtSwSta 4;
BA_ "UserSigValidity" SG_ 1044 Trunk_TrnkTlgtSwSta 0;
BA_ "GenSigTimeoutTime" SG_ 1044 Trunk_TrnkTlgtSwSta 1500;
BA_ "NetworkRequest" SG_ 1044 Trunk_TrnkTlgtSwSta 0;
BA_ "NetworkRequestHoldingTime" SG_ 1044 Trunk_TrnkTlgtSwSta 5000;
BA_ "Version" SG_ 1044 Trunk_TrnkTlgtSwSta "17.12.00";
BA_ "Description" SG_ 1044 USM_OneTouchTrnSigFuncSta "This signal is 

- For One Touch Turn Signal Function,

 the advanced version of One Touch triple turn signal

- Communicated with Cluster for setting USM

- Periodic Event Signal to notice current staus to USM of Cluster";
BA_ "GenSigSendType" SG_ 1044 USM_OneTouchTrnSigFuncSta 4;
BA_ "UserSigValidity" SG_ 1044 USM_OneTouchTrnSigFuncSta 0;
BA_ "GenSigTimeoutTime" SG_ 1044 USM_OneTouchTrnSigFuncSta 1500;
BA_ "NetworkRequest" SG_ 1044 USM_OneTouchTrnSigFuncSta 0;
BA_ "NetworkRequestHoldingTime" SG_ 1044 USM_OneTouchTrnSigFuncSta 5000;
BA_ "Version" SG_ 1044 USM_OneTouchTrnSigFuncSta "17.12.00";
BA_ "GenMsgSendType" BO_ 1046 0;
BA_ "VFrameFormat" BO_ 1046 14;
BA_ "Description" SG_ 1046 Lamp_HdLmpLoLftOpnSta "Head Lamp Low

Left OpenStatus";
BA_ "GenSigSendType" SG_ 1046 Lamp_HdLmpLoLftOpnSta 4;
BA_ "UserSigValidity" SG_ 1046 Lamp_HdLmpLoLftOpnSta 0;
BA_ "GenSigTimeoutTime" SG_ 1046 Lamp_HdLmpLoLftOpnSta 1500;
BA_ "NetworkRequest" SG_ 1046 Lamp_HdLmpLoLftOpnSta 0;
BA_ "NetworkRequestHoldingTime" SG_ 1046 Lamp_HdLmpLoLftOpnSta 5000;
BA_ "Version" SG_ 1046 Lamp_HdLmpLoLftOpnSta "17.12.00";
BA_ "Description" SG_ 1046 Lamp_HdLmpLoRtOpnSta "Head Lamp Low Right OpenStatus";
BA_ "GenSigSendType" SG_ 1046 Lamp_HdLmpLoRtOpnSta 4;
BA_ "UserSigValidity" SG_ 1046 Lamp_HdLmpLoRtOpnSta 0;
BA_ "GenSigTimeoutTime" SG_ 1046 Lamp_HdLmpLoRtOpnSta 1500;
BA_ "NetworkRequest" SG_ 1046 Lamp_HdLmpLoRtOpnSta 0;
BA_ "NetworkRequestHoldingTime" SG_ 1046 Lamp_HdLmpLoRtOpnSta 5000;
BA_ "Version" SG_ 1046 Lamp_HdLmpLoRtOpnSta "17.12.00";
BA_ "Description" SG_ 1046 Lamp_HdLmpHiLftOpnSta "Head Lamp High

Left OpenStatus";
BA_ "GenSigSendType" SG_ 1046 Lamp_HdLmpHiLftOpnSta 4;
BA_ "UserSigValidity" SG_ 1046 Lamp_HdLmpHiLftOpnSta 0;
BA_ "GenSigTimeoutTime" SG_ 1046 Lamp_HdLmpHiLftOpnSta 1500;
BA_ "NetworkRequest" SG_ 1046 Lamp_HdLmpHiLftOpnSta 0;
BA_ "NetworkRequestHoldingTime" SG_ 1046 Lamp_HdLmpHiLftOpnSta 5000;
BA_ "Version" SG_ 1046 Lamp_HdLmpHiLftOpnSta "17.12.00";
BA_ "Description" SG_ 1046 Lamp_HdLmpHiRtOpnSta "Head Lamp High Right OpenStatus";
BA_ "GenSigSendType" SG_ 1046 Lamp_HdLmpHiRtOpnSta 4;
BA_ "UserSigValidity" SG_ 1046 Lamp_HdLmpHiRtOpnSta 0;
BA_ "GenSigTimeoutTime" SG_ 1046 Lamp_HdLmpHiRtOpnSta 1500;
BA_ "NetworkRequest" SG_ 1046 Lamp_HdLmpHiRtOpnSta 0;
BA_ "NetworkRequestHoldingTime" SG_ 1046 Lamp_HdLmpHiRtOpnSta 5000;
BA_ "Version" SG_ 1046 Lamp_HdLmpHiRtOpnSta "17.12.00";
BA_ "Description" SG_ 1046 Lamp_RrTrnSigLmpLftOpnSta "Rear T/SIG Lamp

Left OpenStatus";
BA_ "GenSigSendType" SG_ 1046 Lamp_RrTrnSigLmpLftOpnSta 4;
BA_ "UserSigValidity" SG_ 1046 Lamp_RrTrnSigLmpLftOpnSta 0;
BA_ "GenSigTimeoutTime" SG_ 1046 Lamp_RrTrnSigLmpLftOpnSta 1500;
BA_ "NetworkRequest" SG_ 1046 Lamp_RrTrnSigLmpLftOpnSta 0;
BA_ "NetworkRequestHoldingTime" SG_ 1046 Lamp_RrTrnSigLmpLftOpnSta 5000;
BA_ "Version" SG_ 1046 Lamp_RrTrnSigLmpLftOpnSta "17.12.00";
BA_ "Description" SG_ 1046 Lamp_RrTrnSigLmpRtOpnSta "Rear T/SIG Lamp

Right OpenStatus";
BA_ "GenSigSendType" SG_ 1046 Lamp_RrTrnSigLmpRtOpnSta 4;
BA_ "UserSigValidity" SG_ 1046 Lamp_RrTrnSigLmpRtOpnSta 0;
BA_ "GenSigTimeoutTime" SG_ 1046 Lamp_RrTrnSigLmpRtOpnSta 1500;
BA_ "NetworkRequest" SG_ 1046 Lamp_RrTrnSigLmpRtOpnSta 0;
BA_ "NetworkRequestHoldingTime" SG_ 1046 Lamp_RrTrnSigLmpRtOpnSta 5000;
BA_ "Version" SG_ 1046 Lamp_RrTrnSigLmpRtOpnSta "17.12.00";
BA_ "Description" SG_ 1046 Lamp_FrTrnSigLmpLftOpnSta "Front T/SIG Lamp

Left OpenStatus";
BA_ "GenSigSendType" SG_ 1046 Lamp_FrTrnSigLmpLftOpnSta 4;
BA_ "UserSigValidity" SG_ 1046 Lamp_FrTrnSigLmpLftOpnSta 0;
BA_ "GenSigTimeoutTime" SG_ 1046 Lamp_FrTrnSigLmpLftOpnSta 1500;
BA_ "NetworkRequest" SG_ 1046 Lamp_FrTrnSigLmpLftOpnSta 0;
BA_ "NetworkRequestHoldingTime" SG_ 1046 Lamp_FrTrnSigLmpLftOpnSta 5000;
BA_ "Version" SG_ 1046 Lamp_FrTrnSigLmpLftOpnSta "17.12.00";
BA_ "Description" SG_ 1046 Lamp_FrTrnSigLmpRtOpnSta "Front T/SIG Lamp

Right OpenStatus";
BA_ "GenSigSendType" SG_ 1046 Lamp_FrTrnSigLmpRtOpnSta 4;
BA_ "UserSigValidity" SG_ 1046 Lamp_FrTrnSigLmpRtOpnSta 0;
BA_ "GenSigTimeoutTime" SG_ 1046 Lamp_FrTrnSigLmpRtOpnSta 1500;
BA_ "NetworkRequest" SG_ 1046 Lamp_FrTrnSigLmpRtOpnSta 0;
BA_ "NetworkRequestHoldingTime" SG_ 1046 Lamp_FrTrnSigLmpRtOpnSta 5000;
BA_ "Version" SG_ 1046 Lamp_FrTrnSigLmpRtOpnSta "17.12.00";
BA_ "GenMsgSendType" BO_ 1047 0;
BA_ "VFrameFormat" BO_ 1047 14;
BA_ "GenSigSendType" SG_ 1047 USM_AutoDrLkReq 4;
BA_ "UserSigValidity" SG_ 1047 USM_AutoDrLkReq 0;
BA_ "GenSigTimeoutTime" SG_ 1047 USM_AutoDrLkReq 1500;
BA_ "NetworkRequest" SG_ 1047 USM_AutoDrLkReq 0;
BA_ "NetworkRequestHoldingTime" SG_ 1047 USM_AutoDrLkReq 5000;
BA_ "Version" SG_ 1047 USM_AutoDrLkReq "17.12.00";
BA_ "GenSigSendType" SG_ 1047 USM_AutoDrUnLkReq 4;
BA_ "UserSigValidity" SG_ 1047 USM_AutoDrUnLkReq 0;
BA_ "GenSigTimeoutTime" SG_ 1047 USM_AutoDrUnLkReq 1500;
BA_ "NetworkRequest" SG_ 1047 USM_AutoDrUnLkReq 0;
BA_ "NetworkRequestHoldingTime" SG_ 1047 USM_AutoDrUnLkReq 5000;
BA_ "Version" SG_ 1047 USM_AutoDrUnLkReq "17.12.00";
BA_ "GenSigSendType" SG_ 1047 USM_TwoTrnUnLkCurrentSta 4;
BA_ "UserSigValidity" SG_ 1047 USM_TwoTrnUnLkCurrentSta 0;
BA_ "GenSigTimeoutTime" SG_ 1047 USM_TwoTrnUnLkCurrentSta 1500;
BA_ "NetworkRequest" SG_ 1047 USM_TwoTrnUnLkCurrentSta 0;
BA_ "NetworkRequestHoldingTime" SG_ 1047 USM_TwoTrnUnLkCurrentSta 5000;
BA_ "Version" SG_ 1047 USM_TwoTrnUnLkCurrentSta "17.12.00";
BA_ "Description" SG_ 1047 Lamp_HdLmpHiSta "-(Old)C_HLampHIGH_Act";
BA_ "GenSigSendType" SG_ 1047 Lamp_HdLmpHiSta 4;
BA_ "UserSigValidity" SG_ 1047 Lamp_HdLmpHiSta 0;
BA_ "GenSigTimeoutTime" SG_ 1047 Lamp_HdLmpHiSta 1500;
BA_ "NetworkRequest" SG_ 1047 Lamp_HdLmpHiSta 0;
BA_ "NetworkRequestHoldingTime" SG_ 1047 Lamp_HdLmpHiSta 5000;
BA_ "Version" SG_ 1047 Lamp_HdLmpHiSta "18.08.06";
BA_ "Description" SG_ 1047 Lamp_HdLmpLoSta "-(Old)C_HLampLOW_Act";
BA_ "GenSigSendType" SG_ 1047 Lamp_HdLmpLoSta 4;
BA_ "UserSigValidity" SG_ 1047 Lamp_HdLmpLoSta 0;
BA_ "GenSigTimeoutTime" SG_ 1047 Lamp_HdLmpLoSta 1500;
BA_ "NetworkRequest" SG_ 1047 Lamp_HdLmpLoSta 0;
BA_ "NetworkRequestHoldingTime" SG_ 1047 Lamp_HdLmpLoSta 5000;
BA_ "Version" SG_ 1047 Lamp_HdLmpLoSta "18.08.06";
BA_ "Description" SG_ 1047 Lamp_HdLmpBiFuncLftOpnSta "Bi Function Head Lamp Left OpenStatus";
BA_ "GenSigSendType" SG_ 1047 Lamp_HdLmpBiFuncLftOpnSta 4;
BA_ "UserSigValidity" SG_ 1047 Lamp_HdLmpBiFuncLftOpnSta 0;
BA_ "GenSigTimeoutTime" SG_ 1047 Lamp_HdLmpBiFuncLftOpnSta 1500;
BA_ "NetworkRequest" SG_ 1047 Lamp_HdLmpBiFuncLftOpnSta 0;
BA_ "NetworkRequestHoldingTime" SG_ 1047 Lamp_HdLmpBiFuncLftOpnSta 5000;
BA_ "Version" SG_ 1047 Lamp_HdLmpBiFuncLftOpnSta "17.12.00";
BA_ "Description" SG_ 1047 Lamp_HdLmpBiFuncRtOpnSta "Bi Function Head Lamp Right OpenStatus";
BA_ "GenSigSendType" SG_ 1047 Lamp_HdLmpBiFuncRtOpnSta 4;
BA_ "UserSigValidity" SG_ 1047 Lamp_HdLmpBiFuncRtOpnSta 0;
BA_ "GenSigTimeoutTime" SG_ 1047 Lamp_HdLmpBiFuncRtOpnSta 1500;
BA_ "NetworkRequest" SG_ 1047 Lamp_HdLmpBiFuncRtOpnSta 0;
BA_ "NetworkRequestHoldingTime" SG_ 1047 Lamp_HdLmpBiFuncRtOpnSta 5000;
BA_ "Version" SG_ 1047 Lamp_HdLmpBiFuncRtOpnSta "17.12.00";
BA_ "GenMsgSendType" BO_ 1048 0;
BA_ "VFrameFormat" BO_ 1048 14;
BA_ "Description" SG_ 1048 DriveTypeOption "Drive Type Option
This signal is used to determine driver's seat position('Drive Type') about this vehicle.";
BA_ "GenSigSendType" SG_ 1048 DriveTypeOption 4;
BA_ "UserSigValidity" SG_ 1048 DriveTypeOption 0;
BA_ "GenSigTimeoutTime" SG_ 1048 DriveTypeOption 1500;
BA_ "NetworkRequest" SG_ 1048 DriveTypeOption 0;
BA_ "NetworkRequestHoldingTime" SG_ 1048 DriveTypeOption 5000;
BA_ "Version" SG_ 1048 DriveTypeOption "17.12.00";
BA_ "Description" SG_ 1048 Warn_LftSEA "Command for SEA LH Warning Text on cluster";
BA_ "GenSigSendType" SG_ 1048 Warn_LftSEA 4;
BA_ "UserSigValidity" SG_ 1048 Warn_LftSEA 0;
BA_ "GenSigTimeoutTime" SG_ 1048 Warn_LftSEA 1500;
BA_ "Version" SG_ 1048 Warn_LftSEA "17.12.00";
BA_ "Description" SG_ 1048 Warn_RhtSEA "Command for SEA RH Warning Text on cluster";
BA_ "GenSigSendType" SG_ 1048 Warn_RhtSEA 4;
BA_ "UserSigValidity" SG_ 1048 Warn_RhtSEA 0;
BA_ "GenSigTimeoutTime" SG_ 1048 Warn_RhtSEA 1500;
BA_ "Version" SG_ 1048 Warn_RhtSEA "17.12.00";
BA_ "Description" SG_ 1048 ICU_PowerAutoCutModSta "ICU Delivery Mode State";
BA_ "GenSigSendType" SG_ 1048 ICU_PowerAutoCutModSta 4;
BA_ "UserSigValidity" SG_ 1048 ICU_PowerAutoCutModSta 3;
BA_ "GenSigTimeoutTime" SG_ 1048 ICU_PowerAutoCutModSta 1500;
BA_ "Version" SG_ 1048 ICU_PowerAutoCutModSta "17.12.00";
BA_ "GenMsgSendType" BO_ 1040 0;
BA_ "VFrameFormat" BO_ 1040 14;
BA_ "Description" SG_ 1040 ICU_BS2SoC "This signal is battery State of Charge as calculated by battery sensor.";
BA_ "GenSigSendType" SG_ 1040 ICU_BS2SoC 4;
BA_ "UserSigValidity" SG_ 1040 ICU_BS2SoC 3;
BA_ "GenSigTimeoutTime" SG_ 1040 ICU_BS2SoC 1500;
BA_ "Version" SG_ 1040 ICU_BS2SoC "17.12.00";
BA_ "GenMsgSendType" BO_ 1167 0;
BA_ "GenMsgCycleTime" BO_ 1167 1000;
BA_ "VFrameFormat" BO_ 1167 14;
BA_ "Description" SG_ 1167 Bat_dischrg "Battery discharge notification flag";
BA_ "GenSigSendType" SG_ 1167 Bat_dischrg 4;
BA_ "UserSigValidity" SG_ 1167 Bat_dischrg 3;
BA_ "GenSigTimeoutTime" SG_ 1167 Bat_dischrg 5000;
BA_ "Version" SG_ 1167 Bat_dischrg "18.03.05";
BA_ "GenMsgSendType" BO_ 234 0;
BA_ "GenMsgCycleTime" BO_ 234 10;
BA_ "GenMsgCycleTimeFast" BO_ 234 0;
BA_ "GenMsgNrOfRepetition" BO_ 234 0;
BA_ "GenMsgDelayTime" BO_ 234 0;
BA_ "VFrameFormat" BO_ 234 14;
BA_ "Description" SG_ 234 MDPS_LoamModSta "The signal represent status of the LOAM(Loss Of Assist Mitigation) Mode";
BA_ "UserSigValidity" SG_ 234 MDPS_LoamModSta 3;
BA_ "RoutingFactor" SG_ 234 MDPS_LoamModSta 5;
BA_ "Version" SG_ 234 MDPS_LoamModSta "17.12.00";
BA_ "Description" SG_ 234 MDPS_WrngLmpSta "The signal indicates the ststus of the “MDPS Warning lamp”";
BA_ "UserSigValidity" SG_ 234 MDPS_WrngLmpSta 3;
BA_ "RoutingFactor" SG_ 234 MDPS_WrngLmpSta 5;
BA_ "Version" SG_ 234 MDPS_WrngLmpSta "17.12.00";
BA_ "GenMsgSendType" BO_ 485 0;
BA_ "GenMsgCycleTime" BO_ 485 50;
BA_ "GenMsgCycleTimeFast" BO_ 485 0;
BA_ "GenMsgNrOfRepetition" BO_ 485 0;
BA_ "VFrameFormat" BO_ 485 14;
BA_ "Description" SG_ 485 RCCW_Sta "This signal indicates the Status of RCCW";
BA_ "UserSigValidity" SG_ 485 RCCW_Sta 3;
BA_ "RoutingFactor" SG_ 485 RCCW_Sta 3;
BA_ "Version" SG_ 485 RCCW_Sta "17.12.00";
BA_ "Description" SG_ 485 RCCW_OnOffEquipSt "This signal indicates the on/off status of RCCW";
BA_ "UserSigValidity" SG_ 485 RCCW_OnOffEquipSt 3;
BA_ "RoutingFactor" SG_ 485 RCCW_OnOffEquipSt 3;
BA_ "Version" SG_ 485 RCCW_OnOffEquipSt "17.12.00";
BA_ "Description" SG_ 485 RCCW_LftIndSta "This signal Indicates RCCW Warning Indicator mode for Left side";
BA_ "UserSigValidity" SG_ 485 RCCW_LftIndSta 3;
BA_ "RoutingFactor" SG_ 485 RCCW_LftIndSta 3;
BA_ "Version" SG_ 485 RCCW_LftIndSta "18.10.09";
BA_ "Description" SG_ 485 RCCW_RtIndSta "This signal Indicates RCCW Warning Indicator mode for Right side";
BA_ "UserSigValidity" SG_ 485 RCCW_RtIndSta 3;
BA_ "RoutingFactor" SG_ 485 RCCW_RtIndSta 3;
BA_ "Version" SG_ 485 RCCW_RtIndSta "18.10.09";
BA_ "Description" SG_ 485 RCCW_LftSndWrngSta "This signal indicates RCCW Sound Warning for Rear Left Speaker";
BA_ "UserSigValidity" SG_ 485 RCCW_LftSndWrngSta 3;
BA_ "RoutingFactor" SG_ 485 RCCW_LftSndWrngSta 3;
BA_ "Version" SG_ 485 RCCW_LftSndWrngSta "17.12.00";
BA_ "Description" SG_ 485 RCCW_RtSndWrngSta "This signal indicates RCCW Sound Warning for Rear Right Speaker";
BA_ "UserSigValidity" SG_ 485 RCCW_RtSndWrngSta 3;
BA_ "RoutingFactor" SG_ 485 RCCW_RtSndWrngSta 3;
BA_ "Version" SG_ 485 RCCW_RtSndWrngSta "17.12.00";
BA_ "Description" SG_ 485 RCCW_LftWrngIndBriLvlVal "0x00~FF : Indicator Brightness level of RCCW";
BA_ "UserSigValidity" SG_ 485 RCCW_LftWrngIndBriLvlVal 3;
BA_ "RoutingFactor" SG_ 485 RCCW_LftWrngIndBriLvlVal 3;
BA_ "Version" SG_ 485 RCCW_LftWrngIndBriLvlVal "17.12.00";
BA_ "Description" SG_ 485 RCCW_RtWrngIndBriLvlVal "0x00~FF : Indicator Brightness level of RCCW";
BA_ "UserSigValidity" SG_ 485 RCCW_RtWrngIndBriLvlVal 3;
BA_ "RoutingFactor" SG_ 485 RCCW_RtWrngIndBriLvlVal 3;
BA_ "Version" SG_ 485 RCCW_RtWrngIndBriLvlVal "17.12.00";
BA_ "Description" SG_ 485 RCCA_LftWrngSta "This signal Indicates RCCA Warning state for HMI(Cluster)";
BA_ "UserSigValidity" SG_ 485 RCCA_LftWrngSta 3;
BA_ "RoutingFactor" SG_ 485 RCCA_LftWrngSta 3;
BA_ "Version" SG_ 485 RCCA_LftWrngSta "18.12.06";
BA_ "Description" SG_ 485 RCCA_RtWrngSta "This signal Indicates RCCA Warning state for HMI";
BA_ "UserSigValidity" SG_ 485 RCCA_RtWrngSta 3;
BA_ "RoutingFactor" SG_ 485 RCCA_RtWrngSta 3;
BA_ "Version" SG_ 485 RCCA_RtWrngSta "18.12.06";
BA_ "Description" SG_ 485 RCCA_FuncStat "ESC state";
BA_ "UserSigValidity" SG_ 485 RCCA_FuncStat 3;
BA_ "RoutingFactor" SG_ 485 RCCA_FuncStat 3;
BA_ "Version" SG_ 485 RCCA_FuncStat "17.12.00";
BA_ "Description" SG_ 485 RCCA_Sta "This signal indicates the Status of RCCA";
BA_ "UserSigValidity" SG_ 485 RCCA_Sta 3;
BA_ "RoutingFactor" SG_ 485 RCCA_Sta 3;
BA_ "Version" SG_ 485 RCCA_Sta "17.11.00";
BA_ "Description" SG_ 485 RCCA_OnOffEquipSt "This signal indicates the on/off status of RCCA";
BA_ "UserSigValidity" SG_ 485 RCCA_OnOffEquipSt 3;
BA_ "RoutingFactor" SG_ 485 RCCA_OnOffEquipSt 3;
BA_ "Version" SG_ 485 RCCA_OnOffEquipSt "19.02.05";
BA_ "Description" SG_ 485 SEA_Sta "SEA tells Body control unit to operate Child door lock to lock";
BA_ "UserSigValidity" SG_ 485 SEA_Sta 0;
BA_ "RoutingFactor" SG_ 485 SEA_Sta 3;
BA_ "Version" SG_ 485 SEA_Sta "17.11.00";
BA_ "Description" SG_ 485 SEA_OnOffEquipSta "This signal indicates the on/off status of SEA";
BA_ "UserSigValidity" SG_ 485 SEA_OnOffEquipSta 0;
BA_ "RoutingFactor" SG_ 485 SEA_OnOffEquipSta 3;
BA_ "Version" SG_ 485 SEA_OnOffEquipSta "17.12.00";
BA_ "Description" SG_ 485 SEA_LftWrngSta "This signal carries the information which message shall be displayed to the driver when the system must activate SEA";
BA_ "UserSigValidity" SG_ 485 SEA_LftWrngSta 0;
BA_ "RoutingFactor" SG_ 485 SEA_LftWrngSta 3;
BA_ "Version" SG_ 485 SEA_LftWrngSta "17.12.00";
BA_ "Description" SG_ 485 SEA_RtWrngSta "This signal carries the information which message shall be displayed to the driver when the system must activate SEA";
BA_ "UserSigValidity" SG_ 485 SEA_RtWrngSta 0;
BA_ "RoutingFactor" SG_ 485 SEA_RtWrngSta 3;
BA_ "Version" SG_ 485 SEA_RtWrngSta "17.12.00";
BA_ "GenMsgSendType" BO_ 346 0;
BA_ "GenMsgCycleTime" BO_ 346 10;
BA_ "GenMsgCycleTimeFast" BO_ 346 0;
BA_ "GenMsgNrOfRepetition" BO_ 346 0;
BA_ "GenMsgDelayTime" BO_ 346 0;
BA_ "VFrameFormat" BO_ 346 14;
BA_ "Description" SG_ 346 SCU_FF_PosActSta "This signal indicates where motor is located.
SCU ECU provides information of the actual motor position.";
BA_ "GenSigStartValue" SG_ 346 SCU_FF_PosActSta 9;
BA_ "UserSigValidity" SG_ 346 SCU_FF_PosActSta 3;
BA_ "RoutingFactor" SG_ 346 SCU_FF_PosActSta 5;
BA_ "Version" SG_ 346 SCU_FF_PosActSta "18.08.07";
BA_ "GenMsgSendType" BO_ 1061 0;
BA_ "VFrameFormat" BO_ 1061 14;
BA_ "Description" SG_ 1061 Warn_DeActvWrngSta "-(Old)C_Deactivation_Warning";
BA_ "GenSigSendType" SG_ 1061 Warn_DeActvWrngSta 4;
BA_ "UserSigValidity" SG_ 1061 Warn_DeActvWrngSta 0;
BA_ "GenSigTimeoutTime" SG_ 1061 Warn_DeActvWrngSta 1500;
BA_ "Version" SG_ 1061 Warn_DeActvWrngSta "17.12.00";
BA_ "Description" SG_ 1061 Warn_DisWrngSta "-(Old)C_PICWarningIND

Changed Value Table ('15 1/12)

: 0x4 : Not Locked Warning → AC_Plug_Connected_Warning

for EV/PHEV SMK Warning Logic(Cranking Trial with AC Plug Connected)";
BA_ "GenSigSendType" SG_ 1061 Warn_DisWrngSta 4;
BA_ "UserSigValidity" SG_ 1061 Warn_DisWrngSta 0;
BA_ "GenSigTimeoutTime" SG_ 1061 Warn_DisWrngSta 1500;
BA_ "Version" SG_ 1061 Warn_DisWrngSta "17.12.00";
BA_ "Description" SG_ 1061 Warn_IdOutWrngSta "-(Old)C_IDOUT_WNG";
BA_ "GenSigSendType" SG_ 1061 Warn_IdOutWrngSta 4;
BA_ "UserSigValidity" SG_ 1061 Warn_IdOutWrngSta 0;
BA_ "GenSigTimeoutTime" SG_ 1061 Warn_IdOutWrngSta 1500;
BA_ "Version" SG_ 1061 Warn_IdOutWrngSta "17.12.00";
BA_ "Description" SG_ 1061 Warn_KeyBattLoWrngSta "-(Old)C_KeyBATDischargeWarning";
BA_ "GenSigSendType" SG_ 1061 Warn_KeyBattLoWrngSta 4;
BA_ "UserSigValidity" SG_ 1061 Warn_KeyBattLoWrngSta 0;
BA_ "GenSigTimeoutTime" SG_ 1061 Warn_KeyBattLoWrngSta 1500;
BA_ "Version" SG_ 1061 Warn_KeyBattLoWrngSta "17.12.00";
BA_ "Description" SG_ 1061 Warn_ImmoLmpOnReq "-(Old)C_ImmoLp";
BA_ "GenSigSendType" SG_ 1061 Warn_ImmoLmpOnReq 4;
BA_ "UserSigValidity" SG_ 1061 Warn_ImmoLmpOnReq 0;
BA_ "GenSigTimeoutTime" SG_ 1061 Warn_ImmoLmpOnReq 1500;
BA_ "Version" SG_ 1061 Warn_ImmoLmpOnReq "17.12.00";
BA_ "GenMsgSendType" BO_ 64 0;
BA_ "GenMsgCycleTime" BO_ 64 10;
BA_ "GenMsgCycleTimeFast" BO_ 64 0;
BA_ "GenMsgNrOfRepetition" BO_ 64 0;
BA_ "GenMsgDelayTime" BO_ 64 0;
BA_ "VFrameFormat" BO_ 64 14;
BA_ "Description" SG_ 64 TCU_EngRpmDisSta "Flag for Engine RPM(from TCU) Display on Cluster, Only when this flag is set to 1, Cluster shall display the Engine RPM from TCU";
BA_ "UserSigValidity" SG_ 64 TCU_EngRpmDisSta 3;
BA_ "RoutingFactor" SG_ 64 TCU_EngRpmDisSta 5;
BA_ "Version" SG_ 64 TCU_EngRpmDisSta "17.11.00";
BA_ "Description" SG_ 64 TCU_EngRpmDis "Engine RPM from TCU (Only for the display on Cluster)";
BA_ "UserSigValidity" SG_ 64 TCU_EngRpmDis 3;
BA_ "RoutingFactor" SG_ 64 TCU_EngRpmDis 5;
BA_ "Version" SG_ 64 TCU_EngRpmDis "17.11.00";
BA_ "Description" SG_ 64 TCU_SprtyIndxSta "Sporty index based on the driver's driving behaviour";
BA_ "UserSigValidity" SG_ 64 TCU_SprtyIndxSta 3;
BA_ "RoutingFactor" SG_ 64 TCU_SprtyIndxSta 5;
BA_ "Version" SG_ 64 TCU_SprtyIndxSta "17.11.00";
BA_ "Description" SG_ 64 TCU_DrvngModDis "Driving mode display by TCU";
BA_ "UserSigValidity" SG_ 64 TCU_DrvngModDis 3;
BA_ "RoutingFactor" SG_ 64 TCU_DrvngModDis 5;
BA_ "Version" SG_ 64 TCU_DrvngModDis "17.11.00";
BA_ "Description" SG_ 64 TCU_SmrtShftSta "Information of SmartShift";
BA_ "UserSigValidity" SG_ 64 TCU_SmrtShftSta 3;
BA_ "RoutingFactor" SG_ 64 TCU_SmrtShftSta 5;
BA_ "Version" SG_ 64 TCU_SmrtShftSta "17.11.00";
BA_ "Description" SG_ 64 TCU_ShftPtrnSta "It is an ID of current shift pattern which is being used by TCU.
The ID is assigned for each TCU.";
BA_ "UserSigValidity" SG_ 64 TCU_ShftPtrnSta 3;
BA_ "RoutingFactor" SG_ 64 TCU_ShftPtrnSta 5;
BA_ "Version" SG_ 64 TCU_ShftPtrnSta "17.11.00";
BA_ "Description" SG_ 64 TCU_GearSlctDis "Position (P, R, N..), which was identified by the gear selector.
In case the gear selector is in a intermediate position, the last clear recognized position is used.
There is no specific phase relationship between the output and any other signal.";
BA_ "GenSigStartValue" SG_ 64 TCU_GearSlctDis 9;
BA_ "UserSigValidity" SG_ 64 TCU_GearSlctDis 3;
BA_ "RoutingFactor" SG_ 64 TCU_GearSlctDis 5;
BA_ "Version" SG_ 64 TCU_GearSlctDis "17.11.00";
BA_ "Description" SG_ 64 TCU_Typ "Information regarding the type of transmission - Step A/T or CVT or DCT / AMT / eClutch";
BA_ "UserSigValidity" SG_ 64 TCU_Typ 3;
BA_ "RoutingFactor" SG_ 64 TCU_Typ 5;
BA_ "Version" SG_ 64 TCU_Typ "18.12.02";
BA_ "Description" SG_ 64 TCU_TqRdctnVal "The TCU requests a torque reduction via this signal to the EMS. 

If MSB is 1, this signal is - value.
else, this signal is +value.
0~10bit is used for absolute value.";
BA_ "GenSigStartValue" SG_ 64 TCU_TqRdctnVal 2047;
BA_ "UserSigValidity" SG_ 64 TCU_TqRdctnVal 3;
BA_ "RoutingFactor" SG_ 64 TCU_TqRdctnVal 5;
BA_ "Version" SG_ 64 TCU_TqRdctnVal "18.01.02";
BA_ "Description" SG_ 64 TCU_GearStepTyp "This signal indicates number of gear steps of step type automatic transmission(A/T) or Dual Clutch Transmission(DCT). A vehicle can have A/T or DCT variant according to its option, for example 4-speed A/T or 5-speed A/T can be equipped in the same kind of vehicles and other control systems (e.g. ESC, TCS, …) can need this information to apply appropriate control logic.

The CVT (Continuously Variable Transmission) should set this signal to 00H.";
BA_ "UserSigValidity" SG_ 64 TCU_GearStepTyp 3;
BA_ "RoutingFactor" SG_ 64 TCU_GearStepTyp 5;
BA_ "Version" SG_ 64 TCU_GearStepTyp "17.11.00";
BA_ "Description" SG_ 64 TCU_GearShftSta "SWI_GS indicates whether a gear change is being executed in the gearbox.

Note : Gear change means a gear shift at D-range and Garage shift(PRND).";
BA_ "UserSigValidity" SG_ 64 TCU_GearShftSta 3;
BA_ "RoutingFactor" SG_ 64 TCU_GearShftSta 5;
BA_ "Version" SG_ 64 TCU_GearShftSta "17.11.00";
BA_ "Description" SG_ 64 TCU_CurrGearSta "CUR_GR indicates the gear speed which is currently engaged in the gearbox.";
BA_ "UserSigValidity" SG_ 64 TCU_CurrGearSta 3;
BA_ "RoutingFactor" SG_ 64 TCU_CurrGearSta 5;
BA_ "Version" SG_ 64 TCU_CurrGearSta "17.11.00";
BA_ "Description" SG_ 64 TCU_TrgtGearSta "CF_Tcu_TarGr informs about the speed, which is currently engaged in the gearbox, or, in case of a gear change (SWI_GS), which speed is reached.

Note: Gear changes covering more than one speed are also possible.
In the P and N positions, the frictional connection is interrupted hydraulically.
Depending on the type of error, the 3rd or 4th (forward) speed, and the R (reverse) speed are engaged in the limp home program.";
BA_ "UserSigValidity" SG_ 64 TCU_TrgtGearSta 3;
BA_ "RoutingFactor" SG_ 64 TCU_TrgtGearSta 5;
BA_ "Version" SG_ 64 TCU_TrgtGearSta "17.11.00";
BA_ "Description" SG_ 64 TCU_CluTrgtGearSta "TCH_CluTrgtGearSta informs about target gear of SS timing 
(For indicating Paddle shift or Manual mode on cluster)";
BA_ "UserSigValidity" SG_ 64 TCU_CluTrgtGearSta 3;
BA_ "RoutingFactor" SG_ 64 TCU_CluTrgtGearSta 5;
BA_ "Version" SG_ 64 TCU_CluTrgtGearSta "17.11.00";
BA_ "Description" SG_ 64 TCU_CluTrgtGearConfg "This signal indicates the signal source configuration of target gear for CLU";
BA_ "UserSigValidity" SG_ 64 TCU_CluTrgtGearConfg 3;
BA_ "RoutingFactor" SG_ 64 TCU_CluTrgtGearConfg 5;
BA_ "Version" SG_ 64 TCU_CluTrgtGearConfg "18.08.01";
BA_ "GenMsgSendType" BO_ 106 0;
BA_ "GenMsgCycleTime" BO_ 106 10;
BA_ "GenMsgCycleTimeFast" BO_ 106 0;
BA_ "GenMsgNrOfRepetition" BO_ 106 0;
BA_ "GenMsgDelayTime" BO_ 106 0;
BA_ "VFrameFormat" BO_ 106 14;
BA_ "Description" SG_ 106 TCU_ActvEcoRdySta "TCU is ready to perform ‘Active Eco’ function. OR
TCU performs ‘Active Eco’ function.";
BA_ "UserSigValidity" SG_ 106 TCU_ActvEcoRdySta 3;
BA_ "RoutingFactor" SG_ 106 TCU_ActvEcoRdySta 5;
BA_ "Version" SG_ 106 TCU_ActvEcoRdySta "17.11.00";
BA_ "GenMsgSendType" BO_ 720 0;
BA_ "GenMsgCycleTime" BO_ 720 100;
BA_ "GenMsgCycleTimeFast" BO_ 720 0;
BA_ "GenMsgNrOfRepetition" BO_ 720 0;
BA_ "VFrameFormat" BO_ 720 14;
BA_ "Description" SG_ 720 TCU_WrngMsgSta "This signal indicates the status of “TCU Warning message”";
BA_ "UserSigValidity" SG_ 720 TCU_WrngMsgSta 3;
BA_ "GenSigTimeoutTime" SG_ 720 TCU_WrngMsgSta 1500;
BA_ "RoutingFactor" SG_ 720 TCU_WrngMsgSta 2;
BA_ "Version" SG_ 720 TCU_WrngMsgSta "17.11.00";
BA_ "Description" SG_ 720 TCU_VehStpTimeDis "Vehicle Stop Time, during which the vehicle should be stopped when both clutches of DCT are overheated";
BA_ "UserSigValidity" SG_ 720 TCU_VehStpTimeDis 3;
BA_ "GenSigTimeoutTime" SG_ 720 TCU_VehStpTimeDis 1500;
BA_ "RoutingFactor" SG_ 720 TCU_VehStpTimeDis 2;
BA_ "Version" SG_ 720 TCU_VehStpTimeDis "17.11.00";
BA_ "Description" SG_ 720 TCU_CurCltTemp "Described information named as color with its severity of Current Clutch Temperature
(degrees Celsius)";
BA_ "GenSigTimeoutTime" SG_ 720 TCU_CurCltTemp 1500;
BA_ "RoutingFactor" SG_ 720 TCU_CurCltTemp 2;
BA_ "Version" SG_ 720 TCU_CurCltTemp "17.11.00";
BA_ "Description" SG_ 720 TCU_AvgCltTemp "This signal indicates clutch temperature gage for Cluster 
0 ~ 9 : Normal
10 ~ 13 : Warning
14 ~ 15 : Emergency";
BA_ "GenSigTimeoutTime" SG_ 720 TCU_AvgCltTemp 1500;
BA_ "RoutingFactor" SG_ 720 TCU_AvgCltTemp 2;
BA_ "Version" SG_ 720 TCU_AvgCltTemp "17.11.00";
BA_ "Description" SG_ 720 DCT_HillHldWrng "Warning Message when a driver maintain 'HILL HOLD' condition longer than the specified time.";
BA_ "UserSigValidity" SG_ 720 DCT_HillHldWrng 3;
BA_ "GenSigTimeoutTime" SG_ 720 DCT_HillHldWrng 1500;
BA_ "RoutingFactor" SG_ 720 DCT_HillHldWrng 2;
BA_ "Version" SG_ 720 DCT_HillHldWrng "18.08.02";
BA_ "Description" SG_ 720 DCT_CltchBrstWrng "Warning Message for Clutch Burst";
BA_ "UserSigValidity" SG_ 720 DCT_CltchBrstWrng 3;
BA_ "GenSigTimeoutTime" SG_ 720 DCT_CltchBrstWrng 1500;
BA_ "RoutingFactor" SG_ 720 DCT_CltchBrstWrng 2;
BA_ "Version" SG_ 720 DCT_CltchBrstWrng "18.08.02";
BA_ "Description" SG_ 720 DCT_WrngSndSta "DCT Warning Sound. (Clutch high temperature and so on.)
Bit0 : Sound1
Bit1 : Sound2
Bit2 : Blinking gear position
Bit3 : reserved";
BA_ "UserSigValidity" SG_ 720 DCT_WrngSndSta 3;
BA_ "GenSigTimeoutTime" SG_ 720 DCT_WrngSndSta 1500;
BA_ "RoutingFactor" SG_ 720 DCT_WrngSndSta 2;
BA_ "Version" SG_ 720 DCT_WrngSndSta "18.08.02";
VAL_ 111 ABS__WrngLmpSta 0 "ABS Warning lamp OFF" 1 "ABS Warning lamp ON" 2 "Not used" 3 "Error Indicator" ;
VAL_ 111 EBD__WrngLmpSta 0 "EBD Warning lamp OFF" 1 "EBD Warning lamp ON" 2 "Not used" 3 "Error Indicator" ;
VAL_ 111 ESC__BrkLtActSta 0 "No request" 1 "Activate brake lights" 2 "Not used" 3 "Error Indicator" ;
VAL_ 352 FCA_OnOffEquipSta 0 "Default" 1 "Off" 2 "Warning" 3 "Assist" 4 "Reserved" 5 "Reserved" 6 "Reserved" 7 "Invalid" ;
VAL_ 352 FCA_SysFlrSta 0 "Normal" 1 "Temp. Unavailable by Camera" 2 "Temp. Unavailable by Radar" 3 "Service Required" 4 "Temp. Unavailable by Camera (Camera only)" 5 "Reserved" 6 "Reserved" 7 "Reserved" ;
VAL_ 352 FCA_WrngLvlSta 0 "No warning" 1 "Warning level 1" 2 "Warning level 2" 3 "Warning level 3" ;
VAL_ 352 FCA_VehStpReq 0 "No request" 1 "Stop control is required" 2 "Reserved" 3 "Error Indicator" ;
VAL_ 352 FCA_SnstvtyModRetVal 0 "Default" 1 "Late" 2 "Normal" 3 "Early" 4 "Reserved" 5 "Reserved" 6 "Reserved" 7 "Invalid" ;
VAL_ 352 FCA_WrngTrgtDis 0 "No warning" 1 "FCA-Pedestrian" 2 "Reserved" 3 "FCA-Cyclist" 4 "Reserved" 5 "FCA-Car" 6 "Reserved" 7 "FCA-JC(L)" 8 "FCA-JC®" 9 "Reserved" 10 "Reserved" 11 "FCA-JT(L)" 12 "FCA-JT(R)" 13 "Reserved" 14 "Reserved" ;
VAL_ 298 LKA_OptUsmSta 0 "None LKA/LDW Option (Default)" 1 "LDW" 2 "LKA" 3 "Reserved" 4 "LDW Only (None LKA)" 5 "LDW only OFF (None LKA)" 6 "LDW/LKA OFF" 7 "Invalid" ;
VAL_ 298 LKA_RcgSta 0 "Not Recognized" 1 "Left Lane Recognition" 2 "Right Lane Recognition" 3 "Full Lane Recognition" 4 "Reserved" 5 "Reserved" 6 "Reserved" 7 "Reserved" ;
VAL_ 298 LKA_LHLnWrnSta 0 "No Warning" 1 "Haptic Warning and Display" 2 "Acoustic Warning and Display" 3 "Reserved" ;
VAL_ 298 LKA_RHLnWrnSta 0 "No Warning" 1 "Haptic Warning and Display" 2 "Acoustic Warning and Display" 3 "Reserved" ;
VAL_ 298 LKA_HndsoffSnd 0 "Off" 1 "Hands-off Sound Warning" 2 "Reserved" 3 "Reserved" ;
VAL_ 298 LKA_StrSnd 0 "Off" 1 "Warning" 2 "Reserved" 3 "Reserved" ;
VAL_ 298 LKA_SysIndReq 0 "Off" 1 "Unavailable_(Grey On)" 2 "Lane Recognized_(Green On)" 3 "Lane Departure_(Green Blink)" 4 "System Fail_(Orange On)" 5 "Not Calibrated_(Orange Blink)" 6 "Regulation_(Orange On)" 7 "Reserved" ;
VAL_ 298 ADAS_ActToiSta 0 "De-activate TOI" 1 "Activate TOI" 2 "Reserved" 3 "Error indicator" ;
VAL_ 298 LKA_SysWrn 0 "No Info" 1 "Reserved" 2 "Reserved" 3 "Reserved" 4 "Hands-Off Warning 1" 5 "Hands-Off Warning 2" 6 "Hands-Off Warning 3" 7 "Reserved" 8 "Reserved" 9 "System Automatic off" 10 "Reserved" 11 "Reserved" 12 "Reserved" 13 "Reserved" 14 "Reserved" 15 "System Fail" ;
VAL_ 298 LKA_UsmMod 0 "NONE" 1 "LKA 1 mode" 2 "LKA 2 mode" 3 "LDW" ;
VAL_ 480 HDA_OptUsmSta 0 "Not Applied" 1 "Function Off" 2 "Function On" 3 "Reserved" 4 "Reserved" 5 "Reserved" 6 "Reserved" 7 "Invalid (Fail)" ;
VAL_ 480 HDA_CntrlModSta 0 "System Deactive (Default)" 1 "System Ready" 2 "System Active" 3 "Reserved" ;
VAL_ 480 HDA_InfoPUDis 0 "No pop-up" 1 "system start pop-up" 2 "system auto disengaged pop-up by highway off" 3 "System Fail pop up (LFA)" 4 "System Fail pop up (HDA)" 5 "Hands-off pop up" 6 "Hands-off pop up w/ sound" 7 "System Automatic off" ;
VAL_ 480 HDA_LFA_SymSta 0 "Off" 1 "Gray" 2 "Green" 3 "Green blink" ;
VAL_ 480 HDA_LFA_WrnSnd 0 "Off" 1 "Additional Warning Sound" 2 "Reserved" 3 "Error indicator" ;
VAL_ 480 HDA_InfoPUDis1 0 "No Pop-up" 1 "System Automatic off (LFA)" 2 "System Automatic off (HDA)" 3 "Reserved" 4 "Reserved" 5 "Reserved" 6 "Not Used" 7 "Error Indicator" ;
VAL_ 421 AWD_OpModLkSta 0 "LOCK mode is inactive" 1 "LOCK mode is activated" 2 "Not used" 3 "Error indicator" ;
VAL_ 993 SBR_StBltWrngBzrSta 0 "Warning Off" 1 "Buzzer Hold" 2 "Buzzer On" 3 "Reserved" 4 "Reserved" 5 "Reseved" 6 "Not Used" 7 "Error Indicator" ;
VAL_ 993 SBR_DrvStBltIndSta 0 "Off" 1 "On" 2 "Not Used" 3 "Error Indicator" ;
VAL_ 994 Warn_BzrWrngSta 0 "Off" 1 "SeatBelt Warning" 2 "Key Operated Warning" 3 "Parking Brake Warning" 4 "Sun Roof Open Warning" 5 "Key Learning Sound(NoSMKOption" 6 "ICE Warning" 7 "Rear Fog Warning" 8 "Reserved" 9 "Reserved" 10 "Reserved" 11 "Reserved" 12 "Reserved" 13 "Reserved" 14 "Not Used" 15 "Error Indicator" ;
VAL_ 994 Warn_BCMWrngSta 0 "Off" 1 "Power off request warning" 2 "Shift P request Warning" 3 "Reserved" 4 "Reserved" 5 "Reseved" 6 "Reseved" 7 "Reserved" 8 "Reserved" 9 "Reserved" 10 "Reserved" 11 "Reserved" 12 "Reserved" 13 "Reserved" 14 "Not Used" 15 "Error Indicator" ;
VAL_ 994 Warn_RrStRmndSysSta 0 "Default" 1 "System ON" 2 "System OFF" 3 "Error Indicator" ;
VAL_ 994 Warn_RrStRmndAlrmInfo 0 "Off" 1 "Rear Seat Reminder" 2 "Rear Seat Reminder 1st Only" 3 "Reserved" 4 "Reserved" 5 "Reseved" 6 "Not Used" 7 "Error Indicator" ;
VAL_ 994 Warn_RoaErr 0 "Off" 1 "SensorError( Malfunction)" 2 "Reserved" 3 "Reserved" 4 "Reserved" 5 "Reseved" 6 "Not Used" 7 "Error Indicator" ;
VAL_ 997 PDW_OptTyp 0 "Non" 1 "PDW R" 2 "PDW FR" 3 "Reserved" 4 "Reserved" 5 "Reseved" 6 "Not Used" 7 "Error Indicator" ;
VAL_ 997 PDW_SysChkSndSta 0 "Off" 1 "R_Confirm" 2 "Error" 3 "Reserved" 4 "Reserved" 5 "Reseved" 6 "Not Used" 7 "Error Indicator" ;
VAL_ 997 PDW_SysOnSta 0 "Off" 1 "On" 2 "Reserved" 3 "Reserved" 4 "Reserved" 5 "Reseved" 6 "Not Used" 7 "Error Indicator" ;
VAL_ 997 PDW_FrCtrWrngLvlDis 0 "Off" 1 "1st warning" 2 "2nd warning" 3 "3rd warning" 4 "Error" 5 "Reseved" 6 "Not Used" 7 "Error Indicator" ;
VAL_ 997 PDW_FrLftWrngLvlDis 0 "Off" 1 "1st warning" 2 "2nd warning" 3 "3rd warning" 4 "Error" 5 "Reseved" 6 "Not Used" 7 "Error Indicator" ;
VAL_ 997 PDW_FrRtWrngLvlDis 0 "Off" 1 "1st warning" 2 "2nd warning" 3 "3rd warning" 4 "Error" 5 "Reseved" 6 "Not Used" 7 "Error Indicator" ;
VAL_ 997 PDW_FrSnsrWrngLvlSta 0 "Off" 1 "1st Waring" 2 "2nd Waring" 3 "3rd Warning" 4 "Reserved" 5 "Reseved" 6 "Not Used" 7 "Error Indicator" ;
VAL_ 998 PDW_RrCtrWrngLvlDis 0 "Off" 1 "1st warning" 2 "2nd warning" 3 "3rd warning" 4 "Error" 5 "Reseved" 6 "Not Used" 7 "Error Indicator" ;
VAL_ 998 PDW_RrLftWrngLvlDis 0 "Off" 1 "1st warning" 2 "2nd warning" 3 "3rd warning" 4 "Error" 5 "Reseved" 6 "Not Used" 7 "Error Indicator" ;
VAL_ 998 PDW_RrRtWrngLvlDis 0 "Off" 1 "1st warning" 2 "2nd warning" 3 "3rd warning" 4 "Error" 5 "Reseved" 6 "Not Used" 7 "Error Indicator" ;
VAL_ 998 PDW_RrSnsrWrngLvlSta 0 "Off" 1 "1st Waring" 2 "2nd Waring" 3 "3rd Warning" 4 "Reserved" 5 "Reseved" 6 "Not Used" 7 "Error Indicator" ;
VAL_ 1050 Lamp_ExtrnlTailLmpOnReq 0 "Off" 1 "On" 2 "Not Used" 3 "Error Indicator" ;
VAL_ 1050 Lamp_AvTailLmpSta 0 "Off" 1 "On" 2 "Not Used" 3 "Error Indicator" ;
VAL_ 1052 Lamp_AutoLtSnsrNightSta 0 "Off" 1 "Night" 2 "Not Used" 3 "Error Indicator" ;
VAL_ 1058 BCM_SunRoofOpnSta 0 "Close" 1 "Open" 2 "Not Used" 3 "Error Indicator" ;
VAL_ 1074 USM_EscrtHdLmpSta 0 "Default Value" 1 "Escort Off" 2 "Escort On" 3 "Invalid" 4 "Reserved" 5 "Reseved" 6 "Not Used" 7 "Error Indicator" ;
VAL_ 1074 USM_ArmBzrSta 0 "Default Value" 1 "Arm Disarm Buzzer Off" 2 "Arm Disarm Buzzer On" 3 "Invalid" 4 "Reserved" 5 "Reseved" 6 "Not Used" 7 "Error Indicator" ;
VAL_ 1074 USM_WlcmMirLtSystTitleOpt 0 "Default Value" 1 "Welcome Mirror Light" 2 "Welcome Mirror" 3 "Welcome Light" 4 "Reserved" 5 "Reseved" 6 "Not Used" 7 "Error Indicator" ;
VAL_ 1074 USM_UnlockWlcmSta 0 "Default Value" 1 "Off" 2 "On" 3 "Invalid" 4 "Reserved" 5 "Reseved" 6 "Not Used" 7 "Error Indicator" ;
VAL_ 1074 USM_SmrtWlcmSta 0 "Default Value" 1 "Off" 2 "On" 3 "Invalid" 4 "Reserved" 5 "Reseved" 6 "Not Used" 7 "Error Indicator" ;
VAL_ 1074 USM_RrWiperByGearPosRSta 0 "Default" 1 "Rear Wiper(reverse) Off" 2 "Rear Wiper(reverse) On" 3 "Invalid" 4 "Reserved" 5 "Reseved" 6 "Not Used" 7 "Error Indicator" ;
VAL_ 1074 USM_RrStRmndSta 0 "Default" 1 "Off(Disable)" 2 "On(Enable)" 3 "Invalid" 4 "Reserved" 5 "Reseved" 6 "Not Used" 7 "Error Indicator" ;
VAL_ 1074 USM_PDWAutoOnSta 0 "Default" 1 "Off" 2 "On" 3 "Invalid" 4 "Reserved" 5 "Reseved" 6 "Not Used" 7 "Error Indicator" ;
VAL_ 1138 USM_CluVcAlrmVolSta 0 "Default" 1 "Level0 (mute)" 2 "Level1" 3 "Level2" 4 "Level3" 5 "Reserved" 6 "Reserved" 7 "Invalid" ;
VAL_ 1138 USM_FuelEconomySetSta 0 "Default" 1 "Off" 2 "Driving" 3 "Refuel" 4 "Reserved" 5 "Reserved" 6 "Reserved" 7 "Invalid" ;
VAL_ 1138 USM_WelcomeSndSta 0 "Default" 1 "Off" 2 "On" 3 "Invalid" ;
VAL_ 1138 USM_CluDISWrngSta 0 "Default" 1 "Off" 2 "On" 3 "Invalid" ;
VAL_ 1138 USM_CluMFSWPopupSta 0 "Default" 1 "Off" 2 "On" 3 "Invalid" ;
VAL_ 1138 USM_CluGearPosPopupSta 0 "Default" 1 "Off" 2 "On" 3 "Invalid" ;
VAL_ 1138 USM_CluFuelEconUnitkmSta 0 "Default" 1 "km/L" 2 "L/100km" 3 "Reserved" ;
VAL_ 1138 USM_CluAdasVolSta 0 "Default" 1 "Level1" 2 "Level2" 3 "Level3" 4 "Reserved" 5 "Reserved" 6 "OFF" 7 "Invalid" ;
VAL_ 1138 USM_CluFuelEconUnitmiSta 0 "Default" 1 "US gallon" 2 "UK gallon" 3 "Reserved" ;
VAL_ 1138 USM_CluIcyRoadWarnSta 0 "Default" 1 "Off" 2 "On" 3 "Invalid" ;
VAL_ 1138 Wrn_Snd_AdasVolFdbck 0 "Default" 1 "level 1" 2 "level 2" 3 "level 3" 4 "Reserved" 5 "Reserved" 6 "Off" 7 "Invalid" ;
VAL_ 1139 USM_CluSrvRmndrMdeSta 0 "Default" 1 "Customer Mode" 2 "Workshop Mode" 3 "Invalid" ;
VAL_ 1139 USM_CluSrvRmndrSetSta 0 "Default" 1 "Off" 2 "On" 3 "Invalid" ;
VAL_ 1139 USM_CluSrvRmndrUnitSta 0 "Default" 1 "km" 2 "mile" 3 "Invalid" ;
VAL_ 1139 USM_CluSrvRmndrUsrSetPrdSta 0 "0~99" 1 "0~99" 2 "0~99" 3 "0~99" 4 "0~99" 5 "0~99" 6 "0~99" 7 "0~99" 8 "0~99" 9 "0~99" 10 "0~99" 11 "0~99" 12 "0~99" 13 "0~99" 14 "0~99" 15 "0~99" 16 "0~99" 17 "0~99" 18 "0~99" 19 "0~99" 20 "0~99" 21 "0~99" 22 "0~99" 23 "0~99" 24 "0~99" 25 "0~99" 26 "0~99" 27 "0~99" 28 "0~99" 29 "0~99" 30 "0~99" 31 "0~99" 32 "0~99" 33 "0~99" 34 "0~99" 35 "0~99" 36 "0~99" 37 "0~99" 38 "0~99" 39 "0~99" 40 "0~99" 41 "0~99" 42 "0~99" 43 "0~99" 44 "0~99" 45 "0~99" 46 "0~99" 47 "0~99" 48 "0~99" 49 "0~99" 50 "0~99" 51 "0~99" 52 "0~99" 53 "0~99" 54 "0~99" 55 "0~99" 56 "0~99" 57 "0~99" 58 "0~99" 59 "0~99" 60 "0~99" 61 "0~99" 62 "0~99" 63 "0~99" 64 "0~99" 65 "0~99" 66 "0~99" 67 "0~99" 68 "0~99" 69 "0~99" 70 "0~99" 71 "0~99" 72 "0~99" 73 "0~99" 74 "0~99" 75 "0~99" 76 "0~99" 77 "0~99" 78 "0~99" 79 "0~99" 80 "0~99" 81 "0~99" 82 "0~99" 83 "0~99" 84 "0~99" 85 "0~99" 86 "0~99" 87 "0~99" 88 "0~99" 89 "0~99" 90 "0~99" 91 "0~99" 92 "0~99" 93 "0~99" 94 "0~99" 95 "0~99" 96 "0~99" 97 "0~99" 98 "0~99" 99 "0~99" ;
VAL_ 1139 USM_CluSrvRmndrUsrSetDstSta 0 "0x0x00000~0x1869F:0~99999" 99999 "0x0x00000~0x1869F:0~99999" ;
VAL_ 1139 Clu_SrvRmndrAlrm 0 "Default" 1 "Service Alarm (Period)" 2 "Service Alarm (Distance)" 3 "Service Alarm (Period & Distance)" ;
VAL_ 1140 USM_CluSrvRmndrRemainPrdSta 0 "0x0x0000~0x270F:0~9999" 9999 "0x0x0000~0x270F:0~9999" ;
VAL_ 1140 USM_CluSrvRmndrRemainDstSta 0 "0x0x00000~0x1869F:0~9999" 99999 "0x0x00000~0x1869F:0~9999" ;
VAL_ 325 DATC_OutTempSnsrVal 255 "Error" ;
VAL_ 898 DATC_TempDispUnitSta 0 "Centigrade(℃)" 1 "Fahrenheit(℉)" 2 "Not used" 3 "Error Indicator" ;
VAL_ 181 ENG_IsgSta 0 "ISG is not operating Normal engine operating without ISG" 1 "Idle stop is activated Idle is stopped by ECU during driving" 2 "Automatically started by ECU Engine is automatically started by ECU regardless driver’s volition during idle stop because the condition that ISG function to be prohibited is satisfied, for example SOC is too low." 3 "ISG is prohibited Driver prohibits to activate ISG in order to avoid start lag when he met traffic jam for example." 4 "Fault  existing in ISG. Idle stop is prohibited and engine started automatically if it is idle stop condition." 5 "Idle stop is inhibited by system automatically for safety and  convenient condition related with battery SOC, brake vacuum pressure etc. ISG function check for EOL." 6 "Auto start is deactivated system automatically to keep safety, Such as door open, hood open and seat belt unlock." 7 "If driver shift gear N to D range without braking to make auto starting. (Economy ISG Only)" ;
VAL_ 181 ENG_GearShftUpDis 0 "Gear Shiftup Display Off" 1 "Gear Shiftup Display On" 2 "Not used" 3 "Error indicator" ;
VAL_ 181 ENG_GearShftDnDis 0 "Gear Shiftdown Display Off" 1 "Gear Shiftdown Display On" 2 "Not used" 3 "Error indicator" ;
VAL_ 181 ENG_DsrGearPosDis 0 "No display" 1 "Gear Position 1 display" 2 "Gear Position 2 display" 3 "Gear Position 3 display" 4 "Gear Position 4 display" 5 "Gear Position 5 display" 6 "Gear Position 6 display" 7 "Gear Position 7 display" 8 "Gear Position 8 display" 9 "Gear Position 9 display" 10 "Gear Position 10 display" 15 "Error indicator" ;
VAL_ 181 ENG_IsgBzrReq 0 "Request buzzer OFF" 1 "Request buzzer ON" 2 "Not used" 3 "Error indicator" ;
VAL_ 181 ENG_Isg2Sta 0 "Default" 1 "The condition for not-activated battery sensor. (Except EOL condition.)" 2 "In Auto Start status, when rapidly accelerating before complete gear shift. (Economy ISG Only)" 3 "Error indicator" ;
VAL_ 181 ENG_VehSpdLimVal 511 "Error indicator" ;
VAL_ 181 ENG_EngSpdErrSta 0 "No error" 1 "Engine speed sensor defective" 2 "Not used" 3 "Error indicator" ;
VAL_ 608 ENG_KNK_Warning 0 "OFF" 1 "ON" ;
VAL_ 608 ENG_ImmoLmpSta 0 "Immobilizer lamp OFF" 1 "Immobilizer lamp ON" ;
VAL_ 608 ENG_MilSta 0 "Check Engine lamp OFF" 1 "Check Engine lamp ON" ;
VAL_ 496 EPB_LmpStaDis 0 "Release State (EPB AVH)" 1 "Apply State (EPB)" 2 "Dynamic Braking (EPB) or Driver Action Requested" ;
VAL_ 496 EPB_FlrLmpStaDis 0 "No failure" 1 "Failure detected or in diagnosis mode" 2 "EOL configuration not done or Emergency released" 3 "Reserved" 4 "Reserved" 5 "Reserved" 6 "Reserved" 7 "Reserved" 8 "Reserved" 9 "Reserved" 10 "Reserved" 11 "Reserved" 12 "Reserved" 13 "Reserved" 14 "Not used" 15 "Error Indicator" ;
VAL_ 496 EPB_OutDataDis 0 "Off" 1 "EPB is in maintenance mode" 2 "Driver tries to DAR but safety condition is not satisfied" 3 "EPB applies by ESC request" 4 "Driver tries to DAR but safety condition is not satisfied for China" ;
VAL_ 496 EPB_AlrmReq 0 "Off" 1 "Comfortable tone (Sound once)" 2 "Uncomfortable tone" 3 "Error Indicator" ;
VAL_ 96 AVH_CluDis 0 "AVH is off" 1 "AUTO HOLD to be deactivated Press Brake Pedal" 2 "Press Brake Pedal to Release AUTO HOLD" 3 "AUTO HOLD cannot be activated Close Door, Hood, Trunk" 4 "AUTO HOLD cannot be deactivated, Close Door" ;
VAL_ 96 AVH_AlrmReq 0 "No alarm" 1 "On AVH Activation, Vehicle is not secured and driver is still inside = comfortable tone" 2 "Not used" 3 "Error Indicator" ;
VAL_ 96 AVH_LmpDis 0 "AVH Off (Lamp Status" 1 "AVH failure (Lamp Status" 2 "AVH ACTIVE (Lamp Status" 3 "AVH READY (Lamp Status" 4 "Lamp Status" 5 "Lamp Status" 6 "Lamp Status" ;
VAL_ 96 TCS_LmpSta 0 "TCS/ESC Function/Warning Lamp OFF" 1 "TCS/ESC Function/Warning Lamp ON" 2 "TCS/ESC Function/Warning Lamp BLINKING(2Hz)" 3 "Error Indicator" ;
VAL_ 96 TCS_OffLmpSta 0 "TCS/ESC OFF SW Lamp OFF" 1 "TCS/ESC OFF SW Lamp ON" 2 "Not used" 3 "Error Indicator" ;
VAL_ 96 ESC_OffTempSta 0 "Normal Mode" 1 "Sports Mode" 2 "Off Mode" 3 "ESC OFF SW is defective (failed)" ;
VAL_ 96 DBC_WrngLmpSta 0 "DBC Warning lamp OFF" 1 "DBC Warning lamp ON" 2 "Not used" 3 "Error Indicator" ;
VAL_ 96 DBC_FuncLmpSta 0 "DBC Function lamp OFF" 1 "DBC Function lamp ON" 2 "DBC Function lamp BLINKING(2Hz)" 3 "Error Indicator" ;
VAL_ 96 DBC_ClusterDis 0 "DBC Enabled" 1 "DBC Disabled by system fault" 2 "Reserved" 3 "Reserved" ;
VAL_ 96 DBC_Sta 0 "Not Applied" 1 "Off" 2 "Ready" 3 "Activated" 4 "Reserved" 5 "Reserved" 6 "Reserved" 7 "Reserved" 8 "Reserved" 9 "Reserved" 10 "Reserved" 11 "Reserved" 12 "Reserved" 13 "Reserved" 14 "Not Coded" 15 "Defective" ;
VAL_ 1160 Lamp_LtSwSta_IBU 0 "Light Sw Off" 1 "Tail Sw On" 2 "HeadLamp Low Sw On" 3 "AutoLight Sw On" ;
VAL_ 1161 Wiper_FrWiperSwSta_IBU 0 "Wiper Sw Off" 1 "Wiper Int or Auto Sw On(Refer to C_RainSnsOption)" 2 "Wiper Low Sw On" 3 "Wiper High Sw On" 4 "Reserved" 5 "Reserved" 6 "Not Used" 7 "Error Indicator" ;
VAL_ 1161 Wiper_IntStepSta_IBU 0 "STEP1(SLOW)" 1 "STEP2" 2 "STEP3" 3 "STEP4" 4 "STEP5(FAST)" ;
VAL_ 1161 Wiper_RrWiperSwSta_IBU 0 "Rear Wiper Sw Off" 1 "Rear Wiper Low Sw On" 2 "Rear Wiper High Sw On" 3 "Reserved" ;
VAL_ 1041 Warn_DrvDrSwSta 0 "Close" 1 "Open" 2 "Not Used" 3 "Error Indicator" ;
VAL_ 1041 Warn_AsstDrSwSta 0 "Close" 1 "Open" 2 "Not Used" 3 "Error Indicator" ;
VAL_ 1041 Warn_BrkFldSwSta 0 "Off" 1 "On" 2 "Not Used" 3 "Error Indicator" ;
VAL_ 1041 Warn_HoodSwSta 0 "Off" 1 "On" 2 "Not Used" 3 "Error Indicator" ;
VAL_ 1041 Warn_PrkngBrkSwSta 0 "Off" 1 "On" 2 "Not Used" 3 "Error Indicator" ;
VAL_ 1041 Warn_RrLftDrSwSta 0 "Close" 1 "Open" 2 "Not Used" 3 "Error Indicator" ;
VAL_ 1041 Warn_RrRtDrSwSta 0 "Close" 1 "Open" 2 "Not Used" 3 "Error Indicator" ;
VAL_ 1042 ExtLamp_StpLmpLftOpnSta 0 "Normal" 1 "Open Status" 2 "Not Used" 3 "Error Indicator" ;
VAL_ 1042 ExtLamp_StpLmpRtOpnSta 0 "Normal" 1 "Open Status" 2 "Not Used" 3 "Error Indicator" ;
VAL_ 1043 ExtLamp_TrnSigLmpLftBlnkngSta 0 "Off" 1 "On" 2 "Not Used" 3 "Error Indicator" ;
VAL_ 1043 ExtLamp_TrnSigLmpRtBlnkngSta 0 "Off" 1 "On" 2 "Not Used" 3 "Error Indicator" ;
VAL_ 1043 ExtLamp_ExtrnlTailLmpSta 0 "Off" 1 "On" 2 "Not Used" 3 "Error Indicator" ;
VAL_ 1043 ExtLamp_RrFgLmpSta 0 "Off" 1 "On" 2 "Not Used" 3 "Error Indicator" ;
VAL_ 1043 Lamp_LedHdLmpSta 0 "LED Headlamp is in nornal condition" 1 "Reserved" 2 "LED Fail" 3 "Reserved" ;
VAL_ 1044 Trunk_TrnkTlgtSwSta 0 "Close(Full Lock)" 1 "Open(Not Full Lock)" 2 "Not Used" 3 "Error Indicator" ;
VAL_ 1044 USM_OneTouchTrnSigFuncSta 0 "Default" 1 "One Touch Turn Off" 2 "3 Flashing" 3 "5 Flashing" 4 "7 Flashing" 5 "Invalid" ;
VAL_ 1046 Lamp_HdLmpLoLftOpnSta 0 "Normal" 1 "Open Status" 2 "Not Used" 3 "Error Indicator" ;
VAL_ 1046 Lamp_HdLmpLoRtOpnSta 0 "Normal" 1 "Open Status" 2 "Not Used" 3 "Error Indicator" ;
VAL_ 1046 Lamp_HdLmpHiLftOpnSta 0 "Normal" 1 "Open Status" 2 "Not Used" 3 "Error Indicator" ;
VAL_ 1046 Lamp_HdLmpHiRtOpnSta 0 "Normal" 1 "Open Status" 2 "Not Used" 3 "Error Indicator" ;
VAL_ 1046 Lamp_RrTrnSigLmpLftOpnSta 0 "Normal" 1 "Open Status" 2 "Not Used" 3 "Error Indicator" ;
VAL_ 1046 Lamp_RrTrnSigLmpRtOpnSta 0 "Normal" 1 "Open Status" 2 "Not Used" 3 "Error Indicator" ;
VAL_ 1046 Lamp_FrTrnSigLmpLftOpnSta 0 "Normal" 1 "Open Status" 2 "Not Used" 3 "Error Indicator" ;
VAL_ 1046 Lamp_FrTrnSigLmpRtOpnSta 0 "Normal" 1 "Open Status" 2 "Not Used" 3 "Error Indicator" ;
VAL_ 1047 USM_AutoDrLkReq 0 "Default" 1 "Off" 2 "Vehicle Speed On(15km)" 3 "Shift Lever On" 4 "Invalid" ;
VAL_ 1047 USM_AutoDrUnLkReq 0 "Default" 1 "Off" 2 "Key Out On (AllDoors)" 3 "Shift Lever On (AllDoors)" 4 "Override" 5 "Invalid" 6 "Key Out On (Driver Door)" 7 "Shift Lever On (Driver Door)" ;
VAL_ 1047 USM_TwoTrnUnLkCurrentSta 0 "Default" 1 "Ttunlock Off" 2 "Ttunlock On" 3 "Invalid" ;
VAL_ 1047 Lamp_HdLmpHiSta 0 "Off" 1 "On" 2 "Not Used" 3 "Error Indicator" ;
VAL_ 1047 Lamp_HdLmpLoSta 0 "Off" 1 "On" 2 "Not Used" 3 "Error Indicator" ;
VAL_ 1047 Lamp_HdLmpBiFuncLftOpnSta 0 "Normal" 1 "Open Status" 2 "Not Used" 3 "Error Indicator" ;
VAL_ 1047 Lamp_HdLmpBiFuncRtOpnSta 0 "Normal" 1 "Open Status" 2 "Not Used" 3 "Error Indicator" ;
VAL_ 1048 DriveTypeOption 0 "Left Handle Drive Type" 1 "Right Handle Drive Type" 3 "Error Indicator" ;
VAL_ 1048 Warn_LftSEA 0 "SEA Left Warning OFF" 1 "SEA Left Warning ON" 2 "Reserved" 3 "Invalid" ;
VAL_ 1048 Warn_RhtSEA 0 "SEA Right Warning OFF" 1 "SEA Right Warning ON" 2 "Reserved" 3 "Invalid" ;
VAL_ 1048 ICU_PowerAutoCutModSta 0 "Factory Mode (default)" 1 "Dealer Mode" 2 "Customer Mode" 3 "Error Indicator" ;
VAL_ 1167 Bat_dischrg 0 "Flag OFF" 1 "Flag ON" ;
VAL_ 234 MDPS_LoamModSta 0 "Normal" 1 "Loam Flag Warning Display" 2 "Not Used" 3 "Error Indicator" ;
VAL_ 234 MDPS_WrngLmpSta 0 "MDPS Malfunction Warning lamp OFF" 1 "MDPS Malfunciton Warning lamp BLANKING(2Hz)" 2 "MDPS Malfunction Warning lamp ON" 3 "MDPS Malfunction Warning lamp BLANKING(1Hz)" 4 "RESERVED" 5 "RESERVED" 6 "Not Used" 7 "Error Indicator" ;
VAL_ 485 RCCW_Sta 0 "Default" 1 "RCCW is Off" 2 "RCCW Passive" 3 "RCCW Active" 4 "RCCW Failure" 5 "RCCW Blockage" 6 "RCCW Minor Failure" 7 "Reserved" 8 "Reserved" 9 "Reserved" 10 "Reserved" 11 "Reserved" 12 "Reserved" 13 "Reserved" 14 "Reserved" ;
VAL_ 485 RCCW_OnOffEquipSt 0 "Default" 1 "Off" 2 "Warning" 3 "Invalid" ;
VAL_ 485 RCCW_LftIndSta 0 "Indicator output off" 1 "Indicator on (information)" 2 "Reserved" 3 "Indicator output check" ;
VAL_ 485 RCCW_RtIndSta 0 "Indicator output off" 1 "Indicator on (information)" 2 "Reserved" 3 "Indicator output check" ;
VAL_ 485 RCCW_LftSndWrngSta 0 "Speaker is Off" 1 "Speaker On" 2 "Not used" 3 "Error Indicator" ;
VAL_ 485 RCCW_RtSndWrngSta 0 "Speaker is Off" 1 "Speaker On" 2 "Not used" 3 "Error Indicator" ;
VAL_ 485 RCCA_LftWrngSta 0 "RCCA Left Warning is Off" 1 "RCCA Left Warning is On" 2 "RCCA Left Warning is Ended" 3 "Error Indicator" ;
VAL_ 485 RCCA_RtWrngSta 0 "RCCA Right Warning is Off" 1 "RCCA Right Warning is On" 2 "RCCA Right Warning is Ended" 3 "Error Indicator" ;
VAL_ 485 RCCA_FuncStat 0 "ESC Normal" 1 "Not support (ESC failure)" 2 "Not used" 3 "Error Indicator" ;
VAL_ 485 RCCA_Sta 0 "Default" 1 "RCCA is Off" 2 "RCCA Passive" 3 "RCCA Active" 4 "RCCA Failure" 5 "RCCA Blockage" 6 "RCCA Minor Failure" 7 "Reserved" 8 "Reserved" 9 "Reserved" 10 "Reserved" 11 "Reserved" 12 "Reserved" 13 "Reserved" 14 "Reserved" ;
VAL_ 485 RCCA_OnOffEquipSt 0 "Default" 1 "Off" 2 "Assist" 3 "Invalid" ;
VAL_ 485 SEA_Sta 0 "Default" 1 "SEA Function is off" 2 "SEA Function is passive" 3 "SEA Function active" 4 "SEA Function failure" 5 "SEA Function Blockage" 6 "SEA Function minor failure" 7 "Reserved" 8 "Reserved" 9 "Reserved" 10 "Reserved" 11 "Reserved" 12 "Reserved" 13 "Reserved" 14 "Reserved" ;
VAL_ 485 SEA_OnOffEquipSta 0 "Default" 1 "Off" 2 "Warning" 3 "Invalid" ;
VAL_ 485 SEA_LftWrngSta 0 "SEA Left Warning OFF" 1 "SEA Left Warning ON" 2 "Not used" 3 "Error Indicator" ;
VAL_ 485 SEA_RtWrngSta 0 "SEA Right Warning OFF" 1 "SEA Right Warning ON" 2 "Not used" 3 "Error Indicator" ;
VAL_ 346 SCU_FF_PosActSta 0 "P" 1 "Reserved" 2 "Reserved" 3 "Reserved" 4 "Reserved" 5 "D" 6 "N" 7 "R" 8 "Reserved" 9 "Initial(Not Display at Cluster)" 10 "Reserved" 11 "Reserved" 12 "Reserved" 13 "Reserved" 14 "Intermediated Position" 15 "Unknown signal Detecting" ;
VAL_ 1061 Warn_DeActvWrngSta 0 "Off" 1 "On" 2 "Not Used" 3 "Error Indicator" ;
VAL_ 1061 Warn_DisWrngSta 0 "Off" 1 "Shift_P_Warning" 2 "Key_Bat_Discharge_Warning" 3 "Not_Unlocked_Warning" 4 "AC_Plug_Connected_Warning" 5 "Escl_Ecu_Fail_Warning" 6 "Engine_Start_Operation_IND" 7 "Auth_Fail_Warning" 8 "Key_Removal_IND" 9 "SMK_Lamp_Warning" 10 "SSB_Warning" 11 "Auth_Fail_Warning2" 12 "Vehicle_Not_P_Warning" 13 "Stop Lamp Fuse Fail Warning" 14 "Not P_N Warning" 15 "Reserved" 16 "Reserved" 17 "Reserved" 18 "Reserved" 19 "Reserved" 20 "Reserved" 21 "Reserved" 22 "Reserved" 23 "Reserved" 24 "Reserved" 25 "Reserved" 26 "Reserved" 27 "Reserved" 28 "Reserved0x1D:Reserved" 30 "Not Used" 31 "Error Indicator" ;
VAL_ 1061 Warn_IdOutWrngSta 0 "Off" 1 "On" 2 "Not Used" 3 "Error Indicator" ;
VAL_ 1061 Warn_KeyBattLoWrngSta 0 "Off" 1 "On" 2 "Not Used" 3 "Error Indicator" ;
VAL_ 1061 Warn_ImmoLmpOnReq 0 "Off" 1 "On" 2 "Not Used" 3 "Error Indicator" ;
VAL_ 64 TCU_EngRpmDis 65535 "Error Indicator" ;
VAL_ 64 TCU_SprtyIndxSta 0 "Invalid" 1 "Step 1" 2 "Step 2" 3 "Step 3" 4 "Step 4" 5 "Step 5" 6 "Step 6" 7 "Step 7" 8 "Step 8" 9 "Step 9" 10 "Step 10" 11 "Step 11" 12 "Step 12" 13 "Step 13" 14 "Step 14" 15 "Step 15" 16 "Step 16" 17 "Step 17" 18 "Step 18" 19 "Step 19" 20 "Step 20" 21 "Step 21" 22 "Step 22" 23 "Step 23" 24 "Step 24" 25 "Step 25" 26 "Invalid" 27 "Invalid" 28 "Invalid" 29 "Invalid" 30 "Invalid" 31 "Invalid" ;
VAL_ 64 TCU_DrvngModDis 0 "Inactive" 1 "Normal" 2 "Eco" 3 "Eco+" 4 "Sport" 5 "Sport+" 6 "Snow" 7 "Reserved" ;
VAL_ 64 TCU_SmrtShftSta 0 "Smart Shift not Applied" 1 "Smart Shift Applied" 2 "Not used" 3 "Error Indicator" ;
VAL_ 64 TCU_ShftPtrnSta 0 "Normal (ECO)" 1 "Uphill 1 (Optional)" 2 "Uphill 2 (Optional)" 3 "Reserved" 4 "Downhill 1 (Optional)" 5 "Cruise (Optional)" 6 "Cruise_Uphill 1 (Optional)" 7 "Cruise_Uphill 2 (Optional)" 8 "Active ECO (Optional)" 9 "Sport Drive (Optional)" 15 "None of the above" ;
VAL_ 64 TCU_GearSlctDis 0 "P" 1 "L" 2 "2" 3 "3" 4 "DS Mode" 5 "D" 6 "N" 7 "R" 8 "sports mode / manual shift / paddle shift" 9 "Not Display at Cluster" 10 "Sub-Rom Communication" 11 "Sub-Rom Communication Error" 12 "Paddle shift (D-position)" 13 "Reserved" 14 "Intermediate Position" 15 "fault" ;
VAL_ 64 TCU_Typ 0 "Reserved" 1 "Step A" 2 "CVT" 3 "DCT" 4 "AMT" 5 "eClutch (2pedal)" 6 "eClutch (3pedal)" ;
VAL_ 64 TCU_TqRdctnVal 0 "Max. reduction" 2047 "No reduction" ;
VAL_ 64 TCU_GearStepTyp 3 "3 - Speed A/T or DCT" 4 "4 - Speed A/T or DCT" 5 "5 - Speed A/T or DCT" 6 "6 - Speed A/T or DCT" ;
VAL_ 64 TCU_GearShftSta 0 "no gear change" 1 "gear change is active" 2 "Not used" 3 "Error Indicator" ;
VAL_ 64 TCU_CurrGearSta 0 "if N or P are detected (no frictional connection)" 1 "1st speed" 2 "2nd speed" 3 "3rd speed" 4 "4th speed" 5 "5th speed" 6 "6th speed" 7 "7th speed" 8 "8th speed" 14 "Reverse speed" ;
VAL_ 64 TCU_TrgtGearSta 0 "if N or P are detected (no frictional connection)" 1 "1st speed" 2 "2nd speed" 3 "3rd speed" 4 "4th speed" 5 "5th speed" 6 "6th speed" 7 "7th speed" 8 "8th speed" 14 "Reverse speed" ;
VAL_ 64 TCU_CluTrgtGearSta 0 "if N or P are detected (no frictional connection)" 1 "1st speed" 2 "2nd speed" 3 "3rd speed" 4 "4th speed" 5 "5th speed" 6 "6th speed" 7 "7th speed" 8 "8th speed" 14 "Reverse speed" ;
VAL_ 64 TCU_CluTrgtGearConfg 0 "TCU_TrgtGearSta" 1 "TCU_CluTrgtGearSta" 2 "Not Used" 3 "Error Indicator" ;
VAL_ 106 TCU_ActvEcoRdySta 0 "Not Ready" 1 "Ready" 2 "Not used" 3 "Error Indicator" ;
VAL_ 720 TCU_WrngMsgSta 0 "No Warning message" 1 "Warning message 1" 2 "Warning message 2" 3 "Warning message 3" 4 "Warning message 4" ;
VAL_ 720 TCU_CurCltTemp 0 "Green" 1 "Yellow" 2 "Red" 3 "Black" ;
VAL_ 720 TCU_AvgCltTemp 0 "Normal" 1 "Normal" 2 "Normal" 3 "Normal" 4 "Normal" 5 "Normal" 6 "Normal" 7 "Normal" 8 "Normal" 9 "Normal" 10 "Warning" 11 "Warning" 12 "Warning" 13 "Warning" 14 "Emergency" 15 "Emergency" ;
VAL_ 720 DCT_HillHldWrng 0 "No Warning" 1 "Hill Hold Warning" 2 "Not Used" 3 "Error Indicator" ;
VAL_ 720 DCT_CltchBrstWrng 0 "No Warning" 1 "Clutch Burst Warning" 2 "Not Used" 3 "Error Indicator" ;
